VERSION "created by canmatrix"

NS_ :

BS_:

BU_: DiagTool_OBD1 DiwaNXT EBS IRCS MulticII NBM VCM ETS NODE_45 FCCU DICO SGW2 HV_BOX ADCU AEBS DTCO MBMS SGW TPMS ACU CAID2 ELC5_Fr ELC5_Rr PredictiveVirtualNode2 BPU_3 Servo_dir_Turolla PCM NODE_90 NODE_91 NODE_92 RSRRM FCU DSE_VirtualNode2 DSE_VirtualNode40 DSE_VirtualNode38 DSE_VirtualNode49 DSE_VirtualNode48 DSE_VirtualNode39 DSE_VirtualNode37 DSE_VirtualNode36 BSM_B8 BPU_2 DSE_VirtualNode35 DSE_VirtualNode34 RADAR_ACC DSE_VirtualNode33 DSE_VirtualNode41 NODE_BE DSE_VirtualNode32 DSE_VirtualNode4 BSM_C0 BPU_1 DSE_VirtualNode31 DSE_VirtualNode29 DSE_VirtualNode28 MCDS DSE_VirtualNode44 DSE_VirtualNode27 DSE_VirtualNode26 BSM_C8 ALM DSE_VirtualNode25 DSE_VirtualNode50 DSE_VirtualNode47 DSE_VirtualNode46 DSE_VirtualNode23 DSE_VirtualNode51 ScanTool DSE_VirtualNode22 DSE_VirtualNode21 AePTO DC_VirtualNode1 DSE_VirtualNode43 MCSL DSE_VirtualNode1 DSE_VirtualNode42 PredictiveVirtualNode3 DSE_VirtualNode20 DSE_VirtualNode19 DSE_VirtualNode18 DSE_VirtualNode17 DSE_VirtualNode16 DSE_VirtualNode15 NODE_F9 DiagTool DSE_VirtualNode14 DSE_VirtualNode13 DSE_VirtualNode12 DSE_VirtualNode11 DSE_VirtualNode10 DSE_VirtualNode9 DSE_VirtualNode8 DSE_VirtualNode7 DSE_VirtualNode6 Mirror DSE_VirtualNode5 SAS DC_VirtualNode2 PredictiveVirtualNode1 DSE_VirtualNode45 ELFA3 EM_PTO RM CANAIR SWI

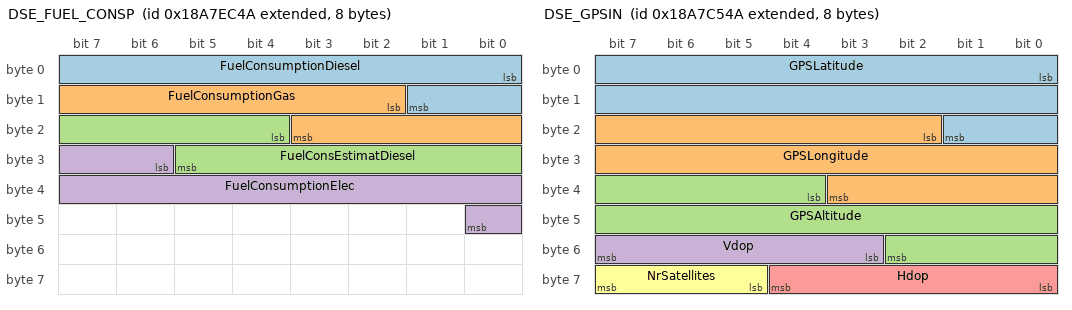
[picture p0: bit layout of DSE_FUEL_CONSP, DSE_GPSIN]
BO_ 2561141834 DSE_FUEL_CONSP: 8 PCM
 SG_ FuelConsumptionDiesel : 0|10@1+ (0.1,-1) [-1|101] "L/100km"  MCDS
 SG_ FuelConsumptionGas : 10|10@1+ (0.1,-1) [-1|101] "Kg/100km"  MCDS
 SG_ FuelConsEstimatDiesel : 20|10@1+ (0.1,-1) [-1|101] "L/100km"  MCDS
 SG_ FuelConsumptionElec : 30|11@1+ (0.1,-1) [-1|203] "kWh/100km"  MCDS

BO_ 2561131850 DSE_GPSIN: 8 PCM
 SG_ GPSLatitude : 0|18@1- (0.001,0) [-131|131] ""  DSE_VirtualNode44
 SG_ GPSLongitude : 18|18@1- (0.0015,0) [-196|196] ""  DSE_VirtualNode44
 SG_ GPSAltitude : 36|15@1+ (0.2,-500) [-500|5797] ""  DSE_VirtualNode44
 SG_ Vdop : 51|5@1+ (1,0) [0|25] ""  DSE_VirtualNode44
 SG_ Hdop : 56|5@1+ (1,0) [0|25] ""  DSE_VirtualNode44
 SG_ NrSatellites : 61|3@1+ (1,0) [0|7] ""  DSE_VirtualNode44

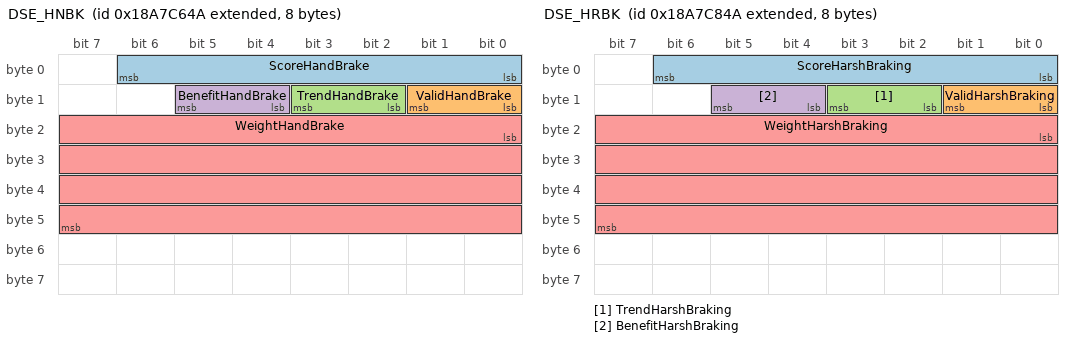
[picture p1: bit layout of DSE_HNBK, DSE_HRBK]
BO_ 2561132106 DSE_HNBK: 8 PCM
 SG_ ScoreHandBrake : 0|7@1+ (1,-1) [-1|126] "Index"  DSE_VirtualNode27
 SG_ ValidHandBrake : 8|2@1+ (1,0) [0|3] ""  DSE_VirtualNode27
 SG_ TrendHandBrake : 10|2@1+ (1,-1) [-1|2] ""  DSE_VirtualNode27
 SG_ BenefitHandBrake : 12|2@1+ (1,0) [0|3] ""  DSE_VirtualNode27
 SG_ WeightHandBrake : 16|32@1+ (1,-1) [-1|4294967294] ""  DSE_VirtualNode27

BO_ 2561132362 DSE_HNBK_DBG: 8 PCM
 SG_ NumEventsHandBrake : 0|16@1+ (1,-1) [-1|65534] ""  DSE_VirtualNode26
 SG_ EventHandBrake : 16|2@1+ (1,0) [0|3] ""  DSE_VirtualNode26

BO_ 2561132618 DSE_HRBK: 8 PCM
 SG_ ScoreHarshBraking : 0|7@1+ (1,-1) [-1|126] "Index"  BSM_C8
 SG_ ValidHarshBraking : 8|2@1+ (1,0) [0|3] ""  BSM_C8
 SG_ TrendHarshBraking : 10|2@1+ (1,-1) [-1|2] ""  BSM_C8
 SG_ BenefitHarshBraking : 12|2@1+ (1,0) [0|3] ""  BSM_C8
 SG_ WeightHarshBraking : 16|32@1+ (1,-1) [-1|4294967294] ""  BSM_C8

BO_ 2561132874 DSE_HRBK_DBG: 8 PCM
 SG_ EvalMetersHarshBraking : 0|16@1+ (1,-1) [-1|65534] "m"  ALM
 SG_ EventHarshBraking : 16|2@1+ (1,0) [0|3] ""  ALM
 SG_ MaxDecelHarshBraking : 18|6@1+ (1,0) [0|63] "kmh/s"  ALM

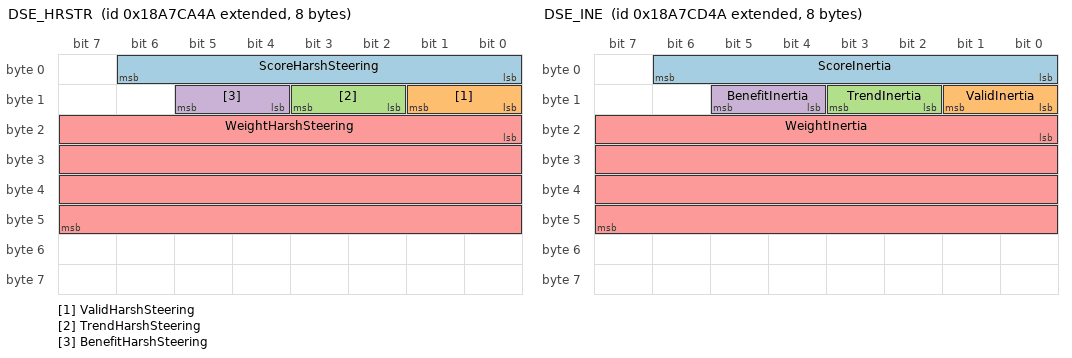
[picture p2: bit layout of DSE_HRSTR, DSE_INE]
BO_ 2561133130 DSE_HRSTR: 8 PCM
 SG_ ScoreHarshSteering : 0|7@1+ (1,-1) [-1|126] "Index"  DSE_VirtualNode25
 SG_ ValidHarshSteering : 8|2@1+ (1,0) [0|3] ""  DSE_VirtualNode25
 SG_ TrendHarshSteering : 10|2@1+ (1,-1) [-1|2] ""  DSE_VirtualNode25
 SG_ BenefitHarshSteering : 12|2@1+ (1,0) [0|3] ""  DSE_VirtualNode25
 SG_ WeightHarshSteering : 16|32@1+ (1,-1) [-1|4294967294] ""  DSE_VirtualNode25

BO_ 2561133386 DSE_HRSTR_DBG: 8 PCM
 SG_ EvalMetersHarshSteering : 0|16@1+ (1,-1) [-1|65534] "m"  DSE_VirtualNode50
 SG_ EventHarshSteering : 16|2@1+ (1,0) [0|3] ""  DSE_VirtualNode50

BO_ 2561133898 DSE_INE: 8 PCM
 SG_ ScoreInertia : 0|7@1+ (1,-1) [-1|126] "Index"  DSE_VirtualNode47
 SG_ ValidInertia : 8|2@1+ (1,0) [0|3] ""  DSE_VirtualNode47
 SG_ TrendInertia : 10|2@1+ (1,-1) [-1|2] ""  DSE_VirtualNode47
 SG_ BenefitInertia : 12|2@1+ (1,0) [0|3] ""  DSE_VirtualNode47
 SG_ WeightInertia : 16|32@1+ (1,-1) [-1|4294967294] ""  DSE_VirtualNode47

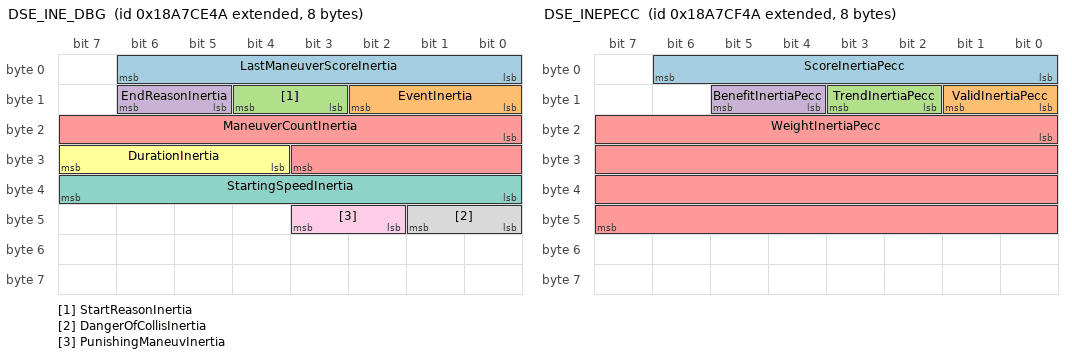
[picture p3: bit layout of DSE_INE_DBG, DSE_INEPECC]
BO_ 2561134154 DSE_INE_DBG: 8 PCM
 SG_ LastManeuverScoreInertia : 0|7@1+ (1,-1) [-1|126] "Index"  DSE_VirtualNode46
 SG_ EventInertia : 8|3@1+ (1,0) [0|7] ""  DSE_VirtualNode46
 SG_ StartReasonInertia : 11|2@1+ (1,0) [0|3] ""  DSE_VirtualNode46
 SG_ EndReasonInertia : 13|2@1+ (1,0) [0|3] ""  DSE_VirtualNode46
 SG_ ManeuverCountInertia : 16|12@1+ (1,-1) [-1|4094] "Count"  DSE_VirtualNode46
 SG_ DurationInertia : 28|4@1+ (1,-1) [-1|14] "s"  DSE_VirtualNode46
 SG_ StartingSpeedInertia : 32|8@1+ (0.5,0) [0|125] "km/h"  DSE_VirtualNode46
 SG_ DangerOfCollisInertia : 40|2@1+ (1,0) [0|3] ""  DSE_VirtualNode46
 SG_ PunishingManeuvInertia : 42|2@1+ (1,0) [0|3] ""  DSE_VirtualNode46

BO_ 2561134410 DSE_INEPECC: 8 PCM
 SG_ ScoreInertiaPecc : 0|7@1+ (1,-1) [-1|126] "Index"  DSE_VirtualNode23
 SG_ ValidInertiaPecc : 8|2@1+ (1,0) [0|3] ""  DSE_VirtualNode23
 SG_ TrendInertiaPecc : 10|2@1+ (1,-1) [-1|2] ""  DSE_VirtualNode23
 SG_ BenefitInertiaPecc : 12|2@1+ (1,0) [0|3] ""  DSE_VirtualNode23
 SG_ WeightInertiaPecc : 16|32@1+ (1,-1) [-1|4294967294] ""  DSE_VirtualNode23

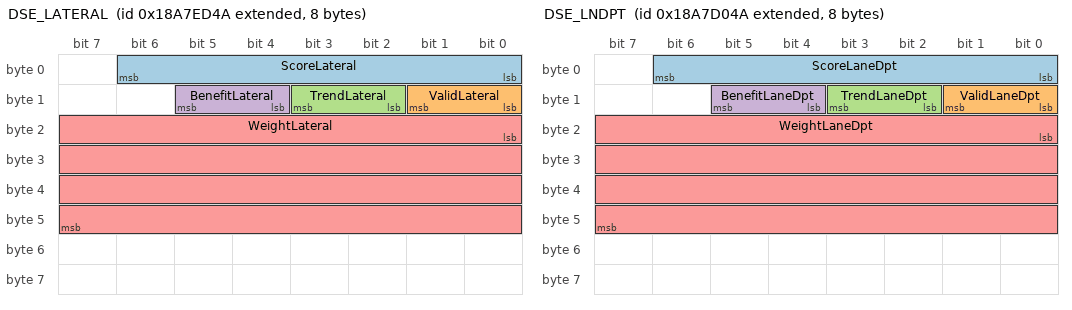
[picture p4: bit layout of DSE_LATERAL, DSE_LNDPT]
BO_ 2561142090 DSE_LATERAL: 8 PCM
 SG_ ScoreLateral : 0|7@1+ (1,0) [0|100] "%"  DSE_VirtualNode51
 SG_ ValidLateral : 8|2@1+ (1,0) [0|3] ""  DSE_VirtualNode51
 SG_ TrendLateral : 10|2@1+ (1,-1) [-1|2] ""  DSE_VirtualNode51
 SG_ BenefitLateral : 12|2@1+ (1,0) [0|3] ""  DSE_VirtualNode51
 SG_ WeightLateral : 16|32@1+ (1,-1) [-1|4294967294] ""  DSE_VirtualNode51

BO_ 2561143114 DSE_LATERAL_DBG: 8 PCM
 SG_ NumEventsLateral : 0|16@1+ (1,-1) [-1|65534] "Count"  ScanTool
 SG_ EvaluatedMetersLateral : 16|16@1+ (1,-1) [-1|65534] "m"  ScanTool

BO_ 2561134666 DSE_LNDPT: 8 PCM
 SG_ ScoreLaneDpt : 0|7@1+ (1,-1) [-1|126] "Index"  DSE_VirtualNode22
 SG_ ValidLaneDpt : 8|2@1+ (1,0) [0|3] ""  DSE_VirtualNode22
 SG_ TrendLaneDpt : 10|2@1+ (1,-1) [-1|2] ""  DSE_VirtualNode22
 SG_ BenefitLaneDpt : 12|2@1+ (1,0) [0|3] ""  DSE_VirtualNode22
 SG_ WeightLaneDpt : 16|32@1+ (1,-1) [-1|4294967294] ""  DSE_VirtualNode22

BO_ 2561134922 DSE_LNDPT_DBG: 8 PCM
 SG_ EvaluatedSamplesLaneDpt : 0|16@1+ (1,-1) [-1|65534] ""  DSE_VirtualNode21
 SG_ EventLaneDpt : 16|2@1+ (1,0) [0|3] ""  DSE_VirtualNode21

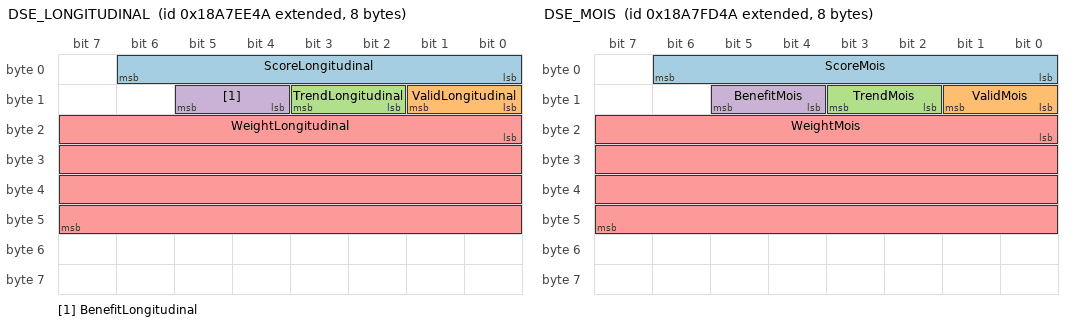
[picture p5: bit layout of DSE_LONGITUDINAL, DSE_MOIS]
BO_ 2561142346 DSE_LONGITUDINAL: 8 PCM
 SG_ ScoreLongitudinal : 0|7@1+ (1,0) [0|100] "%"  DTCO
 SG_ ValidLongitudinal : 8|2@1+ (1,0) [0|3] ""  DTCO
 SG_ TrendLongitudinal : 10|2@1+ (1,-1) [-1|2] ""  DTCO
 SG_ BenefitLongitudinal : 12|2@1+ (1,0) [0|3] ""  DTCO
 SG_ WeightLongitudinal : 16|32@1+ (1,-1) [-1|4294967294] ""  DTCO

BO_ 2561143370 DSE_LONGITUDINAL_DBG: 8 PCM
 SG_ NumEventsLongitudinal : 0|16@1+ (1,-1) [-1|65534] "Count"  AePTO
 SG_ EvalMetersLongitud : 16|16@1+ (1,-1) [-1|65534] "m"  AePTO

BO_ 2561146186 DSE_MOIS: 8 PCM
 SG_ ScoreMois : 0|7@1+ (1,-1) [-1|126] "Index"  DC_VirtualNode1
 SG_ ValidMois : 8|2@1+ (1,0) [0|3] ""  DC_VirtualNode1
 SG_ TrendMois : 10|2@1+ (1,-1) [-1|2] ""  DC_VirtualNode1
 SG_ BenefitMois : 12|2@1+ (1,0) [0|3] ""  DC_VirtualNode1
 SG_ WeightMois : 16|32@1+ (1,-1) [-1|4294967294] ""  DC_VirtualNode1

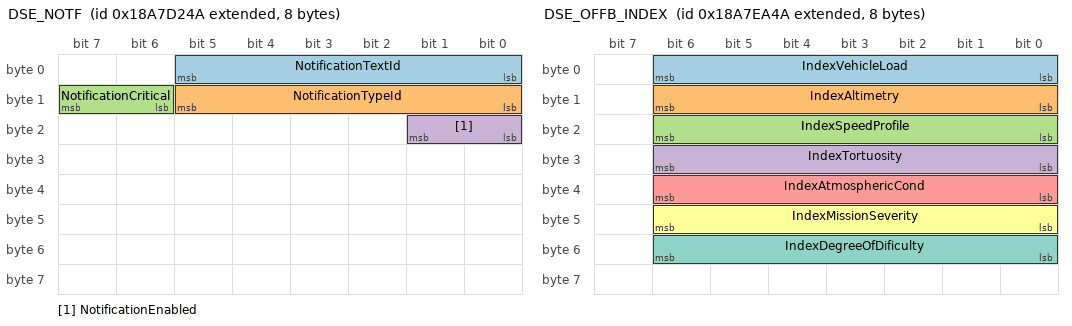
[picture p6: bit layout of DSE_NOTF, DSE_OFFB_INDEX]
BO_ 2561135178 DSE_NOTF: 8 PCM
 SG_ NotificationTextId : 0|6@1+ (1,0) [0|63] ""  DSE_VirtualNode43
 SG_ NotificationTypeId : 8|6@1+ (1,0) [0|63] ""  DSE_VirtualNode43
 SG_ NotificationCritical : 14|2@1+ (1,0) [0|3] ""  DSE_VirtualNode43
 SG_ NotificationEnabled : 16|2@1+ (1,0) [0|3] ""  DSE_VirtualNode43

BO_ 2561141322 DSE_OFFB_INDEX: 8 PCM
 SG_ IndexVehicleLoad : 0|7@1+ (1,-1) [-1|126] "Index"  MCSL
 SG_ IndexAltimetry : 8|7@1+ (1,-1) [-1|126] "Index"  MCSL
 SG_ IndexSpeedProfile : 16|7@1+ (1,-1) [-1|126] "Index"  MCSL
 SG_ IndexTortuosity : 24|7@1+ (1,-1) [-1|126] "Index"  MCSL
 SG_ IndexAtmosphericCond : 32|7@1+ (1,-1) [-1|126] "Index"  MCSL
 SG_ IndexMissionSeverity : 40|7@1+ (1,-1) [-1|126] "Index"  MCSL
 SG_ IndexDegreeOfDificulty : 48|7@1+ (1,-1) [-1|126] "Index"  MCSL

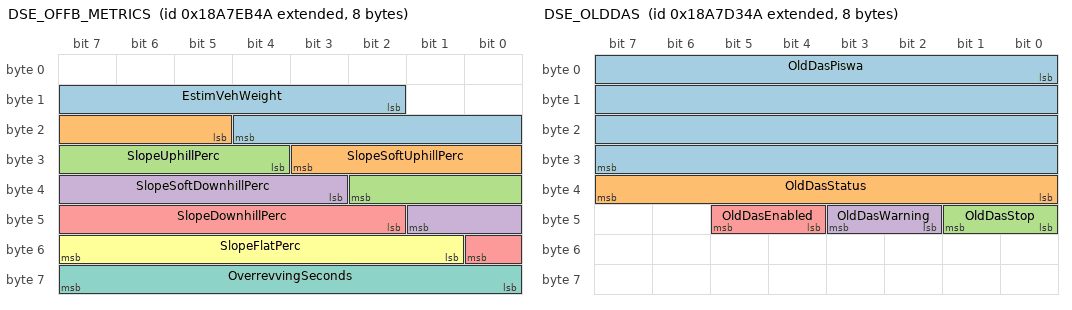
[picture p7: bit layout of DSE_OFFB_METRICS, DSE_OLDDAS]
BO_ 2561141578 DSE_OFFB_METRICS: 8 PCM
 SG_ EstimVehWeight : 10|11@1+ (50,-1) [-1|102349] "kg"  DSE_VirtualNode1
 SG_ SlopeSoftUphillPerc : 21|7@1+ (1,-1) [-1|126] "Index"  DSE_VirtualNode1
 SG_ SlopeUphillPerc : 28|7@1+ (1,-1) [-1|126] "Index"  DSE_VirtualNode1
 SG_ SlopeSoftDownhillPerc : 35|7@1+ (1,-1) [-1|126] "Index"  DSE_VirtualNode1
 SG_ SlopeDownhillPerc : 42|7@1+ (1,-1) [-1|126] "Index"  DSE_VirtualNode1
 SG_ SlopeFlatPerc : 49|7@1+ (1,-1) [-1|126] "Index"  DSE_VirtualNode1
 SG_ OverrevvingSeconds : 56|8@1+ (1,-1) [-1|254] "s"  DSE_VirtualNode1

BO_ 2561135434 DSE_OLDDAS: 8 PCM
 SG_ OldDasPiswa : 0|32@1- (1,0) [0|4294967294] ""  DSE_VirtualNode42
 SG_ OldDasStatus : 32|8@1+ (1,0) [0|250] ""  DSE_VirtualNode42
 SG_ OldDasStop : 40|2@1+ (1,0) [0|3] ""  DSE_VirtualNode42
 SG_ OldDasWarning : 42|2@1+ (1,0) [0|3] ""  DSE_VirtualNode42
 SG_ OldDasEnabled : 44|2@1+ (1,0) [0|3] ""  DSE_VirtualNode42

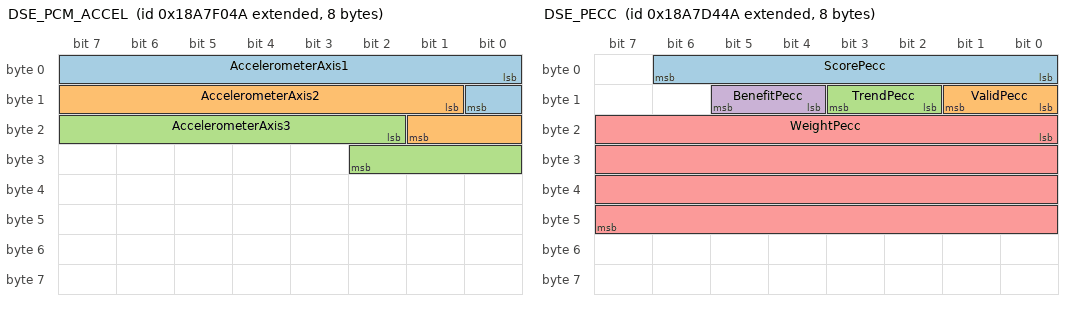
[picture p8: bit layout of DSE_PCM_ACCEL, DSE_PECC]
BO_ 2561142858 DSE_PCM_ACCEL: 8 PCM
 SG_ AccelerometerAxis1 : 0|9@1+ (0.1,-25) [-25|25] "m/s²"  PredictiveVirtualNode3
 SG_ AccelerometerAxis2 : 9|9@1+ (0.1,-25) [-25|25] "m/s²"  PredictiveVirtualNode3
 SG_ AccelerometerAxis3 : 18|9@1+ (0.1,-25) [-25|25] "m/s²"  PredictiveVirtualNode3

BO_ 2561135690 DSE_PECC: 8 PCM
 SG_ ScorePecc : 0|7@1+ (1,-1) [-1|126] "Index"  DSE_VirtualNode20
 SG_ ValidPecc : 8|2@1+ (1,0) [0|3] ""  DSE_VirtualNode20
 SG_ TrendPecc : 10|2@1+ (1,-1) [-1|2] ""  DSE_VirtualNode20
 SG_ BenefitPecc : 12|2@1+ (1,0) [0|3] ""  DSE_VirtualNode20
 SG_ WeightPecc : 16|32@1+ (1,-1) [-1|4294967294] ""  DSE_VirtualNode20

BO_ 2561135946 DSE_PECC_DBG: 8 PCM
 SG_ EvalSamplesPecc : 0|16@1+ (1,-1) [-1|65534] ""  DSE_VirtualNode19
 SG_ EventPecc : 16|2@1+ (1,0) [0|3] ""  DSE_VirtualNode19

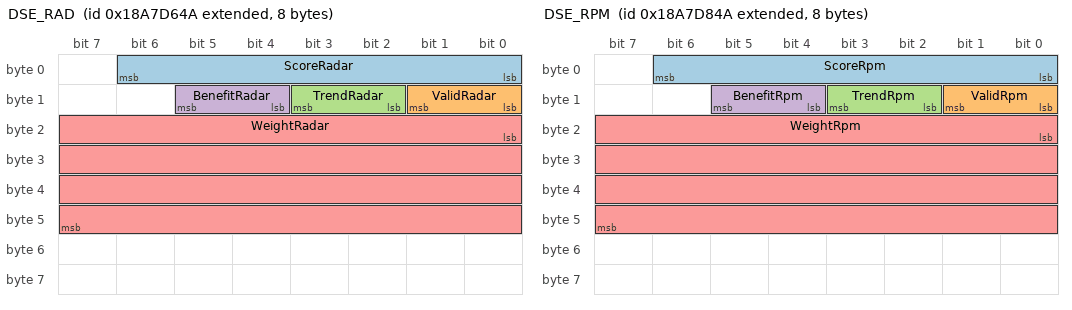
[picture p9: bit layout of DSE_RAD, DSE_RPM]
BO_ 2561136202 DSE_RAD: 8 PCM
 SG_ ScoreRadar : 0|7@1+ (1,-1) [-1|126] "Index"  DSE_VirtualNode18
 SG_ ValidRadar : 8|2@1+ (1,0) [0|3] ""  DSE_VirtualNode18
 SG_ TrendRadar : 10|2@1+ (1,-1) [-1|2] ""  DSE_VirtualNode18
 SG_ BenefitRadar : 12|2@1+ (1,0) [0|3] ""  DSE_VirtualNode18
 SG_ WeightRadar : 16|32@1+ (1,-1) [-1|4294967294] ""  DSE_VirtualNode18

BO_ 2561136458 DSE_RAD_DBG: 8 PCM
 SG_ EvalSamplesRadar : 0|16@1+ (1,-1) [-1|65534] ""  DSE_VirtualNode17
 SG_ EventRadar : 16|2@1+ (1,0) [0|3] ""  DSE_VirtualNode17

BO_ 2561136714 DSE_RPM: 8 PCM
 SG_ ScoreRpm : 0|7@1+ (1,-1) [-1|126] "Index"  DSE_VirtualNode16
 SG_ ValidRpm : 8|2@1+ (1,0) [0|3] ""  DSE_VirtualNode16
 SG_ TrendRpm : 10|2@1+ (1,-1) [-1|2] ""  DSE_VirtualNode16
 SG_ BenefitRpm : 12|2@1+ (1,0) [0|3] ""  DSE_VirtualNode16
 SG_ WeightRpm : 16|32@1+ (1,-1) [-1|4294967294] ""  DSE_VirtualNode16

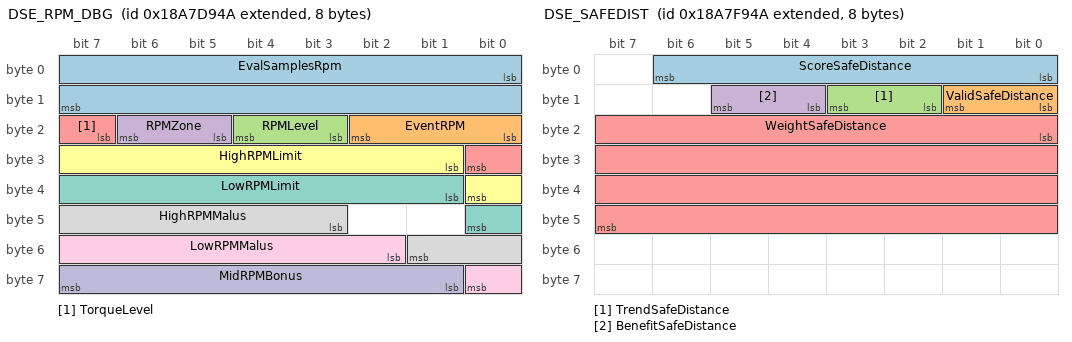
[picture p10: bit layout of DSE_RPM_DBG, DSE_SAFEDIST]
BO_ 2561136970 DSE_RPM_DBG: 8 PCM
 SG_ EvalSamplesRpm : 0|16@1+ (1,-1) [-1|65534] ""  DSE_VirtualNode15
 SG_ EventRPM : 16|3@1+ (1,0) [0|7] ""  DSE_VirtualNode15
 SG_ RPMLevel : 19|2@1+ (1,0) [0|3] ""  DSE_VirtualNode15
 SG_ RPMZone : 21|2@1+ (1,0) [0|3] ""  DSE_VirtualNode15
 SG_ TorqueLevel : 23|2@1+ (1,0) [0|3] ""  DSE_VirtualNode15
 SG_ HighRPMLimit : 25|8@1+ (10,1000) [1000|3550] "rpm"  DSE_VirtualNode15
 SG_ LowRPMLimit : 33|8@1+ (10,0) [0|2550] "rpm"  DSE_VirtualNode15
 SG_ HighRPMMalus : 43|7@1+ (1,-126) [-126|1] "Index"  DSE_VirtualNode15
 SG_ LowRPMMalus : 50|7@1+ (1,-126) [-126|1] "Index"  DSE_VirtualNode15
 SG_ MidRPMBonus : 57|7@1+ (1,-1) [-1|126] "Index"  DSE_VirtualNode15

BO_ 2561145162 DSE_SAFEDIST: 8 PCM
 SG_ ScoreSafeDistance : 0|7@1+ (1,-1) [-1|126] "Index"  NODE_F9
 SG_ ValidSafeDistance : 8|2@1+ (1,0) [0|3] ""  NODE_F9
 SG_ TrendSafeDistance : 10|2@1+ (1,-1) [-1|2] ""  NODE_F9
 SG_ BenefitSafeDistance : 12|2@1+ (1,0) [0|3] ""  NODE_F9
 SG_ WeightSafeDistance : 16|32@1+ (1,-1) [-1|4294967294] ""  NODE_F9

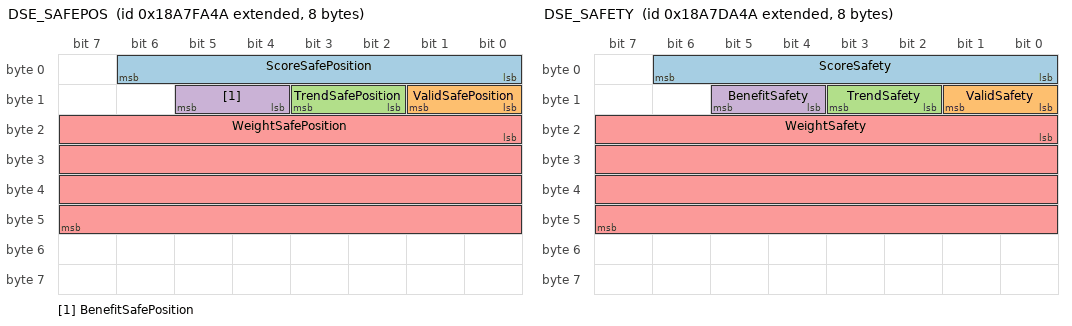
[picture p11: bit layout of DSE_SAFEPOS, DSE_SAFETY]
BO_ 2561145418 DSE_SAFEPOS: 8 PCM
 SG_ ScoreSafePosition : 0|7@1+ (1,-1) [-1|126] "Index"  DiagTool
 SG_ ValidSafePosition : 8|2@1+ (1,0) [0|3] ""  DiagTool
 SG_ TrendSafePosition : 10|2@1+ (1,-1) [-1|2] ""  DiagTool
 SG_ BenefitSafePosition : 12|2@1+ (1,0) [0|3] ""  DiagTool
 SG_ WeightSafePosition : 16|32@1+ (1,-1) [-1|4294967294] ""  DiagTool

BO_ 2561137226 DSE_SAFETY: 8 PCM
 SG_ ScoreSafety : 0|7@1+ (1,-1) [-1|126] "Index"  DSE_VirtualNode14
 SG_ ValidSafety : 8|2@1+ (1,0) [0|3] ""  DSE_VirtualNode14
 SG_ TrendSafety : 10|2@1+ (1,-1) [-1|2] ""  DSE_VirtualNode14
 SG_ BenefitSafety : 12|2@1+ (1,0) [0|3] ""  DSE_VirtualNode14
 SG_ WeightSafety : 16|32@1+ (1,-1) [-1|4294967294] ""  DSE_VirtualNode14

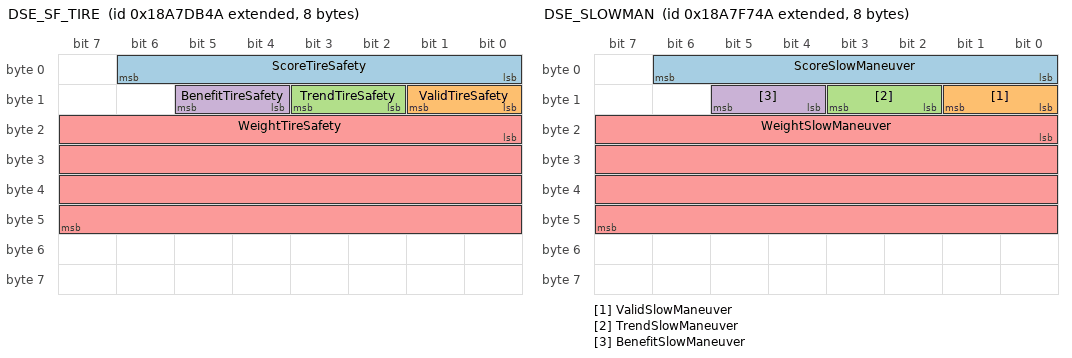
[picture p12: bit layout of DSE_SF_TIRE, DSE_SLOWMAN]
BO_ 2561137482 DSE_SF_TIRE: 8 PCM
 SG_ ScoreTireSafety : 0|7@1+ (1,-1) [-1|126] "Index"  DSE_VirtualNode13
 SG_ ValidTireSafety : 8|2@1+ (1,0) [0|3] ""  DSE_VirtualNode13
 SG_ TrendTireSafety : 10|2@1+ (1,-1) [-1|2] ""  DSE_VirtualNode13
 SG_ BenefitTireSafety : 12|2@1+ (1,0) [0|3] ""  DSE_VirtualNode13
 SG_ WeightTireSafety : 16|32@1+ (1,-1) [-1|4294967294] ""  DSE_VirtualNode13

BO_ 2561137738 DSE_SF_TIRE_DBG: 8 PCM
 SG_ EvalMetersTireSafety : 0|16@1+ (1,-1) [-1|65534] "m"  DSE_VirtualNode12
 SG_ EventTireSafety : 16|2@1+ (1,0) [0|3] ""  DSE_VirtualNode12

BO_ 2561144650 DSE_SLOWMAN: 8 PCM
 SG_ ScoreSlowManeuver : 0|7@1+ (1,-1) [-1|126] "Index"  PredictiveVirtualNode2
 SG_ ValidSlowManeuver : 8|2@1+ (1,0) [0|3] ""  PredictiveVirtualNode2
 SG_ TrendSlowManeuver : 10|2@1+ (1,-1) [-1|2] ""  PredictiveVirtualNode2
 SG_ BenefitSlowManeuver : 12|2@1+ (1,0) [0|3] ""  PredictiveVirtualNode2
 SG_ WeightSlowManeuver : 16|32@1+ (1,-1) [-1|4294967294] ""  PredictiveVirtualNode2

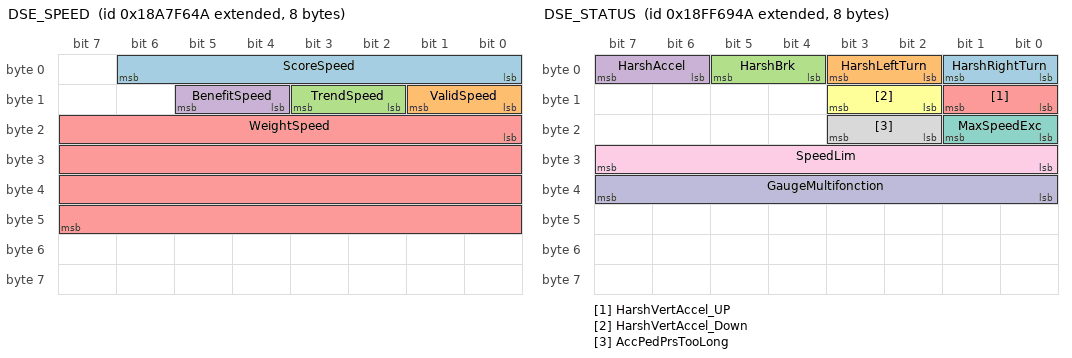
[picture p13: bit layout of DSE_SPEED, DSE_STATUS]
BO_ 2561144394 DSE_SPEED: 8 PCM
 SG_ ScoreSpeed : 0|7@1+ (1,-1) [-1|126] "Index"  BPU_3
 SG_ ValidSpeed : 8|2@1+ (1,0) [0|3] ""  BPU_3
 SG_ TrendSpeed : 10|2@1+ (1,-1) [-1|2] ""  BPU_3
 SG_ BenefitSpeed : 12|2@1+ (1,0) [0|3] ""  BPU_3
 SG_ WeightSpeed : 16|32@1+ (1,-1) [-1|4294967294] ""  BPU_3

BO_ 2561137994 DSE_START: 8 PCM
 SG_ OdometerTripStart : 0|32@1+ (5,-1) [-1|21474836474] "m"  DSE_VirtualNode11
 SG_ TimeStampTripStart : 32|32@1+ (1,946684800) [946684800|4294967294] "Count"  DSE_VirtualNode11

BO_ 2566875466 DSE_STATUS: 8 PCM
 SG_ HarshRightTurn : 0|2@1+ (1,0) [0|3] "" Vector__XXX
 SG_ HarshLeftTurn : 2|2@1+ (1,0) [0|3] "" Vector__XXX
 SG_ HarshBrk : 4|2@1+ (1,0) [0|3] "" Vector__XXX
 SG_ HarshAccel : 6|2@1+ (1,0) [0|3] "" Vector__XXX
 SG_ HarshVertAccel_UP : 8|2@1+ (1,0) [0|3] "" Vector__XXX
 SG_ HarshVertAccel_Down : 10|2@1+ (1,0) [0|3] "" Vector__XXX
 SG_ MaxSpeedExc : 16|2@1+ (1,0) [0|3] "" Vector__XXX
 SG_ AccPedPrsTooLong : 18|2@1+ (1,0) [0|3] "" Vector__XXX
 SG_ SpeedLim : 24|8@1+ (1,0) [0|250] "km/h" Vector__XXX
 SG_ GaugeMultifonction : 32|8@1+ (0.4,0) [0|100] "%" Vector__XXX

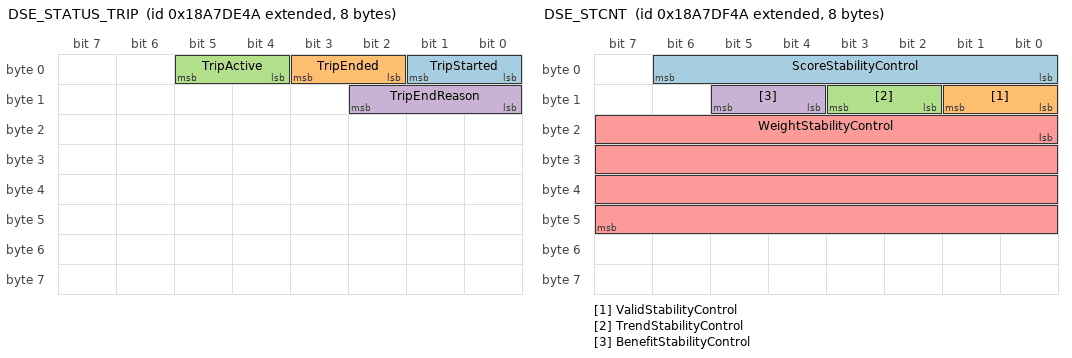
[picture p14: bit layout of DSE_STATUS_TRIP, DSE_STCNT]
BO_ 2561138250 DSE_STATUS_TRIP: 8 PCM
 SG_ TripStarted : 0|2@1+ (1,0) [0|3] ""  DSE_VirtualNode10
 SG_ TripEnded : 2|2@1+ (1,0) [0|3] ""  DSE_VirtualNode10
 SG_ TripActive : 4|2@1+ (1,0) [0|3] ""  DSE_VirtualNode10
 SG_ TripEndReason : 8|3@1+ (1,0) [0|7] ""  DSE_VirtualNode10

BO_ 2561138506 DSE_STCNT: 8 PCM
 SG_ ScoreStabilityControl : 0|7@1+ (1,-1) [-1|126] "Index"  DSE_VirtualNode9
 SG_ ValidStabilityControl : 8|2@1+ (1,0) [0|3] ""  DSE_VirtualNode9
 SG_ TrendStabilityControl : 10|2@1+ (1,-1) [-1|2] ""  DSE_VirtualNode9
 SG_ BenefitStabilityControl : 12|2@1+ (1,0) [0|3] ""  DSE_VirtualNode9
 SG_ WeightStabilityControl : 16|32@1+ (1,-1) [-1|4294967294] ""  DSE_VirtualNode9

BO_ 2561138762 DSE_STCNT_DBG: 8 PCM
 SG_ EvalMetersStabilityCtrl : 0|16@1+ (1,-1) [-1|65534] ""  DSE_VirtualNode8
 SG_ EventStabilityControl : 16|2@1+ (1,0) [0|3] ""  DSE_VirtualNode8

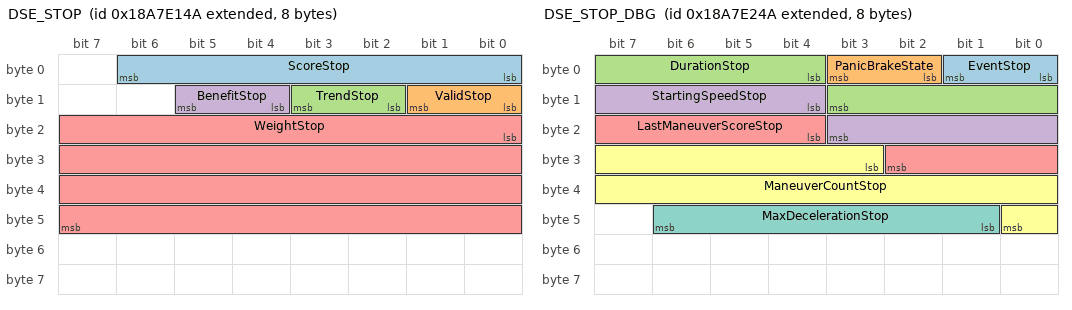
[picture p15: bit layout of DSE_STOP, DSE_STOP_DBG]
BO_ 2561139018 DSE_STOP: 8 PCM
 SG_ ScoreStop : 0|7@1+ (1,-1) [-1|126] "Index"  DSE_VirtualNode7
 SG_ ValidStop : 8|2@1+ (1,0) [0|3] ""  DSE_VirtualNode7
 SG_ TrendStop : 10|2@1+ (1,-1) [-1|2] ""  DSE_VirtualNode7
 SG_ BenefitStop : 12|2@1+ (1,0) [0|3] ""  DSE_VirtualNode7
 SG_ WeightStop : 16|32@1+ (1,-1) [-1|4294967294] ""  DSE_VirtualNode7

BO_ 2561139274 DSE_STOP_DBG: 8 PCM
 SG_ EventStop : 0|2@1+ (1,0) [0|3] ""  DSE_VirtualNode6
 SG_ PanicBrakeState : 2|2@1+ (1,0) [0|3] ""  DSE_VirtualNode6
 SG_ DurationStop : 4|8@1+ (1,-1) [-1|254] "s"  DSE_VirtualNode6
 SG_ StartingSpeedStop : 12|8@1+ (0.5,0) [0|127] "km/h"  DSE_VirtualNode6
 SG_ LastManeuverScoreStop : 20|7@1+ (1,-1) [-1|126] "Index"  DSE_VirtualNode6
 SG_ ManeuverCountStop : 27|14@1+ (1,-1) [-1|16382] "Count"  DSE_VirtualNode6
 SG_ MaxDecelerationStop : 41|6@1+ (1,0) [0|63] "kmh/s"  DSE_VirtualNode6

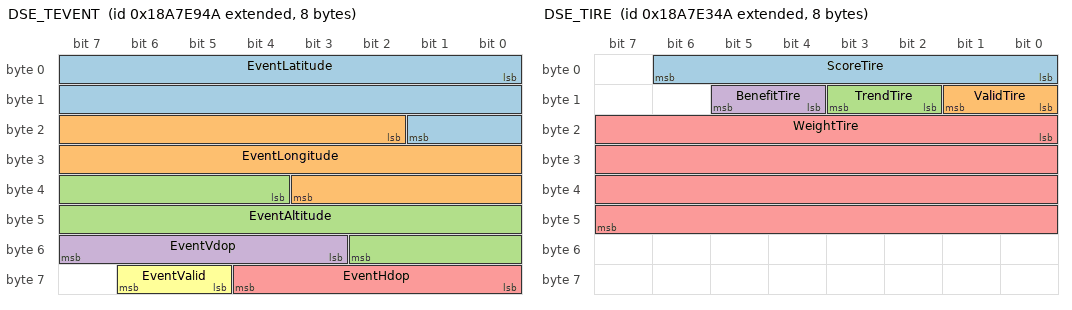
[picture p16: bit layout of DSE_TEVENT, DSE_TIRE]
BO_ 2561141066 DSE_TEVENT: 8 PCM
 SG_ EventLatitude : 0|18@1+ (0.001,-131) [-131|131] ""  Mirror
 SG_ EventLongitude : 18|18@1+ (0.0015,-196) [-196|196] ""  Mirror
 SG_ EventAltitude : 36|15@1+ (0.2,-500) [-500|6053] ""  Mirror
 SG_ EventVdop : 51|5@1+ (1,0) [0|25] ""  Mirror
 SG_ EventHdop : 56|5@1+ (1,0) [0|25] ""  Mirror
 SG_ EventValid : 61|2@1+ (1,0) [0|3] ""  Mirror

BO_ 2561139530 DSE_TIRE: 8 PCM
 SG_ ScoreTire : 0|7@1+ (1,-1) [-1|126] "Index"  DSE_VirtualNode5
 SG_ ValidTire : 8|2@1+ (1,0) [0|3] ""  DSE_VirtualNode5
 SG_ TrendTire : 10|2@1+ (1,-1) [-1|2] ""  DSE_VirtualNode5
 SG_ BenefitTire : 12|2@1+ (1,0) [0|3] ""  DSE_VirtualNode5
 SG_ WeightTire : 16|32@1+ (1,-1) [-1|4294967294] ""  DSE_VirtualNode5

BO_ 2561139786 DSE_TIRE_DBG: 8 PCM
 SG_ EvaluatedSamplesTire : 0|16@1+ (1,-1) [-1|65534] ""  SAS
 SG_ EventTireSaving : 16|2@1+ (1,0) [0|3] ""  SAS

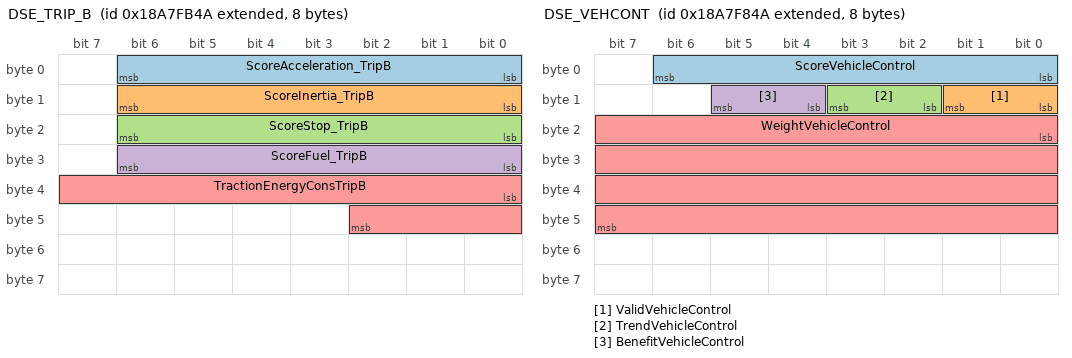
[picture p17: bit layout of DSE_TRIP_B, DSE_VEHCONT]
BO_ 2561145674 DSE_TRIP_B: 8 PCM
 SG_ ScoreAcceleration_TripB : 0|7@1+ (1,-1) [-1|100] "Index"  DC_VirtualNode2
 SG_ ScoreInertia_TripB : 8|7@1+ (1,-1) [-1|100] "Index"  DC_VirtualNode2
 SG_ ScoreStop_TripB : 16|7@1+ (1,-1) [-1|100] "Index"  DC_VirtualNode2
 SG_ ScoreFuel_TripB : 24|7@1+ (1,-1) [-1|100] "Index"  DC_VirtualNode2
 SG_ TractionEnergyConsTripB : 32|11@1+ (0.1,-1) [-1|203] "kWh/100km"  DC_VirtualNode2

BO_ 2561144906 DSE_VEHCONT: 8 PCM
 SG_ ScoreVehicleControl : 0|7@1+ (1,-1) [-1|126] "Index"  PredictiveVirtualNode1
 SG_ ValidVehicleControl : 8|2@1+ (1,0) [0|3] ""  PredictiveVirtualNode1
 SG_ TrendVehicleControl : 10|2@1+ (1,-1) [-1|2] ""  PredictiveVirtualNode1
 SG_ BenefitVehicleControl : 12|2@1+ (1,0) [0|3] ""  PredictiveVirtualNode1
 SG_ WeightVehicleControl : 16|32@1+ (1,-1) [-1|4294967294] ""  PredictiveVirtualNode1

BO_ 2561140298 DSE_VER: 8 PCM
 SG_ VersionMajor : 0|8@1+ (1,-1) [-1|249] ""  DSE_VirtualNode45
 SG_ VersionMinor : 8|8@1+ (1,-1) [-1|249] ""  DSE_VirtualNode45
 SG_ VersionModel : 16|8@1+ (1,-1) [-1|249] ""  DSE_VirtualNode45
 SG_ VersionRevision : 24|8@1+ (1,-1) [-1|249] ""  DSE_VirtualNode45

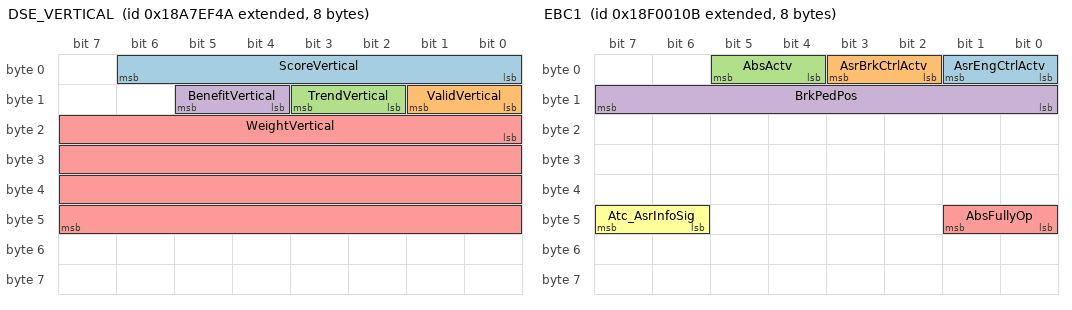
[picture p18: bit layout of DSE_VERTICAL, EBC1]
BO_ 2561142602 DSE_VERTICAL: 8 PCM
 SG_ ScoreVertical : 0|7@1+ (1,0) [0|100] "%"  ELFA3
 SG_ ValidVertical : 8|2@1+ (1,0) [0|3] ""  ELFA3
 SG_ TrendVertical : 10|2@1+ (1,-1) [-1|2] ""  ELFA3
 SG_ BenefitVertical : 12|2@1+ (1,0) [0|3] ""  ELFA3
 SG_ WeightVertical : 16|32@1+ (1,-1) [-1|4294967294] ""  ELFA3

BO_ 2561143626 DSE_VERTICAL_DBG: 8 PCM
 SG_ NumEventsVertical : 0|16@1+ (1,-1) [-1|65534] "Count"  MBMS
 SG_ EvalMetersVertical : 16|16@1+ (1,-1) [-1|65534] "m"  MBMS

BO_ 2565865739 EBC1: 8 EBS
 SG_ AsrEngCtrlActv : 0|2@1+ (1,0) [0|3] ""  PCM
 SG_ AsrBrkCtrlActv : 2|2@1+ (1,0) [0|3] ""  PCM
 SG_ AbsActv : 4|2@1+ (1,0) [0|3] ""  PCM
 SG_ BrkPedPos : 8|8@1+ (0.4,0) [0|100] "%"  PCM
 SG_ AbsFullyOp : 40|2@1+ (1,0) [0|3] ""  PCM
 SG_ Atc_AsrInfoSig : 46|2@1+ (1,0) [0|3] ""  PCM

BO_ 2566831883 EBC2: 8 EBS
 SG_ RelSpeedFaL : 16|8@1+ (0.0625,-7) [-7|7] "km/h"  PCM
 SG_ RelSpeedFaR : 24|8@1+ (0.0625,-7) [-7|7] "km/h"  PCM

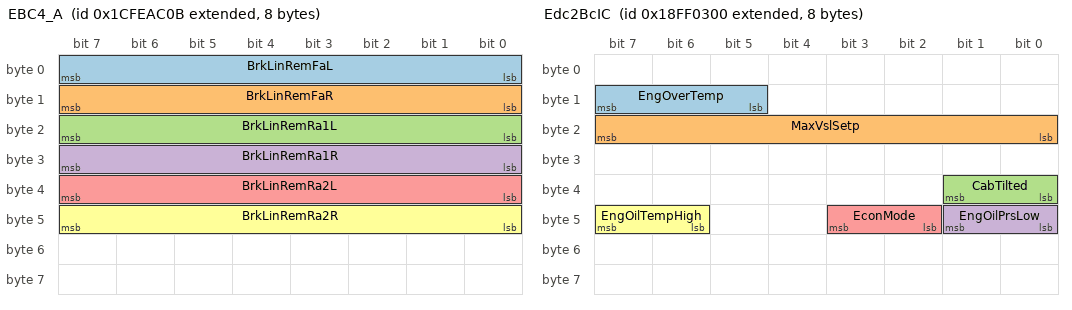
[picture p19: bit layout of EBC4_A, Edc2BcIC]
BO_ 2633935883 EBC4_A: 8 EBS
 SG_ BrkLinRemFaL : 0|8@1+ (0.4,0) [0|100] "%"  PCM
 SG_ BrkLinRemFaR : 8|8@1+ (0.4,0) [0|100] "%"  PCM
 SG_ BrkLinRemRa1L : 16|8@1+ (0.4,0) [0|100] "%"  PCM
 SG_ BrkLinRemRa1R : 24|8@1+ (0.4,0) [0|100] "%"  PCM
 SG_ BrkLinRemRa2L : 32|8@1+ (0.4,0) [0|100] "%"  PCM
 SG_ BrkLinRemRa2R : 40|8@1+ (0.4,0) [0|100] "%"  PCM

BO_ 2566767627 EBC5: 8 EBS
 SG_ HaltBrkMode : 2|3@1+ (1,0) [0|7] ""  PCM
 SG_ HhMode : 5|3@1+ (1,0) [0|7] ""  PCM

BO_ 2566841088 EC1_00_E3: 40 DiagTool_OBD1
 SG_ EngSpeedAtIdlePnt1 : 0|16@1+ (0.125,0) [0|8031] "rpm"  PCM
 SG_ EngSpeedAtHighIdlePnt6 : 120|16@1+ (0.125,0) [0|8031] "rpm"  PCM
 SG_ EngRefTrq : 152|16@1+ (1,0) [0|64255] "Nm"  PCM
 SG_ EngMaxMomOvrSpeedPnt7 : 168|16@1+ (0.125,0) [0|8031] "rpm"  PCM

BO_ 2566841216 EC1_80: 28 HV_BOX
 SG_ EngRefTrq_18FEE380 : 152|16@1+ (1,0) [0|64255] "Nm"  PCM

BO_ 2566891081 ECCU_Inf1: 8 FCCU
 SG_ FccuWifiantennasignalpower : 0|8@1+ (1,-100) [-100|100] "dBm"  PCM
 SG_ FccuCombo2Temp : 8|16@1+ (1,-150) [-150|65383] "°C"  PCM
 SG_ FccuCombo2Lckpositionvoltage : 24|16@1+ (1,0) [0|65535] "mV"  PCM

BO_ 2566889801 ECCU2SCU_49: 8 FCCU
 SG_ ChgIntrp : 8|2@1+ (1,0) [0|3] ""  PCM
 SG_ EvsePresCur : 40|16@1+ (0.1,0) [0|1000] "A"  PCM

BO_ 2566767966 ECU_CAID2: 8 CAID2
 SG_ EcuPn : 0|8@1+ (1,0) [0|255] "ASCII"  PCM
 SG_ EcuSn : 8|8@1+ (1,0) [0|255] "ASCII"  PCM
 SG_ EcuLoc : 16|8@1+ (1,0) [0|255] "ASCII"  PCM
 SG_ EcuManName : 32|8@1+ (1,0) [0|255] "ASCII"  PCM

BO_ 2566767900 ECUID_1C: 1005 PCM
 SG_ EcuPn_18FDC51C : 0|8@1+ (1,0) [0|255] "ASCII" Vector__XXX
 SG_ EcuSn_18FDC51C : 8|8@1+ (1,0) [0|255] "ASCII" Vector__XXX
 SG_ EcuLoc_18FDC51C : 16|8@1+ (1,0) [0|255] "ASCII" Vector__XXX
 SG_ EcuType : 24|8@1+ (1,0) [0|255] "ASCII" Vector__XXX
 SG_ EcuManName_18FDC51C : 32|8@1+ (1,0) [0|255] "ASCII" Vector__XXX

BO_ 2566767901 ECUID_1D: 1005 SGW
 SG_ EcuPn_18FDC51D : 0|8@1+ (1,0) [0|255] "ASCII"  PCM
 SG_ EcuSn_18FDC51D : 8|8@1+ (1,0) [0|255] "ASCII"  PCM
 SG_ EcuLoc_18FDC51D : 16|8@1+ (1,0) [0|255] "ASCII"  PCM
 SG_ EcuType_18FDC51D : 24|8@1+ (1,0) [0|255] "ASCII"  PCM
 SG_ EcuManName_18FDC51D : 32|8@1+ (1,0) [0|255] "ASCII"  PCM

BO_ 2566849280 Edc2BcIC: 8 DiagTool_OBD1
 SG_ EngOverTemp : 13|3@1+ (1,0) [0|7] ""  PCM
 SG_ MaxVslSetp : 16|8@1+ (1,0) [0|250] "km/h"  PCM
 SG_ CabTilted : 32|2@1+ (1,0) [0|3] ""  PCM
 SG_ EngOilPrsLow : 40|2@1+ (1,0) [0|3] ""  PCM
 SG_ EconMode : 42|2@1+ (1,0) [0|3] ""  PCM
 SG_ EngOilTempHigh : 46|2@1+ (1,0) [0|3] ""  PCM

BO_ 2364539904 EEC1: 8 DiagTool_OBD1
 SG_ EngTrqMode : 0|4@1+ (1,0) [0|15] ""  PCM
 SG_ ActEngPcTrq : 16|8@1+ (1,-125) [-125|125] "%"  PCM
 SG_ EngSpeed : 24|16@1+ (0.125,0) [0|8031] "rpm"  PCM
 SG_ EngDemPcTrq : 56|8@1+ (1,-125) [-125|125] "%"  PCM

CM_ BO_ 2561141834 "- DSE Functionnality. Message sent for debugging on the CAN Telem";
CM_ BO_ 2561131850 "- DSE Functionnality. Message sent for debugging on the CAN Telem";
CM_ BO_ 2561132106 "- DSE Functionnality. Message sent for debugging on the CAN Telem";
CM_ BO_ 2561132362 "- DSE Functionnality. Message sent for debugging on the CAN Telem";
CM_ BO_ 2561132618 "- DSE Functionnality. Message sent for debugging on the CAN Telem";
CM_ BO_ 2561132874 "- DSE Functionnality. Message sent for debugging on the CAN Telem";
CM_ BO_ 2561133130 "- DSE Functionnality. Message sent for debugging on the CAN Telem";
CM_ BO_ 2561133386 "- DSE Functionnality. Message sent for debugging on the CAN Telem";
CM_ BO_ 2561133898 "- DSE Functionnality. Message sent for debugging on the CAN Telem";
CM_ BO_ 2561134154 "- DSE Functionnality. Message sent for debugging on the CAN Telem";
CM_ BO_ 2561134410 "- DSE Functionnality. Message sent for debugging on the CAN Telem";
CM_ BO_ 2561142090 "- DSE Functionnality. Message sent for debugging on the CAN Telem";
CM_ BO_ 2561143114 "- DSE Functionnality. Message sent for debugging on the CAN Telem";
CM_ BO_ 2561134666 "- DSE Functionnality. Message sent for debugging on the CAN Telem";
CM_ BO_ 2561134922 "- DSE Functionnality. Message sent for debugging on the CAN Telem";
CM_ BO_ 2561142346 "- DSE Functionnality. Message sent for debugging on the CAN Telem";
CM_ BO_ 2561143370 "- DSE Functionnality. Message sent for debugging on the CAN Telem";
CM_ BO_ 2561146186 "- DSE Functionnality. Message sent for debugging on the CAN Telem";
CM_ BO_ 2561135178 "- DSE Functionnality. Message sent for debugging on the CAN Telem";
CM_ BO_ 2561141322 "- DSE Functionnality. Message sent for debugging on the CAN Telem";
CM_ BO_ 2561141578 "- DSE Functionnality. Message sent for debugging on the CAN Telem";
CM_ BO_ 2561135434 "- DSE Functionnality. Message sent for debugging on the CAN Telem";
CM_ SG_ 2561135434 OldDasPiswa "- Value Type: IEEE Float --> Signed. To be tested if ok or needed Unsigned.";
CM_ SG_ 2561135434 OldDasEnabled "- Value Type: Signed --> Unsigned";
CM_ BO_ 2561142858 "- DSE Functionnality. Message sent for debugging on the CAN Telem";
CM_ SG_ 2561142858 AccelerometerAxis1 "- Offset changed: 0--> -25.55. To be tested";
CM_ SG_ 2561142858 AccelerometerAxis2 "- Offset changed: 0--> -25.55. To be tested";
CM_ SG_ 2561142858 AccelerometerAxis3 "- Offset changed: 0--> -25.55. To be tested";
CM_ BO_ 2561135690 "- DSE Functionnality. Message sent for debugging on the CAN Telem";
CM_ BO_ 2561135946 "- DSE Functionnality. Message sent for debugging on the CAN Telem";
CM_ BO_ 2561136202 "- DSE Functionnality. Message sent for debugging on the CAN Telem";
CM_ BO_ 2561136458 "- DSE Functionnality. Message sent for debugging on the CAN Telem";
CM_ BO_ 2561136714 "- DSE Functionnality. Message sent for debugging on the CAN Telem";
CM_ BO_ 2561136970 "- DSE Functionnality. Message sent for debugging on the CAN Telem";
CM_ BO_ 2561145162 "- DSE Functionnality. Message sent for debugging on the CAN Telem";
CM_ BO_ 2561145418 "- DSE Functionnality. Message sent for debugging on the CAN Telem";
CM_ BO_ 2561137226 "- DSE Functionnality. Message sent for debugging on the CAN Telem";
CM_ BO_ 2561137482 "- DSE Functionnality. Message sent for debugging on the CAN Telem";
CM_ BO_ 2561137738 "- DSE Functionnality. Message sent for debugging on the CAN Telem";
CM_ BO_ 2561144650 "- DSE Functionnality. Message sent for debugging on the CAN Telem";
CM_ BO_ 2561144394 "- DSE Functionnality. Message sent for debugging on the CAN Telem";
CM_ BO_ 2561137994 "- DSE Functionnality. Message sent for debugging on the CAN Telem";
CM_ BO_ 2566875466 "- Blue pictograms displayed at the top right corner above the vehicle speed on the cluster";
CM_ BO_ 2561138250 "- DSE Functionnality";
CM_ BO_ 2561138506 "- DSE Functionnality. Message sent for debugging on the CAN Telem";
CM_ BO_ 2561138762 "- DSE Functionnality. Message sent for debugging on the CAN Telem";
CM_ BO_ 2561139018 "- DSE Functionnality. Message sent for debugging on the CAN Telem";
CM_ BO_ 2561139274 "- DSE Functionnality. Message sent for debugging on the CAN Telem";
CM_ BO_ 2561141066 "- DSE Functionnality. Message sent for debugging on the CAN Telem";
CM_ BO_ 2561139530 "- DSE Functionnality. Message sent for debugging on the CAN Telem";
CM_ BO_ 2561139786 "- DSE Functionnality. Message sent for debugging on the CAN Telem";
CM_ BO_ 2561145674 "- DSE Functionnality";
CM_ BO_ 2561144906 "- DSE Functionnality. Message sent for debugging on the CAN Telem";
CM_ BO_ 2561140298 "- DSE Functionnality. Message sent for debugging on the CAN Telem";
CM_ BO_ 2561142602 "- DSE Functionnality. Message sent for debugging on the CAN Telem";
CM_ BO_ 2561143626 "- DSE Functionnality. Message sent for debugging on the CAN Telem";
CM_ BO_ 2565865739 "- DR.ZF.RM.INT.3..VDB: only message timeout is monitored";
CM_ BO_ 2566831883 "- Full elec: Timeout (ms): 250 ms
- BC.A.BCM..24.CwDG.VDB: Only for ESS without AEBS.
- BC.A.BCM..24.CwFE.VDB: Only for ESS without AEBS.
- BC.A.BCM..24.GxFE.VDB: Only for ESS without AEBS.
- BC.A.BCM..24.UwDG.VDB: Only for ESS without AEBS.";
CM_ SG_ 2566831883 RelSpeedFaL "- CUC.C.PCM..3..TELEM: Predisposal_";
CM_ SG_ 2566831883 RelSpeedFaR "- CUC.C.PCM..3..TELEM: Predisposal_";
CM_ BO_ 2633935883 "- Only valid if no faster OnRequest requests are sollicitated";
CM_ SG_ 2633935883 BrkLinRemRa2L "- 18 meter vehicle";
CM_ SG_ 2633935883 BrkLinRemRa2R "- 18 meter vehicle";
CM_ BO_ 2566767627 "- Not used for Bus ACC, as no XBR_ACC.
- BC.A.BCM..24.CwDG.VDB: Only for ESS without AEBS
- BC.A.BCM..24.CwFE.VDB: Only for ESS without AEBS
- BC.A.BCM..24.GxFE.VDB: Only for ESS without AEBS
- BC.A.BCM..24.UwDG.VDB: Only for ESS without AEBS
- CUC.C.PCM..3..TELEM: Predisposal
- MC.A.VCU..24..VDB: Only Gx (ELFA2).
- MC.W.VCM.4.24..VDB: Used by VCM for adaptive cruise control.";
CM_ SG_ 2566767627 HaltBrkMode "- EBC.KB.BSM..23..VDB: R.S: This signal is used by function Bus Stop Brake (Door Brake).
- MC.A.VCU..24..VDB: Only Gx (ELFA2)";
CM_ SG_ 2566767627 HhMode "- MC.A.VCU..24..VDB: Only Gx (ELFA2)";
CM_ BO_ 2566841088 "- Message Length: 34/40 bytes, depending on the application.
-  Multipacket message handled by SAE Transport Protocol (J1939/21, par 5.10, Multipacket Broadcast with TP.CM/BAM, TP.DT).";
CM_ BO_ 2566841216 "- Specific to Siemens Full Elec vehicles. 2000ms in messagerie ELFA3 _ 1000ms in messagerie BAE.";
CM_ BO_ 2566891081 "- Specific to Siemens Full Elec vehicles. Only for case FCCU.";
CM_ BO_ 2566889801 "- Specific Full Elec";
CM_ SG_ 2566889801 ChgIntrp "- The charger sends a message to the VCU informing of an interruption of charging (stop button on charger), This is not currently included as default";
CM_ SG_ 2566889801 EvsePresCur "- The ground station current at the charger so the VCU can determine whether it is safe to charge, Not required for integration build";
CM_ BO_ 2566767966 "- Multipacket message handled by SAE Transport Protocol (J1939/21, par 5.10, Multipacket Broadcast with TP.CM/BAM, TP.DT)
-  Transport Protocol with Control Flow  (RTS, CTS, EndOfMsgAck, Conn_Abort) shall be also supported by the receiver if the multipacket message has been solicited by a Destination Specific Request
-  Variable Message Length, maximum value used for dbc generation";
CM_ SG_ 2566767966 EcuPn "- 15+1 characters maximum_ Iveco assigned ECU Hw+Sw P/N (CNHI Std. 18-2253)
-  Variable signal length, 8 bits used for dbc generation only";
CM_ SG_ 2566767966 EcuSn "- 10+1 characters maximum_ Manufacturer assigned (CNHI Std. 18-2253)
-  Variable signal length, 8 bits used for dbc generation only";
CM_ SG_ 2566767966 EcuLoc "- 10+1 characters maximum_ concatenation of Subnetwork Identifiers Hex number in ASCII (CNHI Std. 18-2254)
-  Variable signal length, 8 bits used for dbc generation only";
CM_ SG_ 2566767966 EcuManName "- 15+1 characters maximum, (CNHI Std. 18-2253)
-  Variable signal length, 8 bits used for dbc generation only";
CM_ BO_ 2566767900 "- Multipacket message handled by SAE Transport Protocol (J1939/21, par 5.10, Multipacket Broadcast with TP.CM/BAM, TP.DT)
-  Transport Protocol Packets (TP.CM, TP.DT) Priority=7
-  Transport Protocol with Control Flow  (RTS, CTS, EndOfMsgAck, Conn_Abort) shall be also supported by the receiver if the multipacket message has been solicited by a Destination Specific Request
-  Variable Message Length, maximum value used for dbc generation";
CM_ SG_ 2566767900 EcuPn_18FDC51C "- 15+1 characters maximum_ Iveco assigned ECU Hw+Sw P/N (CNHI Std. 18-2253)
-  Variable signal length, 8 bits used for dbc generation only";
CM_ SG_ 2566767900 EcuSn_18FDC51C "- 10+1 characters maximum_ Manufacturer assigned (CNHI Std. 18-2253)
-  Variable signal length, 8 bits used for dbc generation only";
CM_ SG_ 2566767900 EcuLoc_18FDC51C "- 10+1 characters maximum_ concatenation of Subnetwork Identifiers Hex number in ASCII (CNHI Std. 18-2254)
-  Variable signal length, 8 bits used for dbc generation only";
CM_ SG_ 2566767900 EcuType "- 1 character, Empty field, delimiter only (CNHI Std. 18-2253)";
CM_ SG_ 2566767900 EcuManName_18FDC51C "- 15+1 characters maximum, (CNHI Std. 18-2253)
-  Variable signal length, 8 bits used for dbc generation only";
CM_ BO_ 2566767901 "- Multipacket message handled by SAE Transport Protocol (J1939/21, par 5.10, Multipacket Broadcast with TP.CM/BAM, TP.DT)
-  Transport Protocol with Control Flow  (RTS, CTS, EndOfMsgAck, Conn_Abort) shall be also supported by the receiver if the multipacket message has been solicited by a Destination Specific Request
-  Variable Message Length, maximum value used for dbc generation";
CM_ SG_ 2566767901 EcuPn_18FDC51D "- 15+1 characters maximum_ Iveco assigned ECU Hw+Sw P/N (CNHI Std. 18-2253)
-  Variable signal length, 8 bits used for dbc generation only";
CM_ SG_ 2566767901 EcuSn_18FDC51D "- 10+1 characters maximum_ Manufacturer assigned (CNHI Std. 18-2253)
-  Variable signal length, 8 bits used for dbc generation only";
CM_ SG_ 2566767901 EcuLoc_18FDC51D "- 10+1 characters maximum_ concatenation of Subnetwork Identifiers Hex number in ASCII (CNHI Std. 18-2254)
-  Variable signal length, 8 bits used for dbc generation only";
CM_ SG_ 2566767901 EcuType_18FDC51D "- 1 character, Empty field, delimiter only (CNHI Std. 18-2253)";
CM_ SG_ 2566767901 EcuManName_18FDC51D "- 15+1 characters maximum, (CNHI Std. 18-2253)
-  Variable signal length, 8 bits used for dbc generation only";
CM_ BO_ 2566849280 "- VCM4 read EDC2BC on Engine CAN with Id 18 FF 21 00 and emit a copy with Id 18 FF 03 00.";
CM_ BO_ 2364539904 "- Broadcasted with modifications";
CM_ SG_ 2364539904 ActEngPcTrq "- FEh in case of error";
CM_ SG_ 2364539904 EngSpeed "- SAE J1939/73 Freeze Frame parameter";
BA_DEF_ BO_  "CI_MsgDefinition" STRING ;
BA_DEF_ BO_  "CI_MsgId" INT 0 2147483647;
BA_DEF_ BO_  "CI_MsgName" STRING ;
BA_DEF_ BO_  "GenMsgCycleTime" INT 0 3600000;
BA_DEF_ BO_  "GenMsgCycleTimeFast" INT 0 3600000;
BA_DEF_ BO_  "GenMsgDelayTime" INT 0 3600000;
BA_DEF_ BO_  "GenMsgILSupport" ENUM  "No","Yes";
BA_DEF_ BO_  "GenMsgNrOfRepetition" INT 0 1000000;
BA_DEF_ BO_  "GenMsgRequestable" INT 0 1;
BA_DEF_ BO_  "GenMsgSendType" ENUM  "cyclic","NotUsed","NotUsed","NotUsed","NotUsed","NotUsed","NotUsed","IfActive","noMsgSendType";
BA_DEF_ BO_  "GenMsgStartDelayTime" INT 0 100000;
BA_DEF_ BO_  "J1939PgAppearanceOnBus" ENUM  "Default","CAN_Extended","CANFD_Extended";
BA_DEF_ BO_  "TpJ1939VarDlc" ENUM  "No","Yes";
BA_DEF_ BO_  "VFrameFormat" ENUM  "StandardCAN","ExtendedCAN","reserved","J1939PG";
BA_DEF_ SG_  "CI_ParId" STRING ;
BA_DEF_ SG_  "CI_SigId" INT 0 2147483647;
BA_DEF_ SG_  "CI_SigName" STRING ;
BA_DEF_ SG_  "GenSigEVName" STRING ;
BA_DEF_ SG_  "GenSigILSupport" ENUM  "No","Yes";
BA_DEF_ SG_  "GenSigInactiveValue" INT 0 2147483647;
BA_DEF_ SG_  "GenSigSendType" ENUM  "Cyclic","OnWrite","OnWriteWithRepetition","OnChange","OnChangeWithRepetition","IfActive","IfActiveWithRepetition","NoSigSendType";
BA_DEF_ SG_  "GenSigStartValue" INT 0 2147483647;
BA_DEF_ SG_  "GenSigTimeoutTime_ACU" INT 0 3600000;
BA_DEF_ SG_  "GenSigTimeoutTime_ADCU" INT 0 3600000;
BA_DEF_ SG_  "GenSigTimeoutTime_CAID" INT 0 3600000;
BA_DEF_ SG_  "GenSigTimeoutTime_CANAIR" INT 0 3600000;
BA_DEF_ SG_  "GenSigTimeoutTime_DICO" INT 0 3600000;
BA_DEF_ SG_  "GenSigTimeoutTime_DTCO" INT 0 3600000;
BA_DEF_ SG_  "GenSigTimeoutTime_DiwaNXT" INT 0 3600000;
BA_DEF_ SG_  "GenSigTimeoutTime_DiwaNXT_MH" INT 0 3600000;
BA_DEF_ SG_  "GenSigTimeoutTime_EBS" INT 0 3600000;
BA_DEF_ SG_  "GenSigTimeoutTime_EBS_" INT 0 3600000;
BA_DEF_ SG_  "GenSigTimeoutTime_EBS__" INT 0 3600000;
BA_DEF_ SG_  "GenSigTimeoutTime_EBS___" INT 0 3600000;
BA_DEF_ SG_  "GenSigTimeoutTime_ELC5_Fr" INT 0 3600000;
BA_DEF_ SG_  "GenSigTimeoutTime_ELFA3" INT 0 3600000;
BA_DEF_ SG_  "GenSigTimeoutTime_ETS" INT 0 3600000;
BA_DEF_ SG_  "GenSigTimeoutTime_Ecolife2" INT 0 3600000;
BA_DEF_ SG_  "GenSigTimeoutTime_FCCU_" INT 0 3600000;
BA_DEF_ SG_  "GenSigTimeoutTime_FMS4" INT 0 3600000;
BA_DEF_ SG_  "GenSigTimeoutTime_HV_BOX" INT 0 3600000;
BA_DEF_ SG_  "GenSigTimeoutTime_INTD" INT 0 3600000;
BA_DEF_ SG_  "GenSigTimeoutTime_IRCS" INT 0 3600000;
BA_DEF_ SG_  "GenSigTimeoutTime_MD1_D" INT 0 3600000;
BA_DEF_ SG_  "GenSigTimeoutTime_MD1_G" INT 0 3600000;
BA_DEF_ SG_  "GenSigTimeoutTime_MTCO" INT 0 3600000;
BA_DEF_ SG_  "GenSigTimeoutTime_MulticII" INT 0 3600000;
BA_DEF_ SG_  "GenSigTimeoutTime_MulticS" INT 0 3600000;
BA_DEF_ SG_  "GenSigTimeoutTime_MulticS_" INT 0 3600000;
BA_DEF_ SG_  "GenSigTimeoutTime_MulticS__" INT 0 3600000;
BA_DEF_ SG_  "GenSigTimeoutTime_NBM" INT 0 3600000;
BA_DEF_ SG_  "GenSigTimeoutTime_NBM_" INT 0 3600000;
BA_DEF_ SG_  "GenSigTimeoutTime_NBM__" INT 0 3600000;
BA_DEF_ SG_  "GenSigTimeoutTime_NBM___" INT 0 3600000;
BA_DEF_ SG_  "GenSigTimeoutTime_PCM" INT 0 3600000;
BA_DEF_ SG_  "GenSigTimeoutTime_SGW" INT 0 3600000;
BA_DEF_ SG_  "GenSigTimeoutTime_SGW2" INT 0 3600000;
BA_DEF_ SG_  "GenSigTimeoutTime_SGW_" INT 0 3600000;
BA_DEF_ SG_  "GenSigTimeoutTime_SGW__" INT 0 3600000;
BA_DEF_ SG_  "GenSigTimeoutTime_SIU" INT 0 3600000;
BA_DEF_ SG_  "GenSigTimeoutTime_SmartRadio" INT 0 3600000;
BA_DEF_ SG_  "GenSigTimeoutTime_TPMS" INT 0 3600000;
BA_DEF_ SG_  "GenSigTimeoutTime_TSU" INT 0 3600000;
BA_DEF_ SG_  "GenSigTimeoutTime_VCM" INT 0 3600000;
BA_DEF_ SG_  "GenSigTimeoutTime_VCM_" INT 0 3600000;
BA_DEF_ SG_  "GenSigTimeoutTime_VCM__" INT 0 3600000;
BA_DEF_ SG_  "GenSigTimeoutTime_VCU" INT 0 3600000;
BA_DEF_ SG_  "GenSigTimeoutTime_VCU_" INT 0 3600000;
BA_DEF_ SG_  "GenSigTimeoutTime_VMU" INT 0 3600000;
BA_DEF_ SG_  "SPN" INT 0 524287;
BA_DEF_ SG_  "SigType" ENUM  "Default","Range","RangeSigned","ASCII","Discrete","Control","ReferencePGN","DTC","StringDelimiter","StringLength","StringLengthControl";
BA_DEF_DEF_  "CI_MsgDefinition" "";
BA_DEF_DEF_  "CI_MsgId" 0;
BA_DEF_DEF_  "CI_MsgName" "";
BA_DEF_DEF_  "GenMsgCycleTime" 0;
BA_DEF_DEF_  "GenMsgCycleTimeFast" 0;
BA_DEF_DEF_  "GenMsgDelayTime" 1;
BA_DEF_DEF_  "GenMsgILSupport" "Yes";
BA_DEF_DEF_  "GenMsgNrOfRepetition" 0;
BA_DEF_DEF_  "GenMsgRequestable" 0;
BA_DEF_DEF_  "GenMsgSendType" "noMsgSendType";
BA_DEF_DEF_  "GenMsgStartDelayTime" 0;
BA_DEF_DEF_  "J1939PgAppearanceOnBus" "Default";
BA_DEF_DEF_  "TpJ1939VarDlc" "No";
BA_DEF_DEF_  "VFrameFormat" "J1939PG";
BA_DEF_DEF_  "CI_ParId" "";
BA_DEF_DEF_  "CI_SigId" 0;
BA_DEF_DEF_  "CI_SigName" "";
BA_DEF_DEF_  "GenSigEVName" "Env@Nodename_@Signame";
BA_DEF_DEF_  "GenSigILSupport" "Yes";
BA_DEF_DEF_  "GenSigInactiveValue" 0;
BA_DEF_DEF_  "GenSigSendType" "NoSigSendType";
BA_DEF_DEF_  "GenSigStartValue" 0;
BA_DEF_DEF_  "GenSigTimeoutTime_ACU" 0;
BA_DEF_DEF_  "GenSigTimeoutTime_ADCU" 0;
BA_DEF_DEF_  "GenSigTimeoutTime_CAID" 0;
BA_DEF_DEF_  "GenSigTimeoutTime_CANAIR" 0;
BA_DEF_DEF_  "GenSigTimeoutTime_DICO" 0;
BA_DEF_DEF_  "GenSigTimeoutTime_DTCO" 0;
BA_DEF_DEF_  "GenSigTimeoutTime_DiwaNXT" 0;
BA_DEF_DEF_  "GenSigTimeoutTime_DiwaNXT_MH" 0;
BA_DEF_DEF_  "GenSigTimeoutTime_EBS" 0;
BA_DEF_DEF_  "GenSigTimeoutTime_EBS_" 0;
BA_DEF_DEF_  "GenSigTimeoutTime_EBS__" 0;
BA_DEF_DEF_  "GenSigTimeoutTime_EBS___" 0;
BA_DEF_DEF_  "GenSigTimeoutTime_ELC5_Fr" 0;
BA_DEF_DEF_  "GenSigTimeoutTime_ELFA3" 0;
BA_DEF_DEF_  "GenSigTimeoutTime_ETS" 0;
BA_DEF_DEF_  "GenSigTimeoutTime_Ecolife2" 0;
BA_DEF_DEF_  "GenSigTimeoutTime_FCCU_" 0;
BA_DEF_DEF_  "GenSigTimeoutTime_FMS4" 0;
BA_DEF_DEF_  "GenSigTimeoutTime_HV_BOX" 0;
BA_DEF_DEF_  "GenSigTimeoutTime_INTD" 0;
BA_DEF_DEF_  "GenSigTimeoutTime_IRCS" 0;
BA_DEF_DEF_  "GenSigTimeoutTime_MD1_D" 0;
BA_DEF_DEF_  "GenSigTimeoutTime_MD1_G" 0;
BA_DEF_DEF_  "GenSigTimeoutTime_MTCO" 0;
BA_DEF_DEF_  "GenSigTimeoutTime_MulticII" 0;
BA_DEF_DEF_  "GenSigTimeoutTime_MulticS" 0;
BA_DEF_DEF_  "GenSigTimeoutTime_MulticS_" 0;
BA_DEF_DEF_  "GenSigTimeoutTime_MulticS__" 0;
BA_DEF_DEF_  "GenSigTimeoutTime_NBM" 0;
BA_DEF_DEF_  "GenSigTimeoutTime_NBM_" 0;
BA_DEF_DEF_  "GenSigTimeoutTime_NBM__" 0;
BA_DEF_DEF_  "GenSigTimeoutTime_NBM___" 0;
BA_DEF_DEF_  "GenSigTimeoutTime_PCM" 0;
BA_DEF_DEF_  "GenSigTimeoutTime_SGW" 0;
BA_DEF_DEF_  "GenSigTimeoutTime_SGW2" 0;
BA_DEF_DEF_  "GenSigTimeoutTime_SGW_" 0;
BA_DEF_DEF_  "GenSigTimeoutTime_SGW__" 0;
BA_DEF_DEF_  "GenSigTimeoutTime_SIU" 0;
BA_DEF_DEF_  "GenSigTimeoutTime_SmartRadio" 0;
BA_DEF_DEF_  "GenSigTimeoutTime_TPMS" 0;
BA_DEF_DEF_  "GenSigTimeoutTime_TSU" 0;
BA_DEF_DEF_  "GenSigTimeoutTime_VCM" 0;
BA_DEF_DEF_  "GenSigTimeoutTime_VCM_" 0;
BA_DEF_DEF_  "GenSigTimeoutTime_VCM__" 0;
BA_DEF_DEF_  "GenSigTimeoutTime_VCU" 0;
BA_DEF_DEF_  "GenSigTimeoutTime_VCU_" 0;
BA_DEF_DEF_  "GenSigTimeoutTime_VMU" 0;
BA_DEF_DEF_  "SPN" 0;
BA_DEF_DEF_  "SigType" "Default";
BA_ "CI_MsgDefinition" BO_ 2561141834 "Iveco Bus Proprietary";
BA_ "CI_MsgId" BO_ 2561141834 14344;
BA_ "CI_MsgName" BO_ 2561141834 "DSE_FUEL_CONSP - DSE Fuel Consumption";
BA_ "GenMsgCycleTime" BO_ 2561141834 1000;
BA_ "GenMsgCycleTimeFast" BO_ 2561141834 1000;
BA_ "GenMsgDelayTime" BO_ 2561141834 500;
BA_ "GenMsgSendType" BO_ 2561141834 0;
BA_ "GenMsgStartDelayTime" BO_ 2561141834 116;
BA_ "CI_MsgDefinition" BO_ 2561131850 "Iveco Bus Proprietary";
BA_ "CI_MsgId" BO_ 2561131850 14349;
BA_ "CI_MsgName" BO_ 2561131850 "DSE_GPSIN - DSE GPSIN";
BA_ "GenMsgCycleTime" BO_ 2561131850 1000;
BA_ "GenMsgCycleTimeFast" BO_ 2561131850 1000;
BA_ "GenMsgDelayTime" BO_ 2561131850 500;
BA_ "GenMsgSendType" BO_ 2561131850 0;
BA_ "GenMsgStartDelayTime" BO_ 2561131850 42;
BA_ "CI_MsgDefinition" BO_ 2561132106 "Iveco Bus Proprietary";
BA_ "CI_MsgId" BO_ 2561132106 14356;
BA_ "CI_MsgName" BO_ 2561132106 "DSE_HNBK - DSE Hand Brake";
BA_ "GenMsgCycleTime" BO_ 2561132106 1000;
BA_ "GenMsgCycleTimeFast" BO_ 2561132106 1000;
BA_ "GenMsgDelayTime" BO_ 2561132106 500;
BA_ "GenMsgSendType" BO_ 2561132106 0;
BA_ "GenMsgStartDelayTime" BO_ 2561132106 44;
BA_ "CI_MsgDefinition" BO_ 2561132362 "Iveco Bus Proprietary";
BA_ "CI_MsgId" BO_ 2561132362 14362;
BA_ "CI_MsgName" BO_ 2561132362 "DSE_HNBK_DBG - DSE Hand Brake DBG";
BA_ "GenMsgCycleTime" BO_ 2561132362 1000;
BA_ "GenMsgCycleTimeFast" BO_ 2561132362 1000;
BA_ "GenMsgDelayTime" BO_ 2561132362 500;
BA_ "GenMsgSendType" BO_ 2561132362 0;
BA_ "GenMsgStartDelayTime" BO_ 2561132362 46;
BA_ "CI_MsgDefinition" BO_ 2561132618 "Iveco Bus Proprietary";
BA_ "CI_MsgId" BO_ 2561132618 14365;
BA_ "CI_MsgName" BO_ 2561132618 "DSE_HRBK - DSE HarshBraking";
BA_ "GenMsgCycleTime" BO_ 2561132618 1000;
BA_ "GenMsgCycleTimeFast" BO_ 2561132618 1000;
BA_ "GenMsgDelayTime" BO_ 2561132618 500;
BA_ "GenMsgSendType" BO_ 2561132618 0;
BA_ "GenMsgStartDelayTime" BO_ 2561132618 48;
BA_ "CI_MsgDefinition" BO_ 2561132874 "Iveco Bus Proprietary";
BA_ "CI_MsgId" BO_ 2561132874 14371;
BA_ "CI_MsgName" BO_ 2561132874 "DSE_HRBK_DBG - DSE HarshBraking DBG";
BA_ "GenMsgCycleTime" BO_ 2561132874 1000;
BA_ "GenMsgCycleTimeFast" BO_ 2561132874 1000;
BA_ "GenMsgDelayTime" BO_ 2561132874 500;
BA_ "GenMsgSendType" BO_ 2561132874 0;
BA_ "GenMsgStartDelayTime" BO_ 2561132874 50;
BA_ "CI_MsgDefinition" BO_ 2561133130 "Iveco Bus Proprietary";
BA_ "CI_MsgId" BO_ 2561133130 14375;
BA_ "CI_MsgName" BO_ 2561133130 "DSE_HRSTR - DSE Harsh Steeering";
BA_ "GenMsgCycleTime" BO_ 2561133130 1000;
BA_ "GenMsgCycleTimeFast" BO_ 2561133130 1000;
BA_ "GenMsgDelayTime" BO_ 2561133130 500;
BA_ "GenMsgSendType" BO_ 2561133130 0;
BA_ "GenMsgStartDelayTime" BO_ 2561133130 52;
BA_ "CI_MsgDefinition" BO_ 2561133386 "Iveco Bus Proprietary";
BA_ "CI_MsgId" BO_ 2561133386 14381;
BA_ "CI_MsgName" BO_ 2561133386 "DSE_HRSTR_DBG - DSE Harsh Steeering DBG";
BA_ "GenMsgCycleTime" BO_ 2561133386 1000;
BA_ "GenMsgCycleTimeFast" BO_ 2561133386 1000;
BA_ "GenMsgDelayTime" BO_ 2561133386 500;
BA_ "GenMsgSendType" BO_ 2561133386 0;
BA_ "GenMsgStartDelayTime" BO_ 2561133386 54;
BA_ "CI_MsgDefinition" BO_ 2561133898 "Iveco Bus Proprietary";
BA_ "CI_MsgId" BO_ 2561133898 14384;
BA_ "CI_MsgName" BO_ 2561133898 "DSE_INE - DSE Inertia";
BA_ "GenMsgCycleTime" BO_ 2561133898 1000;
BA_ "GenMsgCycleTimeFast" BO_ 2561133898 1000;
BA_ "GenMsgDelayTime" BO_ 2561133898 500;
BA_ "GenMsgSendType" BO_ 2561133898 0;
BA_ "GenMsgStartDelayTime" BO_ 2561133898 56;
BA_ "CI_MsgDefinition" BO_ 2561134154 "Iveco Bus Proprietary";
BA_ "CI_MsgId" BO_ 2561134154 14390;
BA_ "CI_MsgName" BO_ 2561134154 "DSE_INE_DBG - DSE Inertia DBG";
BA_ "GenMsgCycleTime" BO_ 2561134154 1000;
BA_ "GenMsgCycleTimeFast" BO_ 2561134154 1000;
BA_ "GenMsgDelayTime" BO_ 2561134154 500;
BA_ "GenMsgSendType" BO_ 2561134154 0;
BA_ "GenMsgStartDelayTime" BO_ 2561134154 58;
BA_ "CI_MsgDefinition" BO_ 2561134410 "Iveco Bus Proprietary";
BA_ "CI_MsgId" BO_ 2561134410 14400;
BA_ "CI_MsgName" BO_ 2561134410 "DSE_INEPECC - DSE Inertia Pecc";
BA_ "GenMsgCycleTime" BO_ 2561134410 1000;
BA_ "GenMsgCycleTimeFast" BO_ 2561134410 1000;
BA_ "GenMsgDelayTime" BO_ 2561134410 500;
BA_ "GenMsgSendType" BO_ 2561134410 0;
BA_ "GenMsgStartDelayTime" BO_ 2561134410 60;
BA_ "CI_MsgDefinition" BO_ 2561142090 "Iveco Bus Proprietary";
BA_ "CI_MsgId" BO_ 2561142090 14406;
BA_ "CI_MsgName" BO_ 2561142090 "DSE_LATERAL - DSE Lateral";
BA_ "GenMsgCycleTime" BO_ 2561142090 1000;
BA_ "GenMsgCycleTimeFast" BO_ 2561142090 1000;
BA_ "GenMsgDelayTime" BO_ 2561142090 500;
BA_ "GenMsgSendType" BO_ 2561142090 0;
BA_ "GenMsgStartDelayTime" BO_ 2561142090 118;
BA_ "CI_MsgDefinition" BO_ 2561143114 "Iveco Bus Proprietary";
BA_ "CI_MsgId" BO_ 2561143114 14412;
BA_ "CI_MsgName" BO_ 2561143114 "DSE_LATERAL_DBG - DSE Lateral DBG";
BA_ "GenMsgCycleTime" BO_ 2561143114 1000;
BA_ "GenMsgCycleTimeFast" BO_ 2561143114 1000;
BA_ "GenMsgDelayTime" BO_ 2561143114 500;
BA_ "GenMsgSendType" BO_ 2561143114 0;
BA_ "GenMsgStartDelayTime" BO_ 2561143114 126;
BA_ "CI_MsgDefinition" BO_ 2561134666 "Iveco Bus Proprietary";
BA_ "CI_MsgId" BO_ 2561134666 14415;
BA_ "CI_MsgName" BO_ 2561134666 "DSE_LNDPT - DSE Lane departure";
BA_ "GenMsgCycleTime" BO_ 2561134666 1000;
BA_ "GenMsgCycleTimeFast" BO_ 2561134666 1000;
BA_ "GenMsgDelayTime" BO_ 2561134666 500;
BA_ "GenMsgSendType" BO_ 2561134666 0;
BA_ "GenMsgStartDelayTime" BO_ 2561134666 62;
BA_ "CI_MsgDefinition" BO_ 2561134922 "Iveco Bus Proprietary";
BA_ "CI_MsgId" BO_ 2561134922 14421;
BA_ "CI_MsgName" BO_ 2561134922 "DSE_LNDPT_DBG - DSE Lane departure DBG";
BA_ "GenMsgCycleTime" BO_ 2561134922 1000;
BA_ "GenMsgCycleTimeFast" BO_ 2561134922 1000;
BA_ "GenMsgDelayTime" BO_ 2561134922 500;
BA_ "GenMsgSendType" BO_ 2561134922 0;
BA_ "GenMsgStartDelayTime" BO_ 2561134922 64;
BA_ "CI_MsgDefinition" BO_ 2561142346 "Iveco Bus Proprietary";
BA_ "CI_MsgId" BO_ 2561142346 14424;
BA_ "CI_MsgName" BO_ 2561142346 "DSE_LONGITUDINAL - DSE Longitudinal";
BA_ "GenMsgCycleTime" BO_ 2561142346 1000;
BA_ "GenMsgCycleTimeFast" BO_ 2561142346 1000;
BA_ "GenMsgDelayTime" BO_ 2561142346 500;
BA_ "GenMsgSendType" BO_ 2561142346 0;
BA_ "GenMsgStartDelayTime" BO_ 2561142346 120;
BA_ "CI_MsgDefinition" BO_ 2561143370 "Iveco Bus Proprietary";
BA_ "CI_MsgId" BO_ 2561143370 14430;
BA_ "CI_MsgName" BO_ 2561143370 "DSE_LONGITUDINAL_DBG - DSE Longitudinal DBG";
BA_ "GenMsgCycleTime" BO_ 2561143370 1000;
BA_ "GenMsgCycleTimeFast" BO_ 2561143370 1000;
BA_ "GenMsgDelayTime" BO_ 2561143370 500;
BA_ "GenMsgSendType" BO_ 2561143370 0;
BA_ "GenMsgStartDelayTime" BO_ 2561143370 128;
BA_ "CI_MsgDefinition" BO_ 2561146186 "Iveco Bus Proprietary";
BA_ "CI_MsgId" BO_ 2561146186 14511;
BA_ "CI_MsgName" BO_ 2561146186 "DSE_MOIS - DSE Mois";
BA_ "GenMsgCycleTime" BO_ 2561146186 1000;
BA_ "GenMsgCycleTimeFast" BO_ 2561146186 1000;
BA_ "GenMsgDelayTime" BO_ 2561146186 500;
BA_ "GenMsgSendType" BO_ 2561146186 0;
BA_ "GenMsgStartDelayTime" BO_ 2561146186 150;
BA_ "CI_MsgDefinition" BO_ 2561135178 "Iveco Bus Proprietary";
BA_ "CI_MsgId" BO_ 2561135178 14517;
BA_ "CI_MsgName" BO_ 2561135178 "DSE_NOTF - DSE Notification";
BA_ "GenMsgCycleTime" BO_ 2561135178 1000;
BA_ "GenMsgCycleTimeFast" BO_ 2561135178 1000;
BA_ "GenMsgDelayTime" BO_ 2561135178 500;
BA_ "GenMsgSendType" BO_ 2561135178 0;
BA_ "GenMsgStartDelayTime" BO_ 2561135178 66;
BA_ "CI_MsgDefinition" BO_ 2561141322 "Iveco Bus Proprietary";
BA_ "CI_MsgId" BO_ 2561141322 14522;
BA_ "CI_MsgName" BO_ 2561141322 "DSE_OFFB_INDEX - DSE OFFB Index";
BA_ "GenMsgCycleTime" BO_ 2561141322 1000;
BA_ "GenMsgCycleTimeFast" BO_ 2561141322 1000;
BA_ "GenMsgDelayTime" BO_ 2561141322 500;
BA_ "GenMsgSendType" BO_ 2561141322 0;
BA_ "GenMsgStartDelayTime" BO_ 2561141322 112;
BA_ "CI_MsgDefinition" BO_ 2561141578 "Iveco Bus Proprietary";
BA_ "CI_MsgId" BO_ 2561141578 14530;
BA_ "CI_MsgName" BO_ 2561141578 "DSE_OFFB_METRICS - DSE OFFB METRICS";
BA_ "GenMsgCycleTime" BO_ 2561141578 1000;
BA_ "GenMsgCycleTimeFast" BO_ 2561141578 1000;
BA_ "GenMsgDelayTime" BO_ 2561141578 500;
BA_ "GenMsgSendType" BO_ 2561141578 0;
BA_ "GenMsgStartDelayTime" BO_ 2561141578 114;
BA_ "CI_MsgDefinition" BO_ 2561135434 "Iveco Bus Proprietary";
BA_ "CI_MsgId" BO_ 2561135434 14538;
BA_ "CI_MsgName" BO_ 2561135434 "DSE_OLDDAS - DSE OldDas";
BA_ "GenMsgCycleTime" BO_ 2561135434 1000;
BA_ "GenMsgCycleTimeFast" BO_ 2561135434 1000;
BA_ "GenMsgDelayTime" BO_ 2561135434 500;
BA_ "GenMsgSendType" BO_ 2561135434 0;
BA_ "GenMsgStartDelayTime" BO_ 2561135434 68;
BA_ "CI_MsgDefinition" BO_ 2561142858 "Iveco Bus Proprietary";
BA_ "CI_MsgId" BO_ 2561142858 14544;
BA_ "CI_MsgName" BO_ 2561142858 "DSE_PCM_ACCEL - DSE PCM Accelerometer";
BA_ "GenMsgCycleTime" BO_ 2561142858 1000;
BA_ "GenMsgCycleTimeFast" BO_ 2561142858 1000;
BA_ "GenMsgDelayTime" BO_ 2561142858 500;
BA_ "GenMsgSendType" BO_ 2561142858 0;
BA_ "GenMsgStartDelayTime" BO_ 2561142858 124;
BA_ "CI_MsgDefinition" BO_ 2561135690 "Iveco Bus Proprietary";
BA_ "CI_MsgId" BO_ 2561135690 14548;
BA_ "CI_MsgName" BO_ 2561135690 "DSE_PECC - DSE Pecc";
BA_ "GenMsgCycleTime" BO_ 2561135690 1000;
BA_ "GenMsgCycleTimeFast" BO_ 2561135690 1000;
BA_ "GenMsgDelayTime" BO_ 2561135690 500;
BA_ "GenMsgSendType" BO_ 2561135690 0;
BA_ "GenMsgStartDelayTime" BO_ 2561135690 70;
BA_ "CI_MsgDefinition" BO_ 2561135946 "Iveco Bus Proprietary";
BA_ "CI_MsgId" BO_ 2561135946 14554;
BA_ "CI_MsgName" BO_ 2561135946 "DSE_PECC_DBG - DSE Pecc DBG";
BA_ "GenMsgCycleTime" BO_ 2561135946 1000;
BA_ "GenMsgCycleTimeFast" BO_ 2561135946 1000;
BA_ "GenMsgDelayTime" BO_ 2561135946 500;
BA_ "GenMsgSendType" BO_ 2561135946 0;
BA_ "GenMsgStartDelayTime" BO_ 2561135946 72;
BA_ "CI_MsgDefinition" BO_ 2561136202 "Iveco Bus Proprietary";
BA_ "CI_MsgId" BO_ 2561136202 14557;
BA_ "CI_MsgName" BO_ 2561136202 "DSE_RAD - DSE Radar";
BA_ "GenMsgCycleTime" BO_ 2561136202 1000;
BA_ "GenMsgCycleTimeFast" BO_ 2561136202 1000;
BA_ "GenMsgDelayTime" BO_ 2561136202 500;
BA_ "GenMsgSendType" BO_ 2561136202 0;
BA_ "GenMsgStartDelayTime" BO_ 2561136202 74;
BA_ "CI_MsgDefinition" BO_ 2561136458 "Iveco Bus Proprietary";
BA_ "CI_MsgId" BO_ 2561136458 14563;
BA_ "CI_MsgName" BO_ 2561136458 "DSE_RAD_DBG - DSE Radar DBG";
BA_ "GenMsgCycleTime" BO_ 2561136458 1000;
BA_ "GenMsgCycleTimeFast" BO_ 2561136458 1000;
BA_ "GenMsgDelayTime" BO_ 2561136458 500;
BA_ "GenMsgSendType" BO_ 2561136458 0;
BA_ "GenMsgStartDelayTime" BO_ 2561136458 76;
BA_ "CI_MsgDefinition" BO_ 2561136714 "Iveco Bus Proprietary";
BA_ "CI_MsgId" BO_ 2561136714 14566;
BA_ "CI_MsgName" BO_ 2561136714 "DSE_RPM - DSE Rpm";
BA_ "GenMsgCycleTime" BO_ 2561136714 1000;
BA_ "GenMsgCycleTimeFast" BO_ 2561136714 1000;
BA_ "GenMsgDelayTime" BO_ 2561136714 500;
BA_ "GenMsgSendType" BO_ 2561136714 0;
BA_ "GenMsgStartDelayTime" BO_ 2561136714 78;
BA_ "CI_MsgDefinition" BO_ 2561136970 "Iveco Bus Proprietary";
BA_ "CI_MsgId" BO_ 2561136970 14572;
BA_ "CI_MsgName" BO_ 2561136970 "DSE_RPM_DBG - DSE Rpm DBG";
BA_ "GenMsgCycleTime" BO_ 2561136970 1000;
BA_ "GenMsgCycleTimeFast" BO_ 2561136970 1000;
BA_ "GenMsgDelayTime" BO_ 2561136970 500;
BA_ "GenMsgSendType" BO_ 2561136970 0;
BA_ "GenMsgStartDelayTime" BO_ 2561136970 80;
BA_ "CI_MsgDefinition" BO_ 2561145162 "Iveco Bus Proprietary";
BA_ "CI_MsgId" BO_ 2561145162 14583;
BA_ "CI_MsgName" BO_ 2561145162 "DSE_SAFEDIST - DSE Safe Distance";
BA_ "GenMsgCycleTime" BO_ 2561145162 1000;
BA_ "GenMsgCycleTimeFast" BO_ 2561145162 1000;
BA_ "GenMsgDelayTime" BO_ 2561145162 500;
BA_ "GenMsgSendType" BO_ 2561145162 0;
BA_ "GenMsgStartDelayTime" BO_ 2561145162 142;
BA_ "CI_MsgDefinition" BO_ 2561145418 "Iveco Bus Proprietary";
BA_ "CI_MsgId" BO_ 2561145418 14589;
BA_ "CI_MsgName" BO_ 2561145418 "DSE_SAFEPOS - DSE Safe Position";
BA_ "GenMsgCycleTime" BO_ 2561145418 1000;
BA_ "GenMsgCycleTimeFast" BO_ 2561145418 1000;
BA_ "GenMsgDelayTime" BO_ 2561145418 500;
BA_ "GenMsgSendType" BO_ 2561145418 0;
BA_ "GenMsgStartDelayTime" BO_ 2561145418 144;
BA_ "CI_MsgDefinition" BO_ 2561137226 "Iveco Bus Proprietary";
BA_ "CI_MsgId" BO_ 2561137226 14595;
BA_ "CI_MsgName" BO_ 2561137226 "DSE_SAFETY - DSE Safety";
BA_ "GenMsgCycleTime" BO_ 2561137226 1000;
BA_ "GenMsgCycleTimeFast" BO_ 2561137226 1000;
BA_ "GenMsgDelayTime" BO_ 2561137226 500;
BA_ "GenMsgSendType" BO_ 2561137226 0;
BA_ "GenMsgStartDelayTime" BO_ 2561137226 82;
BA_ "CI_MsgDefinition" BO_ 2561137482 "Iveco Bus Proprietary";
BA_ "CI_MsgId" BO_ 2561137482 14601;
BA_ "CI_MsgName" BO_ 2561137482 "DSE_SF_TIRE - DSE Tire safety";
BA_ "GenMsgCycleTime" BO_ 2561137482 1000;
BA_ "GenMsgCycleTimeFast" BO_ 2561137482 1000;
BA_ "GenMsgDelayTime" BO_ 2561137482 500;
BA_ "GenMsgSendType" BO_ 2561137482 0;
BA_ "GenMsgStartDelayTime" BO_ 2561137482 84;
BA_ "CI_MsgDefinition" BO_ 2561137738 "Iveco Bus Proprietary";
BA_ "CI_MsgId" BO_ 2561137738 14607;
BA_ "CI_MsgName" BO_ 2561137738 "DSE_SF_TIRE_DBG - DSE Tire safety DBG";
BA_ "GenMsgCycleTime" BO_ 2561137738 1000;
BA_ "GenMsgCycleTimeFast" BO_ 2561137738 1000;
BA_ "GenMsgDelayTime" BO_ 2561137738 500;
BA_ "GenMsgSendType" BO_ 2561137738 0;
BA_ "GenMsgStartDelayTime" BO_ 2561137738 86;
BA_ "CI_MsgDefinition" BO_ 2561144650 "Iveco Bus Proprietary";
BA_ "CI_MsgId" BO_ 2561144650 14610;
BA_ "CI_MsgName" BO_ 2561144650 "DSE_SLOWMAN - DSE Slow Maneuver";
BA_ "GenMsgCycleTime" BO_ 2561144650 1000;
BA_ "GenMsgCycleTimeFast" BO_ 2561144650 1000;
BA_ "GenMsgDelayTime" BO_ 2561144650 500;
BA_ "GenMsgSendType" BO_ 2561144650 0;
BA_ "GenMsgStartDelayTime" BO_ 2561144650 138;
BA_ "CI_MsgDefinition" BO_ 2561144394 "Iveco Bus Proprietary";
BA_ "CI_MsgId" BO_ 2561144394 14616;
BA_ "CI_MsgName" BO_ 2561144394 "DSE_SPEED - DSE Speed";
BA_ "GenMsgCycleTime" BO_ 2561144394 1000;
BA_ "GenMsgCycleTimeFast" BO_ 2561144394 1000;
BA_ "GenMsgDelayTime" BO_ 2561144394 500;
BA_ "GenMsgSendType" BO_ 2561144394 0;
BA_ "GenMsgStartDelayTime" BO_ 2561144394 136;
BA_ "CI_MsgDefinition" BO_ 2561137994 "Iveco Bus Proprietary";
BA_ "CI_MsgId" BO_ 2561137994 14622;
BA_ "CI_MsgName" BO_ 2561137994 "DSE_START - DSE Start";
BA_ "GenMsgCycleTime" BO_ 2561137994 1000;
BA_ "GenMsgCycleTimeFast" BO_ 2561137994 1000;
BA_ "GenMsgDelayTime" BO_ 2561137994 500;
BA_ "GenMsgSendType" BO_ 2561137994 0;
BA_ "GenMsgStartDelayTime" BO_ 2561137994 88;
BA_ "CI_MsgDefinition" BO_ 2566875466 "Iveco Proprietary";
BA_ "CI_MsgId" BO_ 2566875466 1912;
BA_ "CI_MsgName" BO_ 2566875466 "DSE_STATUS - DSE Status Harsh";
BA_ "GenMsgCycleTime" BO_ 2566875466 500;
BA_ "GenMsgCycleTimeFast" BO_ 2566875466 500;
BA_ "GenMsgDelayTime" BO_ 2566875466 250;
BA_ "GenMsgSendType" BO_ 2566875466 0;
BA_ "GenMsgStartDelayTime" BO_ 2566875466 2;
BA_ "CI_MsgDefinition" BO_ 2561138250 "Iveco Bus Proprietary";
BA_ "CI_MsgId" BO_ 2561138250 14625;
BA_ "CI_MsgName" BO_ 2561138250 "DSE_STATUS_TRIP - DSE Status Trip";
BA_ "GenMsgCycleTime" BO_ 2561138250 1000;
BA_ "GenMsgCycleTimeFast" BO_ 2561138250 1000;
BA_ "GenMsgDelayTime" BO_ 2561138250 500;
BA_ "GenMsgSendType" BO_ 2561138250 0;
BA_ "GenMsgStartDelayTime" BO_ 2561138250 90;
BA_ "CI_MsgDefinition" BO_ 2561138506 "Iveco Bus Proprietary";
BA_ "CI_MsgId" BO_ 2561138506 14630;
BA_ "CI_MsgName" BO_ 2561138506 "DSE_STCNT - DSE Stability Control";
BA_ "GenMsgCycleTime" BO_ 2561138506 1000;
BA_ "GenMsgCycleTimeFast" BO_ 2561138506 1000;
BA_ "GenMsgDelayTime" BO_ 2561138506 500;
BA_ "GenMsgSendType" BO_ 2561138506 0;
BA_ "GenMsgStartDelayTime" BO_ 2561138506 92;
BA_ "CI_MsgDefinition" BO_ 2561138762 "Iveco Bus Proprietary";
BA_ "CI_MsgId" BO_ 2561138762 14636;
BA_ "CI_MsgName" BO_ 2561138762 "DSE_STCNT_DBG - DSE Stability Control DBG";
BA_ "GenMsgCycleTime" BO_ 2561138762 1000;
BA_ "GenMsgCycleTimeFast" BO_ 2561138762 1000;
BA_ "GenMsgDelayTime" BO_ 2561138762 500;
BA_ "GenMsgSendType" BO_ 2561138762 0;
BA_ "GenMsgStartDelayTime" BO_ 2561138762 94;
BA_ "CI_MsgDefinition" BO_ 2561139018 "Iveco Bus Proprietary";
BA_ "CI_MsgId" BO_ 2561139018 14639;
BA_ "CI_MsgName" BO_ 2561139018 "DSE_STOP - DSE Stop";
BA_ "GenMsgCycleTime" BO_ 2561139018 1000;
BA_ "GenMsgCycleTimeFast" BO_ 2561139018 1000;
BA_ "GenMsgDelayTime" BO_ 2561139018 500;
BA_ "GenMsgSendType" BO_ 2561139018 0;
BA_ "GenMsgStartDelayTime" BO_ 2561139018 96;
BA_ "CI_MsgDefinition" BO_ 2561139274 "Iveco Bus Proprietary";
BA_ "CI_MsgId" BO_ 2561139274 14645;
BA_ "CI_MsgName" BO_ 2561139274 "DSE_STOP_DBG - DSE Stop DBG";
BA_ "GenMsgCycleTime" BO_ 2561139274 1000;
BA_ "GenMsgCycleTimeFast" BO_ 2561139274 1000;
BA_ "GenMsgDelayTime" BO_ 2561139274 500;
BA_ "GenMsgSendType" BO_ 2561139274 0;
BA_ "GenMsgStartDelayTime" BO_ 2561139274 98;
BA_ "CI_MsgDefinition" BO_ 2561141066 "Iveco Bus Proprietary";
BA_ "CI_MsgId" BO_ 2561141066 14653;
BA_ "CI_MsgName" BO_ 2561141066 "DSE_TEVENT - DSE TEvent";
BA_ "GenMsgCycleTime" BO_ 2561141066 1000;
BA_ "GenMsgCycleTimeFast" BO_ 2561141066 1000;
BA_ "GenMsgDelayTime" BO_ 2561141066 500;
BA_ "GenMsgSendType" BO_ 2561141066 0;
BA_ "GenMsgStartDelayTime" BO_ 2561141066 110;
BA_ "CI_MsgDefinition" BO_ 2561139530 "Iveco Bus Proprietary";
BA_ "CI_MsgId" BO_ 2561139530 14660;
BA_ "CI_MsgName" BO_ 2561139530 "DSE_TIRE - DSE Tire";
BA_ "GenMsgCycleTime" BO_ 2561139530 1000;
BA_ "GenMsgCycleTimeFast" BO_ 2561139530 1000;
BA_ "GenMsgDelayTime" BO_ 2561139530 500;
BA_ "GenMsgSendType" BO_ 2561139530 0;
BA_ "GenMsgStartDelayTime" BO_ 2561139530 100;
BA_ "CI_MsgDefinition" BO_ 2561139786 "Iveco Bus Proprietary";
BA_ "CI_MsgId" BO_ 2561139786 14666;
BA_ "CI_MsgName" BO_ 2561139786 "DSE_TIRE_DBG - DSE Tire DBG";
BA_ "GenMsgCycleTime" BO_ 2561139786 1000;
BA_ "GenMsgCycleTimeFast" BO_ 2561139786 1000;
BA_ "GenMsgDelayTime" BO_ 2561139786 500;
BA_ "GenMsgSendType" BO_ 2561139786 0;
BA_ "GenMsgStartDelayTime" BO_ 2561139786 102;
BA_ "CI_MsgDefinition" BO_ 2561145674 "Iveco Bus Proprietary";
BA_ "CI_MsgId" BO_ 2561145674 14669;
BA_ "CI_MsgName" BO_ 2561145674 "DSE_TRIP_B - DSE TripB";
BA_ "GenMsgCycleTime" BO_ 2561145674 1000;
BA_ "GenMsgCycleTimeFast" BO_ 2561145674 1000;
BA_ "GenMsgDelayTime" BO_ 2561145674 500;
BA_ "GenMsgSendType" BO_ 2561145674 0;
BA_ "GenMsgStartDelayTime" BO_ 2561145674 146;
BA_ "CI_MsgDefinition" BO_ 2561144906 "Iveco Bus Proprietary";
BA_ "CI_MsgId" BO_ 2561144906 14675;
BA_ "CI_MsgName" BO_ 2561144906 "DSE_VEHCONT - DSE Vehicle Control";
BA_ "GenMsgCycleTime" BO_ 2561144906 1000;
BA_ "GenMsgCycleTimeFast" BO_ 2561144906 1000;
BA_ "GenMsgDelayTime" BO_ 2561144906 500;
BA_ "GenMsgSendType" BO_ 2561144906 0;
BA_ "GenMsgStartDelayTime" BO_ 2561144906 140;
BA_ "CI_MsgDefinition" BO_ 2561140298 "Iveco Bus Proprietary";
BA_ "CI_MsgId" BO_ 2561140298 14681;
BA_ "CI_MsgName" BO_ 2561140298 "DSE_VER - DSE Version";
BA_ "GenMsgCycleTime" BO_ 2561140298 1000;
BA_ "GenMsgCycleTimeFast" BO_ 2561140298 1000;
BA_ "GenMsgDelayTime" BO_ 2561140298 500;
BA_ "GenMsgSendType" BO_ 2561140298 0;
BA_ "GenMsgStartDelayTime" BO_ 2561140298 104;
BA_ "CI_MsgDefinition" BO_ 2561142602 "Iveco Bus Proprietary";
BA_ "CI_MsgId" BO_ 2561142602 14686;
BA_ "CI_MsgName" BO_ 2561142602 "DSE_VERTICAL - DSE Vertical";
BA_ "GenMsgCycleTime" BO_ 2561142602 1000;
BA_ "GenMsgCycleTimeFast" BO_ 2561142602 1000;
BA_ "GenMsgDelayTime" BO_ 2561142602 500;
BA_ "GenMsgSendType" BO_ 2561142602 0;
BA_ "GenMsgStartDelayTime" BO_ 2561142602 122;
BA_ "CI_MsgDefinition" BO_ 2561143626 "Iveco Bus Proprietary";
BA_ "CI_MsgId" BO_ 2561143626 14692;
BA_ "CI_MsgName" BO_ 2561143626 "DSE_VERTICAL_DBG - DSE Vertical DBG";
BA_ "GenMsgCycleTime" BO_ 2561143626 1000;
BA_ "GenMsgCycleTimeFast" BO_ 2561143626 1000;
BA_ "GenMsgDelayTime" BO_ 2561143626 500;
BA_ "GenMsgSendType" BO_ 2561143626 0;
BA_ "GenMsgStartDelayTime" BO_ 2561143626 130;
BA_ "CI_MsgDefinition" BO_ 2565865739 "J1939DA";
BA_ "CI_MsgId" BO_ 2565865739 229;
BA_ "CI_MsgName" BO_ 2565865739 "EBC1 - Electronic Brake Controller 1";
BA_ "GenMsgCycleTime" BO_ 2565865739 100;
BA_ "GenMsgCycleTimeFast" BO_ 2565865739 100;
BA_ "GenMsgDelayTime" BO_ 2565865739 50;
BA_ "GenMsgSendType" BO_ 2565865739 0;
BA_ "GenMsgStartDelayTime" BO_ 2565865739 11;
BA_ "CI_MsgDefinition" BO_ 2566831883 "J1939DA";
BA_ "CI_MsgId" BO_ 2566831883 266;
BA_ "CI_MsgName" BO_ 2566831883 "EBC2 - Wheel Speed Information";
BA_ "GenMsgCycleTime" BO_ 2566831883 50;
BA_ "GenMsgCycleTimeFast" BO_ 2566831883 50;
BA_ "GenMsgDelayTime" BO_ 2566831883 25;
BA_ "GenMsgSendType" BO_ 2566831883 0;
BA_ "GenMsgStartDelayTime" BO_ 2566831883 14;
BA_ "CI_MsgDefinition" BO_ 2633935883 "J1939DA";
BA_ "CI_MsgId" BO_ 2633935883 292;
BA_ "CI_MsgName" BO_ 2633935883 "EBC4_A - Wheel Brake Lining Remaining Information";
BA_ "GenMsgCycleTime" BO_ 2633935883 5000;
BA_ "GenMsgCycleTimeFast" BO_ 2633935883 5000;
BA_ "GenMsgDelayTime" BO_ 2633935883 2500;
BA_ "GenMsgSendType" BO_ 2633935883 0;
BA_ "GenMsgStartDelayTime" BO_ 2633935883 44;
BA_ "CI_MsgDefinition" BO_ 2566767627 "J1939DA";
BA_ "CI_MsgId" BO_ 2566767627 301;
BA_ "CI_MsgName" BO_ 2566767627 "EBC5 - Electronic Brake Controller 5";
BA_ "GenMsgCycleTime" BO_ 2566767627 100;
BA_ "GenMsgCycleTimeFast" BO_ 2566767627 100;
BA_ "GenMsgDelayTime" BO_ 2566767627 50;
BA_ "GenMsgSendType" BO_ 2566767627 0;
BA_ "GenMsgStartDelayTime" BO_ 2566767627 18;
BA_ "CI_MsgDefinition" BO_ 2566841088 "J1939DA";
BA_ "CI_MsgId" BO_ 2566841088 965;
BA_ "CI_MsgName" BO_ 2566841088 "EC1_00_E3 - Engine Configuration 1";
BA_ "GenMsgCycleTime" BO_ 2566841088 5000;
BA_ "GenMsgCycleTimeFast" BO_ 2566841088 5000;
BA_ "GenMsgDelayTime" BO_ 2566841088 500;
BA_ "GenMsgSendType" BO_ 2566841088 0;
BA_ "GenMsgStartDelayTime" BO_ 2566841088 31;
BA_ "CI_MsgDefinition" BO_ 2566841216 "J1939DA";
BA_ "CI_MsgId" BO_ 2566841216 994;
BA_ "CI_MsgName" BO_ 2566841216 "EC1_80 - Engine Configuration 1";
BA_ "GenMsgCycleTime" BO_ 2566841216 2000;
BA_ "GenMsgCycleTimeFast" BO_ 2566841216 2000;
BA_ "GenMsgDelayTime" BO_ 2566841216 500;
BA_ "GenMsgSendType" BO_ 2566841216 0;
BA_ "GenMsgStartDelayTime" BO_ 2566841216 14;
BA_ "CI_MsgDefinition" BO_ 2566891081 "Iveco Proprietary";
BA_ "CI_MsgId" BO_ 2566891081 2904;
BA_ "CI_MsgName" BO_ 2566891081 "ECCU_Inf1 - ECCU_Information_1 - Embedded Charging Control Unit ";
BA_ "GenMsgCycleTime" BO_ 2566891081 1000;
BA_ "GenMsgCycleTimeFast" BO_ 2566891081 1000;
BA_ "GenMsgDelayTime" BO_ 2566891081 500;
BA_ "GenMsgSendType" BO_ 2566891081 0;
BA_ "GenMsgStartDelayTime" BO_ 2566891081 2;
BA_ "CI_MsgDefinition" BO_ 2566889801 "Iveco Proprietary";
BA_ "CI_MsgId" BO_ 2566889801 4033;
BA_ "CI_MsgName" BO_ 2566889801 "ECCU2SCU_49 - Embedded Charging Control Unit to Supervisor";
BA_ "GenMsgCycleTime" BO_ 2566889801 5000;
BA_ "GenMsgCycleTimeFast" BO_ 2566889801 5000;
BA_ "GenMsgDelayTime" BO_ 2566889801 2500;
BA_ "GenMsgSendType" BO_ 2566889801 0;
BA_ "GenMsgStartDelayTime" BO_ 2566889801 61;
BA_ "CI_MsgDefinition" BO_ 2566767966 "J1939DA";
BA_ "CI_MsgId" BO_ 2566767966 10343;
BA_ "CI_MsgName" BO_ 2566767966 "ECU_CAID2 - ECU Identification CAID2";
BA_ "GenMsgCycleTime" BO_ 2566767966 1000;
BA_ "GenMsgCycleTimeFast" BO_ 2566767966 1000;
BA_ "GenMsgDelayTime" BO_ 2566767966 500;
BA_ "GenMsgSendType" BO_ 2566767966 0;
BA_ "GenMsgStartDelayTime" BO_ 2566767966 4;
BA_ "CI_MsgDefinition" BO_ 2566767900 "J1939DA";
BA_ "CI_MsgId" BO_ 2566767900 10315;
BA_ "CI_MsgName" BO_ 2566767900 "ECUID_1C - ECU Identification Information";
BA_ "TpJ1939VarDlc" BO_ 2566767900 1;
BA_ "CI_MsgDefinition" BO_ 2566767901 "J1939DA";
BA_ "CI_MsgId" BO_ 2566767901 10322;
BA_ "CI_MsgName" BO_ 2566767901 "ECUID_1D - ECU Identification Information";
BA_ "TpJ1939VarDlc" BO_ 2566767901 1;
BA_ "CI_MsgDefinition" BO_ 2566849280 "Iveco SPR1 Proprietary";
BA_ "CI_MsgId" BO_ 2566849280 4048;
BA_ "CI_MsgName" BO_ 2566849280 "Edc2BcIC - EDC to Body Computer - IC";
BA_ "GenMsgCycleTime" BO_ 2566849280 50;
BA_ "GenMsgCycleTimeFast" BO_ 2566849280 50;
BA_ "GenMsgDelayTime" BO_ 2566849280 25;
BA_ "GenMsgSendType" BO_ 2566849280 0;
BA_ "GenMsgStartDelayTime" BO_ 2566849280 11;
BA_ "CI_MsgDefinition" BO_ 2364539904 "J1939DA";
BA_ "CI_MsgId" BO_ 2364539904 836;
BA_ "CI_MsgName" BO_ 2364539904 "EEC1 - Electronic Engine Controller 1";
BA_ "GenMsgCycleTime" BO_ 2364539904 10;
BA_ "GenMsgCycleTimeFast" BO_ 2364539904 10;
BA_ "GenMsgDelayTime" BO_ 2364539904 5;
BA_ "GenMsgSendType" BO_ 2364539904 0;
BA_ "GenMsgStartDelayTime" BO_ 2364539904 4;
BA_ "CI_ParId" SG_ 2561141834 FuelConsumptionDiesel "IB1709";
BA_ "CI_SigId" SG_ 2561141834 FuelConsumptionDiesel 14345;
BA_ "CI_SigName" SG_ 2561141834 FuelConsumptionDiesel "FuelConsumptionDiesel";
BA_ "GenSigTimeoutTime_SGW_" SG_ 2561141834 FuelConsumptionDiesel 5000;
BA_ "CI_ParId" SG_ 2561141834 FuelConsumptionGas "IB1710";
BA_ "CI_SigId" SG_ 2561141834 FuelConsumptionGas 14346;
BA_ "CI_SigName" SG_ 2561141834 FuelConsumptionGas "FuelConsumptionGas";
BA_ "GenSigTimeoutTime_SGW_" SG_ 2561141834 FuelConsumptionGas 5000;
BA_ "CI_ParId" SG_ 2561141834 FuelConsEstimatDiesel "IB1711";
BA_ "CI_SigId" SG_ 2561141834 FuelConsEstimatDiesel 14347;
BA_ "CI_SigName" SG_ 2561141834 FuelConsEstimatDiesel "FuelConsumptionEstimatedDiesel";
BA_ "GenSigTimeoutTime_SGW_" SG_ 2561141834 FuelConsEstimatDiesel 5000;
BA_ "CI_ParId" SG_ 2561141834 FuelConsumptionElec "IB1712";
BA_ "CI_SigId" SG_ 2561141834 FuelConsumptionElec 14348;
BA_ "CI_SigName" SG_ 2561141834 FuelConsumptionElec "FuelConsumptionElec";
BA_ "GenSigTimeoutTime_SGW_" SG_ 2561141834 FuelConsumptionElec 5000;
BA_ "CI_ParId" SG_ 2561131850 GPSLatitude "IB1713";
BA_ "CI_SigId" SG_ 2561131850 GPSLatitude 14350;
BA_ "CI_SigName" SG_ 2561131850 GPSLatitude "GPSLatitude";
BA_ "GenSigTimeoutTime_SGW_" SG_ 2561131850 GPSLatitude 5000;
BA_ "CI_ParId" SG_ 2561131850 GPSLongitude "IB1714";
BA_ "CI_SigId" SG_ 2561131850 GPSLongitude 14351;
BA_ "CI_SigName" SG_ 2561131850 GPSLongitude "GPSLongitude";
BA_ "GenSigTimeoutTime_SGW_" SG_ 2561131850 GPSLongitude 5000;
BA_ "CI_ParId" SG_ 2561131850 GPSAltitude "IB1715";
BA_ "CI_SigId" SG_ 2561131850 GPSAltitude 14352;
BA_ "CI_SigName" SG_ 2561131850 GPSAltitude "GPSAltitude";
BA_ "GenSigTimeoutTime_SGW_" SG_ 2561131850 GPSAltitude 5000;
BA_ "CI_ParId" SG_ 2561131850 Vdop "IB1716";
BA_ "CI_SigId" SG_ 2561131850 Vdop 14353;
BA_ "CI_SigName" SG_ 2561131850 Vdop "Vdop";
BA_ "GenSigTimeoutTime_SGW_" SG_ 2561131850 Vdop 5000;
BA_ "CI_ParId" SG_ 2561131850 Hdop "IB1717";
BA_ "CI_SigId" SG_ 2561131850 Hdop 14354;
BA_ "CI_SigName" SG_ 2561131850 Hdop "Hdop";
BA_ "GenSigTimeoutTime_SGW_" SG_ 2561131850 Hdop 5000;
BA_ "CI_ParId" SG_ 2561131850 NrSatellites "IB1718";
BA_ "CI_SigId" SG_ 2561131850 NrSatellites 14355;
BA_ "CI_SigName" SG_ 2561131850 NrSatellites "NrSatellites";
BA_ "GenSigTimeoutTime_SGW_" SG_ 2561131850 NrSatellites 5000;
BA_ "CI_ParId" SG_ 2561132106 ScoreHandBrake "IB1719";
BA_ "CI_SigId" SG_ 2561132106 ScoreHandBrake 14357;
BA_ "CI_SigName" SG_ 2561132106 ScoreHandBrake "ScoreHandBrake";
BA_ "GenSigTimeoutTime_SGW_" SG_ 2561132106 ScoreHandBrake 5000;
BA_ "CI_ParId" SG_ 2561132106 ValidHandBrake "IB1720";
BA_ "CI_SigId" SG_ 2561132106 ValidHandBrake 14358;
BA_ "CI_SigName" SG_ 2561132106 ValidHandBrake "ValidHandBrake";
BA_ "GenSigTimeoutTime_SGW_" SG_ 2561132106 ValidHandBrake 5000;
BA_ "SigType" SG_ 2561132106 ValidHandBrake 4;
BA_ "CI_ParId" SG_ 2561132106 TrendHandBrake "IB1721";
BA_ "CI_SigId" SG_ 2561132106 TrendHandBrake 14359;
BA_ "CI_SigName" SG_ 2561132106 TrendHandBrake "TrendHandBrake";
BA_ "GenSigTimeoutTime_SGW_" SG_ 2561132106 TrendHandBrake 5000;
BA_ "CI_ParId" SG_ 2561132106 BenefitHandBrake "IB1722";
BA_ "CI_SigId" SG_ 2561132106 BenefitHandBrake 14360;
BA_ "CI_SigName" SG_ 2561132106 BenefitHandBrake "BenefitHandBrake";
BA_ "GenSigTimeoutTime_SGW_" SG_ 2561132106 BenefitHandBrake 5000;
BA_ "SigType" SG_ 2561132106 BenefitHandBrake 4;
BA_ "CI_ParId" SG_ 2561132106 WeightHandBrake "IB1723";
BA_ "CI_SigId" SG_ 2561132106 WeightHandBrake 14361;
BA_ "CI_SigName" SG_ 2561132106 WeightHandBrake "WeightHandBrake";
BA_ "GenSigTimeoutTime_SGW_" SG_ 2561132106 WeightHandBrake 5000;
BA_ "CI_ParId" SG_ 2561132362 NumEventsHandBrake "IB1724";
BA_ "CI_SigId" SG_ 2561132362 NumEventsHandBrake 14363;
BA_ "CI_SigName" SG_ 2561132362 NumEventsHandBrake "NumEventsHandBrake";
BA_ "GenSigTimeoutTime_SGW_" SG_ 2561132362 NumEventsHandBrake 5000;
BA_ "CI_ParId" SG_ 2561132362 EventHandBrake "IB1725";
BA_ "CI_SigId" SG_ 2561132362 EventHandBrake 14364;
BA_ "CI_SigName" SG_ 2561132362 EventHandBrake "EventHandBrake";
BA_ "GenSigTimeoutTime_SGW_" SG_ 2561132362 EventHandBrake 5000;
BA_ "SigType" SG_ 2561132362 EventHandBrake 4;
BA_ "CI_ParId" SG_ 2561132618 ScoreHarshBraking "IB1726";
BA_ "CI_SigId" SG_ 2561132618 ScoreHarshBraking 14366;
BA_ "CI_SigName" SG_ 2561132618 ScoreHarshBraking "ScoreHarshBraking";
BA_ "GenSigTimeoutTime_SGW_" SG_ 2561132618 ScoreHarshBraking 5000;
BA_ "CI_ParId" SG_ 2561132618 ValidHarshBraking "IB1727";
BA_ "CI_SigId" SG_ 2561132618 ValidHarshBraking 14367;
BA_ "CI_SigName" SG_ 2561132618 ValidHarshBraking "ValidHarshBraking";
BA_ "GenSigTimeoutTime_SGW_" SG_ 2561132618 ValidHarshBraking 5000;
BA_ "SigType" SG_ 2561132618 ValidHarshBraking 4;
BA_ "CI_ParId" SG_ 2561132618 TrendHarshBraking "IB1728";
BA_ "CI_SigId" SG_ 2561132618 TrendHarshBraking 14368;
BA_ "CI_SigName" SG_ 2561132618 TrendHarshBraking "TrendHarshBraking";
BA_ "GenSigTimeoutTime_SGW_" SG_ 2561132618 TrendHarshBraking 5000;
BA_ "CI_ParId" SG_ 2561132618 BenefitHarshBraking "IB1729";
BA_ "CI_SigId" SG_ 2561132618 BenefitHarshBraking 14369;
BA_ "CI_SigName" SG_ 2561132618 BenefitHarshBraking "BenefitHarshBraking";
BA_ "GenSigTimeoutTime_SGW_" SG_ 2561132618 BenefitHarshBraking 5000;
BA_ "SigType" SG_ 2561132618 BenefitHarshBraking 4;
BA_ "CI_ParId" SG_ 2561132618 WeightHarshBraking "IB1730";
BA_ "CI_SigId" SG_ 2561132618 WeightHarshBraking 14370;
BA_ "CI_SigName" SG_ 2561132618 WeightHarshBraking "WeightHarshBraking";
BA_ "GenSigTimeoutTime_SGW_" SG_ 2561132618 WeightHarshBraking 5000;
BA_ "CI_ParId" SG_ 2561132874 EvalMetersHarshBraking "IB1731";
BA_ "CI_SigId" SG_ 2561132874 EvalMetersHarshBraking 14372;
BA_ "CI_SigName" SG_ 2561132874 EvalMetersHarshBraking "EvaluatedMetersHarshBraking";
BA_ "GenSigTimeoutTime_SGW_" SG_ 2561132874 EvalMetersHarshBraking 5000;
BA_ "SigType" SG_ 2561132874 EvalMetersHarshBraking 1;
BA_ "CI_ParId" SG_ 2561132874 EventHarshBraking "IB1732";
BA_ "CI_SigId" SG_ 2561132874 EventHarshBraking 14373;
BA_ "CI_SigName" SG_ 2561132874 EventHarshBraking "EventHarshBraking";
BA_ "GenSigTimeoutTime_SGW_" SG_ 2561132874 EventHarshBraking 5000;
BA_ "SigType" SG_ 2561132874 EventHarshBraking 4;
BA_ "CI_ParId" SG_ 2561132874 MaxDecelHarshBraking "IB1733";
BA_ "CI_SigId" SG_ 2561132874 MaxDecelHarshBraking 14374;
BA_ "CI_SigName" SG_ 2561132874 MaxDecelHarshBraking "MaxDecelerationHarshBraking";
BA_ "GenSigTimeoutTime_SGW_" SG_ 2561132874 MaxDecelHarshBraking 5000;
BA_ "CI_ParId" SG_ 2561133130 ScoreHarshSteering "IB1734";
BA_ "CI_SigId" SG_ 2561133130 ScoreHarshSteering 14376;
BA_ "CI_SigName" SG_ 2561133130 ScoreHarshSteering "ScoreHarshSteering";
BA_ "GenSigTimeoutTime_SGW_" SG_ 2561133130 ScoreHarshSteering 5000;
BA_ "CI_ParId" SG_ 2561133130 ValidHarshSteering "IB1735";
BA_ "CI_SigId" SG_ 2561133130 ValidHarshSteering 14377;
BA_ "CI_SigName" SG_ 2561133130 ValidHarshSteering "ValidHarshSteering";
BA_ "GenSigTimeoutTime_SGW_" SG_ 2561133130 ValidHarshSteering 5000;
BA_ "SigType" SG_ 2561133130 ValidHarshSteering 4;
BA_ "CI_ParId" SG_ 2561133130 TrendHarshSteering "IB1736";
BA_ "CI_SigId" SG_ 2561133130 TrendHarshSteering 14378;
BA_ "CI_SigName" SG_ 2561133130 TrendHarshSteering "TrendHarshSteering";
BA_ "GenSigTimeoutTime_SGW_" SG_ 2561133130 TrendHarshSteering 5000;
BA_ "CI_ParId" SG_ 2561133130 BenefitHarshSteering "IB1737";
BA_ "CI_SigId" SG_ 2561133130 BenefitHarshSteering 14379;
BA_ "CI_SigName" SG_ 2561133130 BenefitHarshSteering "BenefitHarshSteering";
BA_ "GenSigTimeoutTime_SGW_" SG_ 2561133130 BenefitHarshSteering 5000;
BA_ "SigType" SG_ 2561133130 BenefitHarshSteering 4;
BA_ "CI_ParId" SG_ 2561133130 WeightHarshSteering "IB1738";
BA_ "CI_SigId" SG_ 2561133130 WeightHarshSteering 14380;
BA_ "CI_SigName" SG_ 2561133130 WeightHarshSteering "WeightHarshSteering";
BA_ "GenSigTimeoutTime_SGW_" SG_ 2561133130 WeightHarshSteering 5000;
BA_ "CI_ParId" SG_ 2561133386 EvalMetersHarshSteering "IB1739";
BA_ "CI_SigId" SG_ 2561133386 EvalMetersHarshSteering 14382;
BA_ "CI_SigName" SG_ 2561133386 EvalMetersHarshSteering "EvaluatedMetersHarshSteering";
BA_ "GenSigTimeoutTime_SGW_" SG_ 2561133386 EvalMetersHarshSteering 5000;
BA_ "SigType" SG_ 2561133386 EvalMetersHarshSteering 1;
BA_ "CI_ParId" SG_ 2561133386 EventHarshSteering "IB1740";
BA_ "CI_SigId" SG_ 2561133386 EventHarshSteering 14383;
BA_ "CI_SigName" SG_ 2561133386 EventHarshSteering "EventHarshSteering";
BA_ "GenSigTimeoutTime_SGW_" SG_ 2561133386 EventHarshSteering 5000;
BA_ "SigType" SG_ 2561133386 EventHarshSteering 4;
BA_ "CI_ParId" SG_ 2561133898 ScoreInertia "IB1741";
BA_ "CI_SigId" SG_ 2561133898 ScoreInertia 14385;
BA_ "CI_SigName" SG_ 2561133898 ScoreInertia "ScoreInertia";
BA_ "GenSigTimeoutTime_SGW_" SG_ 2561133898 ScoreInertia 5000;
BA_ "CI_ParId" SG_ 2561133898 ValidInertia "IB1742";
BA_ "CI_SigId" SG_ 2561133898 ValidInertia 14386;
BA_ "CI_SigName" SG_ 2561133898 ValidInertia "ValidInertia";
BA_ "GenSigTimeoutTime_SGW_" SG_ 2561133898 ValidInertia 5000;
BA_ "SigType" SG_ 2561133898 ValidInertia 4;
BA_ "CI_ParId" SG_ 2561133898 TrendInertia "IB1743";
BA_ "CI_SigId" SG_ 2561133898 TrendInertia 14387;
BA_ "CI_SigName" SG_ 2561133898 TrendInertia "TrendInertia";
BA_ "GenSigTimeoutTime_SGW_" SG_ 2561133898 TrendInertia 5000;
BA_ "CI_ParId" SG_ 2561133898 BenefitInertia "IB1744";
BA_ "CI_SigId" SG_ 2561133898 BenefitInertia 14388;
BA_ "CI_SigName" SG_ 2561133898 BenefitInertia "BenefitInertia";
BA_ "GenSigTimeoutTime_SGW_" SG_ 2561133898 BenefitInertia 5000;
BA_ "SigType" SG_ 2561133898 BenefitInertia 4;
BA_ "CI_ParId" SG_ 2561133898 WeightInertia "IB1745";
BA_ "CI_SigId" SG_ 2561133898 WeightInertia 14389;
BA_ "CI_SigName" SG_ 2561133898 WeightInertia "WeightInertia";
BA_ "GenSigTimeoutTime_SGW_" SG_ 2561133898 WeightInertia 5000;
BA_ "CI_ParId" SG_ 2561134154 LastManeuverScoreInertia "IB1746";
BA_ "CI_SigId" SG_ 2561134154 LastManeuverScoreInertia 14391;
BA_ "CI_SigName" SG_ 2561134154 LastManeuverScoreInertia "LastManeuverScoreInertia";
BA_ "GenSigTimeoutTime_SGW_" SG_ 2561134154 LastManeuverScoreInertia 5000;
BA_ "CI_ParId" SG_ 2561134154 EventInertia "IB1747";
BA_ "CI_SigId" SG_ 2561134154 EventInertia 14392;
BA_ "CI_SigName" SG_ 2561134154 EventInertia "EventInertia";
BA_ "GenSigTimeoutTime_SGW_" SG_ 2561134154 EventInertia 5000;
BA_ "CI_ParId" SG_ 2561134154 StartReasonInertia "IB1748";
BA_ "CI_SigId" SG_ 2561134154 StartReasonInertia 14393;
BA_ "CI_SigName" SG_ 2561134154 StartReasonInertia "StartReasonInertia";
BA_ "GenSigTimeoutTime_SGW_" SG_ 2561134154 StartReasonInertia 5000;
BA_ "SigType" SG_ 2561134154 StartReasonInertia 4;
BA_ "CI_ParId" SG_ 2561134154 EndReasonInertia "IB1749";
BA_ "CI_SigId" SG_ 2561134154 EndReasonInertia 14394;
BA_ "CI_SigName" SG_ 2561134154 EndReasonInertia "EndReasonInertia";
BA_ "GenSigTimeoutTime_SGW_" SG_ 2561134154 EndReasonInertia 5000;
BA_ "SigType" SG_ 2561134154 EndReasonInertia 4;
BA_ "CI_ParId" SG_ 2561134154 ManeuverCountInertia "IB1750";
BA_ "CI_SigId" SG_ 2561134154 ManeuverCountInertia 14395;
BA_ "CI_SigName" SG_ 2561134154 ManeuverCountInertia "ManeuverCountInertia";
BA_ "GenSigTimeoutTime_SGW_" SG_ 2561134154 ManeuverCountInertia 5000;
BA_ "CI_ParId" SG_ 2561134154 DurationInertia "IB1751";
BA_ "CI_SigId" SG_ 2561134154 DurationInertia 14396;
BA_ "CI_SigName" SG_ 2561134154 DurationInertia "DurationInertia";
BA_ "GenSigTimeoutTime_SGW_" SG_ 2561134154 DurationInertia 5000;
BA_ "CI_ParId" SG_ 2561134154 StartingSpeedInertia "IB1752";
BA_ "CI_SigId" SG_ 2561134154 StartingSpeedInertia 14397;
BA_ "CI_SigName" SG_ 2561134154 StartingSpeedInertia "StartingSpeedInertia";
BA_ "GenSigTimeoutTime_SGW_" SG_ 2561134154 StartingSpeedInertia 5000;
BA_ "SigType" SG_ 2561134154 StartingSpeedInertia 1;
BA_ "CI_ParId" SG_ 2561134154 DangerOfCollisInertia "IB1753";
BA_ "CI_SigId" SG_ 2561134154 DangerOfCollisInertia 14398;
BA_ "CI_SigName" SG_ 2561134154 DangerOfCollisInertia "DangerOfCollisionInertia";
BA_ "GenSigTimeoutTime_SGW_" SG_ 2561134154 DangerOfCollisInertia 5000;
BA_ "SigType" SG_ 2561134154 DangerOfCollisInertia 4;
BA_ "CI_ParId" SG_ 2561134154 PunishingManeuvInertia "IB1754";
BA_ "CI_SigId" SG_ 2561134154 PunishingManeuvInertia 14399;
BA_ "CI_SigName" SG_ 2561134154 PunishingManeuvInertia "PunishingManeuverInertia";
BA_ "GenSigTimeoutTime_SGW_" SG_ 2561134154 PunishingManeuvInertia 5000;
BA_ "SigType" SG_ 2561134154 PunishingManeuvInertia 4;
BA_ "CI_ParId" SG_ 2561134410 ScoreInertiaPecc "IB1755";
BA_ "CI_SigId" SG_ 2561134410 ScoreInertiaPecc 14401;
BA_ "CI_SigName" SG_ 2561134410 ScoreInertiaPecc "ScoreInertiaPecc";
BA_ "GenSigTimeoutTime_SGW_" SG_ 2561134410 ScoreInertiaPecc 5000;
BA_ "CI_ParId" SG_ 2561134410 ValidInertiaPecc "IB1756";
BA_ "CI_SigId" SG_ 2561134410 ValidInertiaPecc 14402;
BA_ "CI_SigName" SG_ 2561134410 ValidInertiaPecc "ValidInertiaPecc";
BA_ "GenSigTimeoutTime_SGW_" SG_ 2561134410 ValidInertiaPecc 5000;
BA_ "SigType" SG_ 2561134410 ValidInertiaPecc 4;
BA_ "CI_ParId" SG_ 2561134410 TrendInertiaPecc "IB1757";
BA_ "CI_SigId" SG_ 2561134410 TrendInertiaPecc 14403;
BA_ "CI_SigName" SG_ 2561134410 TrendInertiaPecc "TrendInertiaPecc";
BA_ "GenSigTimeoutTime_SGW_" SG_ 2561134410 TrendInertiaPecc 5000;
BA_ "CI_ParId" SG_ 2561134410 BenefitInertiaPecc "IB1758";
BA_ "CI_SigId" SG_ 2561134410 BenefitInertiaPecc 14404;
BA_ "CI_SigName" SG_ 2561134410 BenefitInertiaPecc "BenefitInertiaPecc";
BA_ "GenSigTimeoutTime_SGW_" SG_ 2561134410 BenefitInertiaPecc 5000;
BA_ "SigType" SG_ 2561134410 BenefitInertiaPecc 4;
BA_ "CI_ParId" SG_ 2561134410 WeightInertiaPecc "IB1759";
BA_ "CI_SigId" SG_ 2561134410 WeightInertiaPecc 14405;
BA_ "CI_SigName" SG_ 2561134410 WeightInertiaPecc "WeightInertiaPecc";
BA_ "GenSigTimeoutTime_SGW_" SG_ 2561134410 WeightInertiaPecc 5000;
BA_ "CI_ParId" SG_ 2561142090 ScoreLateral "IB1760";
BA_ "CI_SigId" SG_ 2561142090 ScoreLateral 14407;
BA_ "CI_SigName" SG_ 2561142090 ScoreLateral "ScoreLateral";
BA_ "GenSigTimeoutTime_SGW_" SG_ 2561142090 ScoreLateral 5000;
BA_ "CI_ParId" SG_ 2561142090 ValidLateral "IB1761";
BA_ "CI_SigId" SG_ 2561142090 ValidLateral 14408;
BA_ "CI_SigName" SG_ 2561142090 ValidLateral "ValidLateral";
BA_ "GenSigTimeoutTime_SGW_" SG_ 2561142090 ValidLateral 5000;
BA_ "SigType" SG_ 2561142090 ValidLateral 4;
BA_ "CI_ParId" SG_ 2561142090 TrendLateral "IB1762";
BA_ "CI_SigId" SG_ 2561142090 TrendLateral 14409;
BA_ "CI_SigName" SG_ 2561142090 TrendLateral "TrendLateral";
BA_ "GenSigTimeoutTime_SGW_" SG_ 2561142090 TrendLateral 5000;
BA_ "CI_ParId" SG_ 2561142090 BenefitLateral "IB1763";
BA_ "CI_SigId" SG_ 2561142090 BenefitLateral 14410;
BA_ "CI_SigName" SG_ 2561142090 BenefitLateral "BenefitLateral";
BA_ "GenSigTimeoutTime_SGW_" SG_ 2561142090 BenefitLateral 5000;
BA_ "SigType" SG_ 2561142090 BenefitLateral 4;
BA_ "CI_ParId" SG_ 2561142090 WeightLateral "IB1764";
BA_ "CI_SigId" SG_ 2561142090 WeightLateral 14411;
BA_ "CI_SigName" SG_ 2561142090 WeightLateral "WeightLateral";
BA_ "GenSigTimeoutTime_SGW_" SG_ 2561142090 WeightLateral 5000;
BA_ "CI_ParId" SG_ 2561143114 NumEventsLateral "IB1765";
BA_ "CI_SigId" SG_ 2561143114 NumEventsLateral 14413;
BA_ "CI_SigName" SG_ 2561143114 NumEventsLateral "NumEventsLateral";
BA_ "GenSigTimeoutTime_SGW_" SG_ 2561143114 NumEventsLateral 5000;
BA_ "SigType" SG_ 2561143114 NumEventsLateral 1;
BA_ "CI_ParId" SG_ 2561143114 EvaluatedMetersLateral "IB1766";
BA_ "CI_SigId" SG_ 2561143114 EvaluatedMetersLateral 14414;
BA_ "CI_SigName" SG_ 2561143114 EvaluatedMetersLateral "EvaluatedMetersLateral";
BA_ "GenSigTimeoutTime_SGW_" SG_ 2561143114 EvaluatedMetersLateral 5000;
BA_ "SigType" SG_ 2561143114 EvaluatedMetersLateral 1;
BA_ "CI_ParId" SG_ 2561134666 ScoreLaneDpt "IB1767";
BA_ "CI_SigId" SG_ 2561134666 ScoreLaneDpt 14416;
BA_ "CI_SigName" SG_ 2561134666 ScoreLaneDpt "ScoreLaneDpt";
BA_ "GenSigTimeoutTime_SGW_" SG_ 2561134666 ScoreLaneDpt 5000;
BA_ "CI_ParId" SG_ 2561134666 ValidLaneDpt "IB1768";
BA_ "CI_SigId" SG_ 2561134666 ValidLaneDpt 14417;
BA_ "CI_SigName" SG_ 2561134666 ValidLaneDpt "ValidLaneDpt";
BA_ "GenSigTimeoutTime_SGW_" SG_ 2561134666 ValidLaneDpt 5000;
BA_ "SigType" SG_ 2561134666 ValidLaneDpt 4;
BA_ "CI_ParId" SG_ 2561134666 TrendLaneDpt "IB1769";
BA_ "CI_SigId" SG_ 2561134666 TrendLaneDpt 14418;
BA_ "CI_SigName" SG_ 2561134666 TrendLaneDpt "TrendLaneDpt";
BA_ "GenSigTimeoutTime_SGW_" SG_ 2561134666 TrendLaneDpt 5000;
BA_ "CI_ParId" SG_ 2561134666 BenefitLaneDpt "IB1770";
BA_ "CI_SigId" SG_ 2561134666 BenefitLaneDpt 14419;
BA_ "CI_SigName" SG_ 2561134666 BenefitLaneDpt "BenefitLaneDpt";
BA_ "GenSigTimeoutTime_SGW_" SG_ 2561134666 BenefitLaneDpt 5000;
BA_ "SigType" SG_ 2561134666 BenefitLaneDpt 4;
BA_ "CI_ParId" SG_ 2561134666 WeightLaneDpt "IB1771";
BA_ "CI_SigId" SG_ 2561134666 WeightLaneDpt 14420;
BA_ "CI_SigName" SG_ 2561134666 WeightLaneDpt "WeightLaneDpt";
BA_ "GenSigTimeoutTime_SGW_" SG_ 2561134666 WeightLaneDpt 5000;
BA_ "CI_ParId" SG_ 2561134922 EvaluatedSamplesLaneDpt "IB1772";
BA_ "CI_SigId" SG_ 2561134922 EvaluatedSamplesLaneDpt 14422;
BA_ "CI_SigName" SG_ 2561134922 EvaluatedSamplesLaneDpt "EvaluatedSamplesLaneDpt";
BA_ "GenSigTimeoutTime_SGW_" SG_ 2561134922 EvaluatedSamplesLaneDpt 5000;
BA_ "CI_ParId" SG_ 2561134922 EventLaneDpt "IB1773";
BA_ "CI_SigId" SG_ 2561134922 EventLaneDpt 14423;
BA_ "CI_SigName" SG_ 2561134922 EventLaneDpt "EventLaneDpt";
BA_ "GenSigTimeoutTime_SGW_" SG_ 2561134922 EventLaneDpt 5000;
BA_ "SigType" SG_ 2561134922 EventLaneDpt 4;
BA_ "CI_ParId" SG_ 2561142346 ScoreLongitudinal "IB1774";
BA_ "CI_SigId" SG_ 2561142346 ScoreLongitudinal 14425;
BA_ "CI_SigName" SG_ 2561142346 ScoreLongitudinal "ScoreLongitudinal";
BA_ "GenSigTimeoutTime_SGW_" SG_ 2561142346 ScoreLongitudinal 5000;
BA_ "CI_ParId" SG_ 2561142346 ValidLongitudinal "IB1775";
BA_ "CI_SigId" SG_ 2561142346 ValidLongitudinal 14426;
BA_ "CI_SigName" SG_ 2561142346 ValidLongitudinal "ValidLongitudinal";
BA_ "GenSigTimeoutTime_SGW_" SG_ 2561142346 ValidLongitudinal 5000;
BA_ "SigType" SG_ 2561142346 ValidLongitudinal 4;
BA_ "CI_ParId" SG_ 2561142346 TrendLongitudinal "IB1776";
BA_ "CI_SigId" SG_ 2561142346 TrendLongitudinal 14427;
BA_ "CI_SigName" SG_ 2561142346 TrendLongitudinal "TrendLongitudinal";
BA_ "GenSigTimeoutTime_SGW_" SG_ 2561142346 TrendLongitudinal 5000;
BA_ "CI_ParId" SG_ 2561142346 BenefitLongitudinal "IB1777";
BA_ "CI_SigId" SG_ 2561142346 BenefitLongitudinal 14428;
BA_ "CI_SigName" SG_ 2561142346 BenefitLongitudinal "BenefitLongitudinal";
BA_ "GenSigTimeoutTime_SGW_" SG_ 2561142346 BenefitLongitudinal 5000;
BA_ "SigType" SG_ 2561142346 BenefitLongitudinal 4;
BA_ "CI_ParId" SG_ 2561142346 WeightLongitudinal "IB1778";
BA_ "CI_SigId" SG_ 2561142346 WeightLongitudinal 14429;
BA_ "CI_SigName" SG_ 2561142346 WeightLongitudinal "WeightLongitudinal";
BA_ "GenSigTimeoutTime_SGW_" SG_ 2561142346 WeightLongitudinal 5000;
BA_ "CI_ParId" SG_ 2561143370 NumEventsLongitudinal "IB1779";
BA_ "CI_SigId" SG_ 2561143370 NumEventsLongitudinal 14431;
BA_ "CI_SigName" SG_ 2561143370 NumEventsLongitudinal "NumEventsLongitudinal";
BA_ "GenSigTimeoutTime_SGW_" SG_ 2561143370 NumEventsLongitudinal 5000;
BA_ "SigType" SG_ 2561143370 NumEventsLongitudinal 1;
BA_ "CI_ParId" SG_ 2561143370 EvalMetersLongitud "IB1780";
BA_ "CI_SigId" SG_ 2561143370 EvalMetersLongitud 14432;
BA_ "CI_SigName" SG_ 2561143370 EvalMetersLongitud "EvaluatedMetersLongitudinal";
BA_ "GenSigTimeoutTime_SGW_" SG_ 2561143370 EvalMetersLongitud 5000;
BA_ "SigType" SG_ 2561143370 EvalMetersLongitud 1;
BA_ "CI_ParId" SG_ 2561146186 ScoreMois "IB1781";
BA_ "CI_SigId" SG_ 2561146186 ScoreMois 14512;
BA_ "CI_SigName" SG_ 2561146186 ScoreMois "ScoreMois";
BA_ "GenSigTimeoutTime_SGW_" SG_ 2561146186 ScoreMois 5000;
BA_ "CI_ParId" SG_ 2561146186 ValidMois "IB1782";
BA_ "CI_SigId" SG_ 2561146186 ValidMois 14513;
BA_ "CI_SigName" SG_ 2561146186 ValidMois "ValidMois";
BA_ "GenSigTimeoutTime_SGW_" SG_ 2561146186 ValidMois 5000;
BA_ "SigType" SG_ 2561146186 ValidMois 4;
BA_ "CI_ParId" SG_ 2561146186 TrendMois "IB1783";
BA_ "CI_SigId" SG_ 2561146186 TrendMois 14514;
BA_ "CI_SigName" SG_ 2561146186 TrendMois "TrendMois";
BA_ "GenSigTimeoutTime_SGW_" SG_ 2561146186 TrendMois 5000;
BA_ "CI_ParId" SG_ 2561146186 BenefitMois "IB1784";
BA_ "CI_SigId" SG_ 2561146186 BenefitMois 14515;
BA_ "CI_SigName" SG_ 2561146186 BenefitMois "BenefitMois";
BA_ "GenSigTimeoutTime_SGW_" SG_ 2561146186 BenefitMois 5000;
BA_ "SigType" SG_ 2561146186 BenefitMois 4;
BA_ "CI_ParId" SG_ 2561146186 WeightMois "IB1785";
BA_ "CI_SigId" SG_ 2561146186 WeightMois 14516;
BA_ "CI_SigName" SG_ 2561146186 WeightMois "WeightMois";
BA_ "GenSigTimeoutTime_SGW_" SG_ 2561146186 WeightMois 5000;
BA_ "CI_ParId" SG_ 2561135178 NotificationTextId "IB1786";
BA_ "CI_SigId" SG_ 2561135178 NotificationTextId 14518;
BA_ "CI_SigName" SG_ 2561135178 NotificationTextId "NotificationTextId";
BA_ "GenSigTimeoutTime_SGW_" SG_ 2561135178 NotificationTextId 5000;
BA_ "CI_ParId" SG_ 2561135178 NotificationTypeId "IB1787";
BA_ "CI_SigId" SG_ 2561135178 NotificationTypeId 14519;
BA_ "CI_SigName" SG_ 2561135178 NotificationTypeId "NotificationTypeId";
BA_ "GenSigTimeoutTime_SGW_" SG_ 2561135178 NotificationTypeId 5000;
BA_ "CI_ParId" SG_ 2561135178 NotificationCritical "IB1788";
BA_ "CI_SigId" SG_ 2561135178 NotificationCritical 14520;
BA_ "CI_SigName" SG_ 2561135178 NotificationCritical "NotificationCritical";
BA_ "GenSigTimeoutTime_SGW_" SG_ 2561135178 NotificationCritical 5000;
BA_ "CI_ParId" SG_ 2561135178 NotificationEnabled "IB1789";
BA_ "CI_SigId" SG_ 2561135178 NotificationEnabled 14521;
BA_ "CI_SigName" SG_ 2561135178 NotificationEnabled "NotificationEnabled";
BA_ "GenSigTimeoutTime_SGW_" SG_ 2561135178 NotificationEnabled 5000;
BA_ "CI_ParId" SG_ 2561141322 IndexVehicleLoad "IB1925";
BA_ "CI_SigId" SG_ 2561141322 IndexVehicleLoad 14523;
BA_ "CI_SigName" SG_ 2561141322 IndexVehicleLoad "IndexVehicleLoad";
BA_ "GenSigTimeoutTime_SGW_" SG_ 2561141322 IndexVehicleLoad 5000;
BA_ "CI_ParId" SG_ 2561141322 IndexAltimetry "IB1926";
BA_ "CI_SigId" SG_ 2561141322 IndexAltimetry 14524;
BA_ "CI_SigName" SG_ 2561141322 IndexAltimetry "IndexAltimetry";
BA_ "GenSigTimeoutTime_SGW_" SG_ 2561141322 IndexAltimetry 5000;
BA_ "CI_ParId" SG_ 2561141322 IndexSpeedProfile "IB1927";
BA_ "CI_SigId" SG_ 2561141322 IndexSpeedProfile 14525;
BA_ "CI_SigName" SG_ 2561141322 IndexSpeedProfile "IndexSpeedProfile";
BA_ "GenSigTimeoutTime_SGW_" SG_ 2561141322 IndexSpeedProfile 5000;
BA_ "CI_ParId" SG_ 2561141322 IndexTortuosity "IB1928";
BA_ "CI_SigId" SG_ 2561141322 IndexTortuosity 14526;
BA_ "CI_SigName" SG_ 2561141322 IndexTortuosity "IndexTortuosity";
BA_ "GenSigTimeoutTime_SGW_" SG_ 2561141322 IndexTortuosity 5000;
BA_ "CI_ParId" SG_ 2561141322 IndexAtmosphericCond "IB1929";
BA_ "CI_SigId" SG_ 2561141322 IndexAtmosphericCond 14527;
BA_ "CI_SigName" SG_ 2561141322 IndexAtmosphericCond "IndexAtmosphericConditions";
BA_ "GenSigTimeoutTime_SGW_" SG_ 2561141322 IndexAtmosphericCond 5000;
BA_ "CI_ParId" SG_ 2561141322 IndexMissionSeverity "IB1930";
BA_ "CI_SigId" SG_ 2561141322 IndexMissionSeverity 14528;
BA_ "CI_SigName" SG_ 2561141322 IndexMissionSeverity "IndexMissionSeverity";
BA_ "GenSigTimeoutTime_SGW_" SG_ 2561141322 IndexMissionSeverity 5000;
BA_ "CI_ParId" SG_ 2561141322 IndexDegreeOfDificulty "IB1931";
BA_ "CI_SigId" SG_ 2561141322 IndexDegreeOfDificulty 14529;
BA_ "CI_SigName" SG_ 2561141322 IndexDegreeOfDificulty "IndexDegreeOfDificulty";
BA_ "GenSigTimeoutTime_SGW_" SG_ 2561141322 IndexDegreeOfDificulty 5000;
BA_ "CI_ParId" SG_ 2561141578 EstimVehWeight "IB1790";
BA_ "CI_SigId" SG_ 2561141578 EstimVehWeight 14531;
BA_ "CI_SigName" SG_ 2561141578 EstimVehWeight "EstimatedVehicleWeight";
BA_ "GenSigTimeoutTime_SGW_" SG_ 2561141578 EstimVehWeight 5000;
BA_ "CI_ParId" SG_ 2561141578 SlopeSoftUphillPerc "IB1791";
BA_ "CI_SigId" SG_ 2561141578 SlopeSoftUphillPerc 14532;
BA_ "CI_SigName" SG_ 2561141578 SlopeSoftUphillPerc "SlopeSoftUphillPerc";
BA_ "GenSigTimeoutTime_SGW_" SG_ 2561141578 SlopeSoftUphillPerc 5000;
BA_ "CI_ParId" SG_ 2561141578 SlopeUphillPerc "IB1792";
BA_ "CI_SigId" SG_ 2561141578 SlopeUphillPerc 14533;
BA_ "CI_SigName" SG_ 2561141578 SlopeUphillPerc "SlopeUphillPerc";
BA_ "GenSigTimeoutTime_SGW_" SG_ 2561141578 SlopeUphillPerc 5000;
BA_ "CI_ParId" SG_ 2561141578 SlopeSoftDownhillPerc "IB1793";
BA_ "CI_SigId" SG_ 2561141578 SlopeSoftDownhillPerc 14534;
BA_ "CI_SigName" SG_ 2561141578 SlopeSoftDownhillPerc "SlopeSoftDownhillPerc";
BA_ "GenSigTimeoutTime_SGW_" SG_ 2561141578 SlopeSoftDownhillPerc 5000;
BA_ "CI_ParId" SG_ 2561141578 SlopeDownhillPerc "IB1794";
BA_ "CI_SigId" SG_ 2561141578 SlopeDownhillPerc 14535;
BA_ "CI_SigName" SG_ 2561141578 SlopeDownhillPerc "SlopeDownhillPerc";
BA_ "GenSigTimeoutTime_SGW_" SG_ 2561141578 SlopeDownhillPerc 5000;
BA_ "CI_ParId" SG_ 2561141578 SlopeFlatPerc "IB1795";
BA_ "CI_SigId" SG_ 2561141578 SlopeFlatPerc 14536;
BA_ "CI_SigName" SG_ 2561141578 SlopeFlatPerc "SlopeFlatPerc";
BA_ "GenSigTimeoutTime_SGW_" SG_ 2561141578 SlopeFlatPerc 5000;
BA_ "CI_ParId" SG_ 2561141578 OverrevvingSeconds "IB1796";
BA_ "CI_SigId" SG_ 2561141578 OverrevvingSeconds 14537;
BA_ "CI_SigName" SG_ 2561141578 OverrevvingSeconds "OverrevvingSeconds";
BA_ "GenSigTimeoutTime_SGW_" SG_ 2561141578 OverrevvingSeconds 5000;
BA_ "SigType" SG_ 2561141578 OverrevvingSeconds 1;
BA_ "CI_ParId" SG_ 2561135434 OldDasPiswa "IB1797";
BA_ "CI_SigId" SG_ 2561135434 OldDasPiswa 14539;
BA_ "CI_SigName" SG_ 2561135434 OldDasPiswa "OldDasPiswa";
BA_ "GenSigTimeoutTime_SGW_" SG_ 2561135434 OldDasPiswa 5000;
BA_ "CI_ParId" SG_ 2561135434 OldDasStatus "IB1798";
BA_ "CI_SigId" SG_ 2561135434 OldDasStatus 14540;
BA_ "CI_SigName" SG_ 2561135434 OldDasStatus "OldDasStatus";
BA_ "GenSigTimeoutTime_SGW_" SG_ 2561135434 OldDasStatus 5000;
BA_ "CI_ParId" SG_ 2561135434 OldDasStop "IB1799";
BA_ "CI_SigId" SG_ 2561135434 OldDasStop 14541;
BA_ "CI_SigName" SG_ 2561135434 OldDasStop "OldDasStop";
BA_ "GenSigTimeoutTime_SGW_" SG_ 2561135434 OldDasStop 5000;
BA_ "SigType" SG_ 2561135434 OldDasStop 4;
BA_ "CI_ParId" SG_ 2561135434 OldDasWarning "IB1800";
BA_ "CI_SigId" SG_ 2561135434 OldDasWarning 14542;
BA_ "CI_SigName" SG_ 2561135434 OldDasWarning "OldDasWarning";
BA_ "GenSigTimeoutTime_SGW_" SG_ 2561135434 OldDasWarning 5000;
BA_ "SigType" SG_ 2561135434 OldDasWarning 4;
BA_ "CI_ParId" SG_ 2561135434 OldDasEnabled "IB1801";
BA_ "CI_SigId" SG_ 2561135434 OldDasEnabled 14543;
BA_ "CI_SigName" SG_ 2561135434 OldDasEnabled "OldDasEnabled";
BA_ "GenSigTimeoutTime_SGW_" SG_ 2561135434 OldDasEnabled 5000;
BA_ "SigType" SG_ 2561135434 OldDasEnabled 4;
BA_ "CI_ParId" SG_ 2561142858 AccelerometerAxis1 "IB1802";
BA_ "CI_SigId" SG_ 2561142858 AccelerometerAxis1 14545;
BA_ "CI_SigName" SG_ 2561142858 AccelerometerAxis1 "AccelerometerAxis1";
BA_ "GenSigTimeoutTime_SGW_" SG_ 2561142858 AccelerometerAxis1 5000;
BA_ "CI_ParId" SG_ 2561142858 AccelerometerAxis2 "IB1803";
BA_ "CI_SigId" SG_ 2561142858 AccelerometerAxis2 14546;
BA_ "CI_SigName" SG_ 2561142858 AccelerometerAxis2 "AccelerometerAxis2";
BA_ "GenSigTimeoutTime_SGW_" SG_ 2561142858 AccelerometerAxis2 5000;
BA_ "CI_ParId" SG_ 2561142858 AccelerometerAxis3 "IB1804";
BA_ "CI_SigId" SG_ 2561142858 AccelerometerAxis3 14547;
BA_ "CI_SigName" SG_ 2561142858 AccelerometerAxis3 "AccelerometerAxis3";
BA_ "GenSigTimeoutTime_SGW_" SG_ 2561142858 AccelerometerAxis3 5000;
BA_ "CI_ParId" SG_ 2561135690 ScorePecc "IB1805";
BA_ "CI_SigId" SG_ 2561135690 ScorePecc 14549;
BA_ "CI_SigName" SG_ 2561135690 ScorePecc "ScorePecc";
BA_ "GenSigTimeoutTime_SGW_" SG_ 2561135690 ScorePecc 5000;
BA_ "CI_ParId" SG_ 2561135690 ValidPecc "IB1806";
BA_ "CI_SigId" SG_ 2561135690 ValidPecc 14550;
BA_ "CI_SigName" SG_ 2561135690 ValidPecc "ValidPecc";
BA_ "GenSigTimeoutTime_SGW_" SG_ 2561135690 ValidPecc 5000;
BA_ "SigType" SG_ 2561135690 ValidPecc 4;
BA_ "CI_ParId" SG_ 2561135690 TrendPecc "IB1807";
BA_ "CI_SigId" SG_ 2561135690 TrendPecc 14551;
BA_ "CI_SigName" SG_ 2561135690 TrendPecc "TrendPecc";
BA_ "GenSigTimeoutTime_SGW_" SG_ 2561135690 TrendPecc 5000;
BA_ "CI_ParId" SG_ 2561135690 BenefitPecc "IB1808";
BA_ "CI_SigId" SG_ 2561135690 BenefitPecc 14552;
BA_ "CI_SigName" SG_ 2561135690 BenefitPecc "BenefitPecc";
BA_ "GenSigTimeoutTime_SGW_" SG_ 2561135690 BenefitPecc 5000;
BA_ "SigType" SG_ 2561135690 BenefitPecc 4;
BA_ "CI_ParId" SG_ 2561135690 WeightPecc "IB1809";
BA_ "CI_SigId" SG_ 2561135690 WeightPecc 14553;
BA_ "CI_SigName" SG_ 2561135690 WeightPecc "WeightPecc";
BA_ "GenSigTimeoutTime_SGW_" SG_ 2561135690 WeightPecc 5000;
BA_ "CI_ParId" SG_ 2561135946 EvalSamplesPecc "IB1810";
BA_ "CI_SigId" SG_ 2561135946 EvalSamplesPecc 14555;
BA_ "CI_SigName" SG_ 2561135946 EvalSamplesPecc "EvaluatedSamplesPecc";
BA_ "GenSigTimeoutTime_SGW_" SG_ 2561135946 EvalSamplesPecc 5000;
BA_ "CI_ParId" SG_ 2561135946 EventPecc "IB1811";
BA_ "CI_SigId" SG_ 2561135946 EventPecc 14556;
BA_ "CI_SigName" SG_ 2561135946 EventPecc "EventPecc";
BA_ "GenSigTimeoutTime_SGW_" SG_ 2561135946 EventPecc 5000;
BA_ "SigType" SG_ 2561135946 EventPecc 4;
BA_ "CI_ParId" SG_ 2561136202 ScoreRadar "IB1812";
BA_ "CI_SigId" SG_ 2561136202 ScoreRadar 14558;
BA_ "CI_SigName" SG_ 2561136202 ScoreRadar "ScoreRadar";
BA_ "GenSigTimeoutTime_SGW_" SG_ 2561136202 ScoreRadar 5000;
BA_ "CI_ParId" SG_ 2561136202 ValidRadar "IB1813";
BA_ "CI_SigId" SG_ 2561136202 ValidRadar 14559;
BA_ "CI_SigName" SG_ 2561136202 ValidRadar "ValidRadar";
BA_ "GenSigTimeoutTime_SGW_" SG_ 2561136202 ValidRadar 5000;
BA_ "SigType" SG_ 2561136202 ValidRadar 4;
BA_ "CI_ParId" SG_ 2561136202 TrendRadar "IB1814";
BA_ "CI_SigId" SG_ 2561136202 TrendRadar 14560;
BA_ "CI_SigName" SG_ 2561136202 TrendRadar "TrendRadar";
BA_ "GenSigTimeoutTime_SGW_" SG_ 2561136202 TrendRadar 5000;
BA_ "CI_ParId" SG_ 2561136202 BenefitRadar "IB1815";
BA_ "CI_SigId" SG_ 2561136202 BenefitRadar 14561;
BA_ "CI_SigName" SG_ 2561136202 BenefitRadar "BenefitRadar";
BA_ "GenSigTimeoutTime_SGW_" SG_ 2561136202 BenefitRadar 5000;
BA_ "SigType" SG_ 2561136202 BenefitRadar 4;
BA_ "CI_ParId" SG_ 2561136202 WeightRadar "IB1816";
BA_ "CI_SigId" SG_ 2561136202 WeightRadar 14562;
BA_ "CI_SigName" SG_ 2561136202 WeightRadar "WeightRadar";
BA_ "GenSigTimeoutTime_SGW_" SG_ 2561136202 WeightRadar 5000;
BA_ "CI_ParId" SG_ 2561136458 EvalSamplesRadar "IB1817";
BA_ "CI_SigId" SG_ 2561136458 EvalSamplesRadar 14564;
BA_ "CI_SigName" SG_ 2561136458 EvalSamplesRadar "EvaluatedSamplesRadar";
BA_ "GenSigTimeoutTime_SGW_" SG_ 2561136458 EvalSamplesRadar 5000;
BA_ "CI_ParId" SG_ 2561136458 EventRadar "IB1818";
BA_ "CI_SigId" SG_ 2561136458 EventRadar 14565;
BA_ "CI_SigName" SG_ 2561136458 EventRadar "EventRadar";
BA_ "GenSigTimeoutTime_SGW_" SG_ 2561136458 EventRadar 5000;
BA_ "SigType" SG_ 2561136458 EventRadar 4;
BA_ "CI_ParId" SG_ 2561136714 ScoreRpm "IB1819";
BA_ "CI_SigId" SG_ 2561136714 ScoreRpm 14567;
BA_ "CI_SigName" SG_ 2561136714 ScoreRpm "ScoreRpm";
BA_ "GenSigTimeoutTime_SGW_" SG_ 2561136714 ScoreRpm 5000;
BA_ "CI_ParId" SG_ 2561136714 ValidRpm "IB1820";
BA_ "CI_SigId" SG_ 2561136714 ValidRpm 14568;
BA_ "CI_SigName" SG_ 2561136714 ValidRpm "ValidRpm";
BA_ "GenSigTimeoutTime_SGW_" SG_ 2561136714 ValidRpm 5000;
BA_ "SigType" SG_ 2561136714 ValidRpm 4;
BA_ "CI_ParId" SG_ 2561136714 TrendRpm "IB1821";
BA_ "CI_SigId" SG_ 2561136714 TrendRpm 14569;
BA_ "CI_SigName" SG_ 2561136714 TrendRpm "TrendRpm";
BA_ "GenSigTimeoutTime_SGW_" SG_ 2561136714 TrendRpm 5000;
BA_ "CI_ParId" SG_ 2561136714 BenefitRpm "IB1822";
BA_ "CI_SigId" SG_ 2561136714 BenefitRpm 14570;
BA_ "CI_SigName" SG_ 2561136714 BenefitRpm "BenefitRpm";
BA_ "GenSigTimeoutTime_SGW_" SG_ 2561136714 BenefitRpm 5000;
BA_ "SigType" SG_ 2561136714 BenefitRpm 4;
BA_ "CI_ParId" SG_ 2561136714 WeightRpm "IB1823";
BA_ "CI_SigId" SG_ 2561136714 WeightRpm 14571;
BA_ "CI_SigName" SG_ 2561136714 WeightRpm "WeightRpm";
BA_ "GenSigTimeoutTime_SGW_" SG_ 2561136714 WeightRpm 5000;
BA_ "CI_ParId" SG_ 2561136970 EvalSamplesRpm "IB1824";
BA_ "CI_SigId" SG_ 2561136970 EvalSamplesRpm 14573;
BA_ "CI_SigName" SG_ 2561136970 EvalSamplesRpm "EvaluatedSamplesRpm";
BA_ "GenSigTimeoutTime_SGW_" SG_ 2561136970 EvalSamplesRpm 5000;
BA_ "CI_ParId" SG_ 2561136970 EventRPM "IB1825";
BA_ "CI_SigId" SG_ 2561136970 EventRPM 14574;
BA_ "CI_SigName" SG_ 2561136970 EventRPM "EventRPM";
BA_ "GenSigTimeoutTime_SGW_" SG_ 2561136970 EventRPM 5000;
BA_ "CI_ParId" SG_ 2561136970 RPMLevel "IB1826";
BA_ "CI_SigId" SG_ 2561136970 RPMLevel 14575;
BA_ "CI_SigName" SG_ 2561136970 RPMLevel "RPMLevel";
BA_ "GenSigTimeoutTime_SGW_" SG_ 2561136970 RPMLevel 5000;
BA_ "SigType" SG_ 2561136970 RPMLevel 4;
BA_ "CI_ParId" SG_ 2561136970 RPMZone "IB1827";
BA_ "CI_SigId" SG_ 2561136970 RPMZone 14576;
BA_ "CI_SigName" SG_ 2561136970 RPMZone "RPMZone";
BA_ "GenSigTimeoutTime_SGW_" SG_ 2561136970 RPMZone 5000;
BA_ "SigType" SG_ 2561136970 RPMZone 4;
BA_ "CI_ParId" SG_ 2561136970 TorqueLevel "IB1828";
BA_ "CI_SigId" SG_ 2561136970 TorqueLevel 14577;
BA_ "CI_SigName" SG_ 2561136970 TorqueLevel "TorqueLevel";
BA_ "GenSigTimeoutTime_SGW_" SG_ 2561136970 TorqueLevel 5000;
BA_ "SigType" SG_ 2561136970 TorqueLevel 4;
BA_ "CI_ParId" SG_ 2561136970 HighRPMLimit "IB1829";
BA_ "CI_SigId" SG_ 2561136970 HighRPMLimit 14578;
BA_ "CI_SigName" SG_ 2561136970 HighRPMLimit "HighRPMLimit";
BA_ "GenSigTimeoutTime_SGW_" SG_ 2561136970 HighRPMLimit 5000;
BA_ "SigType" SG_ 2561136970 HighRPMLimit 1;
BA_ "CI_ParId" SG_ 2561136970 LowRPMLimit "IB1830";
BA_ "CI_SigId" SG_ 2561136970 LowRPMLimit 14579;
BA_ "CI_SigName" SG_ 2561136970 LowRPMLimit "LowRPMLimit";
BA_ "GenSigTimeoutTime_SGW_" SG_ 2561136970 LowRPMLimit 5000;
BA_ "SigType" SG_ 2561136970 LowRPMLimit 1;
BA_ "CI_ParId" SG_ 2561136970 HighRPMMalus "IB1831";
BA_ "CI_SigId" SG_ 2561136970 HighRPMMalus 14580;
BA_ "CI_SigName" SG_ 2561136970 HighRPMMalus "HighRPMMalus";
BA_ "GenSigTimeoutTime_SGW_" SG_ 2561136970 HighRPMMalus 5000;
BA_ "CI_ParId" SG_ 2561136970 LowRPMMalus "IB1832";
BA_ "CI_SigId" SG_ 2561136970 LowRPMMalus 14581;
BA_ "CI_SigName" SG_ 2561136970 LowRPMMalus "LowRPMMalus";
BA_ "GenSigTimeoutTime_SGW_" SG_ 2561136970 LowRPMMalus 5000;
BA_ "CI_ParId" SG_ 2561136970 MidRPMBonus "IB1833";
BA_ "CI_SigId" SG_ 2561136970 MidRPMBonus 14582;
BA_ "CI_SigName" SG_ 2561136970 MidRPMBonus "MidRPMBonus";
BA_ "GenSigTimeoutTime_SGW_" SG_ 2561136970 MidRPMBonus 5000;
BA_ "CI_ParId" SG_ 2561145162 ScoreSafeDistance "IB1834";
BA_ "CI_SigId" SG_ 2561145162 ScoreSafeDistance 14584;
BA_ "CI_SigName" SG_ 2561145162 ScoreSafeDistance "ScoreSafeDistance";
BA_ "GenSigTimeoutTime_SGW_" SG_ 2561145162 ScoreSafeDistance 5000;
BA_ "CI_ParId" SG_ 2561145162 ValidSafeDistance "IB1835";
BA_ "CI_SigId" SG_ 2561145162 ValidSafeDistance 14585;
BA_ "CI_SigName" SG_ 2561145162 ValidSafeDistance "ValidSafeDistance";
BA_ "GenSigTimeoutTime_SGW_" SG_ 2561145162 ValidSafeDistance 5000;
BA_ "SigType" SG_ 2561145162 ValidSafeDistance 4;
BA_ "CI_ParId" SG_ 2561145162 TrendSafeDistance "IB1836";
BA_ "CI_SigId" SG_ 2561145162 TrendSafeDistance 14586;
BA_ "CI_SigName" SG_ 2561145162 TrendSafeDistance "TrendSafeDistance";
BA_ "GenSigTimeoutTime_SGW_" SG_ 2561145162 TrendSafeDistance 5000;
BA_ "CI_ParId" SG_ 2561145162 BenefitSafeDistance "IB1837";
BA_ "CI_SigId" SG_ 2561145162 BenefitSafeDistance 14587;
BA_ "CI_SigName" SG_ 2561145162 BenefitSafeDistance "BenefitSafeDistance";
BA_ "GenSigTimeoutTime_SGW_" SG_ 2561145162 BenefitSafeDistance 5000;
BA_ "SigType" SG_ 2561145162 BenefitSafeDistance 4;
BA_ "CI_ParId" SG_ 2561145162 WeightSafeDistance "IB1838";
BA_ "CI_SigId" SG_ 2561145162 WeightSafeDistance 14588;
BA_ "CI_SigName" SG_ 2561145162 WeightSafeDistance "WeightSafeDistance";
BA_ "GenSigTimeoutTime_SGW_" SG_ 2561145162 WeightSafeDistance 5000;
BA_ "CI_ParId" SG_ 2561145418 ScoreSafePosition "IB1839";
BA_ "CI_SigId" SG_ 2561145418 ScoreSafePosition 14590;
BA_ "CI_SigName" SG_ 2561145418 ScoreSafePosition "ScoreSafePosition";
BA_ "GenSigTimeoutTime_SGW_" SG_ 2561145418 ScoreSafePosition 5000;
BA_ "CI_ParId" SG_ 2561145418 ValidSafePosition "IB1840";
BA_ "CI_SigId" SG_ 2561145418 ValidSafePosition 14591;
BA_ "CI_SigName" SG_ 2561145418 ValidSafePosition "ValidSafePosition";
BA_ "GenSigTimeoutTime_SGW_" SG_ 2561145418 ValidSafePosition 5000;
BA_ "SigType" SG_ 2561145418 ValidSafePosition 4;
BA_ "CI_ParId" SG_ 2561145418 TrendSafePosition "IB1841";
BA_ "CI_SigId" SG_ 2561145418 TrendSafePosition 14592;
BA_ "CI_SigName" SG_ 2561145418 TrendSafePosition "TrendSafePosition";
BA_ "GenSigTimeoutTime_SGW_" SG_ 2561145418 TrendSafePosition 5000;
BA_ "CI_ParId" SG_ 2561145418 BenefitSafePosition "IB1842";
BA_ "CI_SigId" SG_ 2561145418 BenefitSafePosition 14593;
BA_ "CI_SigName" SG_ 2561145418 BenefitSafePosition "BenefitSafePosition";
BA_ "GenSigTimeoutTime_SGW_" SG_ 2561145418 BenefitSafePosition 5000;
BA_ "SigType" SG_ 2561145418 BenefitSafePosition 4;
BA_ "CI_ParId" SG_ 2561145418 WeightSafePosition "IB1843";
BA_ "CI_SigId" SG_ 2561145418 WeightSafePosition 14594;
BA_ "CI_SigName" SG_ 2561145418 WeightSafePosition "WeightSafePosition";
BA_ "GenSigTimeoutTime_SGW_" SG_ 2561145418 WeightSafePosition 5000;
BA_ "CI_ParId" SG_ 2561137226 ScoreSafety "IB1844";
BA_ "CI_SigId" SG_ 2561137226 ScoreSafety 14596;
BA_ "CI_SigName" SG_ 2561137226 ScoreSafety "ScoreSafety";
BA_ "GenSigTimeoutTime_SGW_" SG_ 2561137226 ScoreSafety 5000;
BA_ "CI_ParId" SG_ 2561137226 ValidSafety "IB1845";
BA_ "CI_SigId" SG_ 2561137226 ValidSafety 14597;
BA_ "CI_SigName" SG_ 2561137226 ValidSafety "ValidSafety";
BA_ "GenSigTimeoutTime_SGW_" SG_ 2561137226 ValidSafety 5000;
BA_ "SigType" SG_ 2561137226 ValidSafety 4;
BA_ "CI_ParId" SG_ 2561137226 TrendSafety "IB1846";
BA_ "CI_SigId" SG_ 2561137226 TrendSafety 14598;
BA_ "CI_SigName" SG_ 2561137226 TrendSafety "TrendSafety";
BA_ "GenSigTimeoutTime_SGW_" SG_ 2561137226 TrendSafety 5000;
BA_ "CI_ParId" SG_ 2561137226 BenefitSafety "IB1847";
BA_ "CI_SigId" SG_ 2561137226 BenefitSafety 14599;
BA_ "CI_SigName" SG_ 2561137226 BenefitSafety "BenefitSafety";
BA_ "GenSigTimeoutTime_SGW_" SG_ 2561137226 BenefitSafety 5000;
BA_ "SigType" SG_ 2561137226 BenefitSafety 4;
BA_ "CI_ParId" SG_ 2561137226 WeightSafety "IB1848";
BA_ "CI_SigId" SG_ 2561137226 WeightSafety 14600;
BA_ "CI_SigName" SG_ 2561137226 WeightSafety "WeightSafety";
BA_ "GenSigTimeoutTime_SGW_" SG_ 2561137226 WeightSafety 5000;
BA_ "CI_ParId" SG_ 2561137482 ScoreTireSafety "IB1849";
BA_ "CI_SigId" SG_ 2561137482 ScoreTireSafety 14602;
BA_ "CI_SigName" SG_ 2561137482 ScoreTireSafety "ScoreTireSafety";
BA_ "GenSigTimeoutTime_SGW_" SG_ 2561137482 ScoreTireSafety 5000;
BA_ "CI_ParId" SG_ 2561137482 ValidTireSafety "IB1850";
BA_ "CI_SigId" SG_ 2561137482 ValidTireSafety 14603;
BA_ "CI_SigName" SG_ 2561137482 ValidTireSafety "ValidTireSafety";
BA_ "GenSigTimeoutTime_SGW_" SG_ 2561137482 ValidTireSafety 5000;
BA_ "SigType" SG_ 2561137482 ValidTireSafety 4;
BA_ "CI_ParId" SG_ 2561137482 TrendTireSafety "IB1851";
BA_ "CI_SigId" SG_ 2561137482 TrendTireSafety 14604;
BA_ "CI_SigName" SG_ 2561137482 TrendTireSafety "TrendTireSafety";
BA_ "GenSigTimeoutTime_SGW_" SG_ 2561137482 TrendTireSafety 5000;
BA_ "CI_ParId" SG_ 2561137482 BenefitTireSafety "IB1852";
BA_ "CI_SigId" SG_ 2561137482 BenefitTireSafety 14605;
BA_ "CI_SigName" SG_ 2561137482 BenefitTireSafety "BenefitTireSafety";
BA_ "GenSigTimeoutTime_SGW_" SG_ 2561137482 BenefitTireSafety 5000;
BA_ "SigType" SG_ 2561137482 BenefitTireSafety 4;
BA_ "CI_ParId" SG_ 2561137482 WeightTireSafety "IB1853";
BA_ "CI_SigId" SG_ 2561137482 WeightTireSafety 14606;
BA_ "CI_SigName" SG_ 2561137482 WeightTireSafety "WeightTireSafety";
BA_ "GenSigTimeoutTime_SGW_" SG_ 2561137482 WeightTireSafety 5000;
BA_ "CI_ParId" SG_ 2561137738 EvalMetersTireSafety "IB1854";
BA_ "CI_SigId" SG_ 2561137738 EvalMetersTireSafety 14608;
BA_ "CI_SigName" SG_ 2561137738 EvalMetersTireSafety "EvaluatedMetersTireSafety";
BA_ "GenSigTimeoutTime_SGW_" SG_ 2561137738 EvalMetersTireSafety 5000;
BA_ "SigType" SG_ 2561137738 EvalMetersTireSafety 1;
BA_ "CI_ParId" SG_ 2561137738 EventTireSafety "IB1855";
BA_ "CI_SigId" SG_ 2561137738 EventTireSafety 14609;
BA_ "CI_SigName" SG_ 2561137738 EventTireSafety "EventTireSafety";
BA_ "GenSigTimeoutTime_SGW_" SG_ 2561137738 EventTireSafety 5000;
BA_ "SigType" SG_ 2561137738 EventTireSafety 4;
BA_ "CI_ParId" SG_ 2561144650 ScoreSlowManeuver "IB1856";
BA_ "CI_SigId" SG_ 2561144650 ScoreSlowManeuver 14611;
BA_ "CI_SigName" SG_ 2561144650 ScoreSlowManeuver "ScoreSlowManeuver";
BA_ "GenSigTimeoutTime_SGW_" SG_ 2561144650 ScoreSlowManeuver 5000;
BA_ "CI_ParId" SG_ 2561144650 ValidSlowManeuver "IB1857";
BA_ "CI_SigId" SG_ 2561144650 ValidSlowManeuver 14612;
BA_ "CI_SigName" SG_ 2561144650 ValidSlowManeuver "ValidSlowManeuver";
BA_ "GenSigTimeoutTime_SGW_" SG_ 2561144650 ValidSlowManeuver 5000;
BA_ "SigType" SG_ 2561144650 ValidSlowManeuver 4;
BA_ "CI_ParId" SG_ 2561144650 TrendSlowManeuver "IB1858";
BA_ "CI_SigId" SG_ 2561144650 TrendSlowManeuver 14613;
BA_ "CI_SigName" SG_ 2561144650 TrendSlowManeuver "TrendSlowManeuver";
BA_ "GenSigTimeoutTime_SGW_" SG_ 2561144650 TrendSlowManeuver 5000;
BA_ "CI_ParId" SG_ 2561144650 BenefitSlowManeuver "IB1859";
BA_ "CI_SigId" SG_ 2561144650 BenefitSlowManeuver 14614;
BA_ "CI_SigName" SG_ 2561144650 BenefitSlowManeuver "BenefitSlowManeuver";
BA_ "GenSigTimeoutTime_SGW_" SG_ 2561144650 BenefitSlowManeuver 5000;
BA_ "SigType" SG_ 2561144650 BenefitSlowManeuver 4;
BA_ "CI_ParId" SG_ 2561144650 WeightSlowManeuver "IB1860";
BA_ "CI_SigId" SG_ 2561144650 WeightSlowManeuver 14615;
BA_ "CI_SigName" SG_ 2561144650 WeightSlowManeuver "WeightSlowManeuver";
BA_ "GenSigTimeoutTime_SGW_" SG_ 2561144650 WeightSlowManeuver 5000;
BA_ "CI_ParId" SG_ 2561144394 ScoreSpeed "IB1861";
BA_ "CI_SigId" SG_ 2561144394 ScoreSpeed 14617;
BA_ "CI_SigName" SG_ 2561144394 ScoreSpeed "ScoreSpeed";
BA_ "GenSigTimeoutTime_SGW_" SG_ 2561144394 ScoreSpeed 5000;
BA_ "CI_ParId" SG_ 2561144394 ValidSpeed "IB1862";
BA_ "CI_SigId" SG_ 2561144394 ValidSpeed 14618;
BA_ "CI_SigName" SG_ 2561144394 ValidSpeed "ValidSpeed";
BA_ "GenSigTimeoutTime_SGW_" SG_ 2561144394 ValidSpeed 5000;
BA_ "SigType" SG_ 2561144394 ValidSpeed 4;
BA_ "CI_ParId" SG_ 2561144394 TrendSpeed "IB1863";
BA_ "CI_SigId" SG_ 2561144394 TrendSpeed 14619;
BA_ "CI_SigName" SG_ 2561144394 TrendSpeed "TrendSpeed";
BA_ "GenSigTimeoutTime_SGW_" SG_ 2561144394 TrendSpeed 5000;
BA_ "CI_ParId" SG_ 2561144394 BenefitSpeed "IB1864";
BA_ "CI_SigId" SG_ 2561144394 BenefitSpeed 14620;
BA_ "CI_SigName" SG_ 2561144394 BenefitSpeed "BenefitSpeed";
BA_ "GenSigTimeoutTime_SGW_" SG_ 2561144394 BenefitSpeed 5000;
BA_ "SigType" SG_ 2561144394 BenefitSpeed 4;
BA_ "CI_ParId" SG_ 2561144394 WeightSpeed "IB1865";
BA_ "CI_SigId" SG_ 2561144394 WeightSpeed 14621;
BA_ "CI_SigName" SG_ 2561144394 WeightSpeed "WeightSpeed";
BA_ "GenSigTimeoutTime_SGW_" SG_ 2561144394 WeightSpeed 5000;
BA_ "CI_ParId" SG_ 2561137994 OdometerTripStart "IB1866";
BA_ "CI_SigId" SG_ 2561137994 OdometerTripStart 14623;
BA_ "CI_SigName" SG_ 2561137994 OdometerTripStart "OdometerTripStart";
BA_ "GenSigTimeoutTime_SGW_" SG_ 2561137994 OdometerTripStart 5000;
BA_ "SigType" SG_ 2561137994 OdometerTripStart 1;
BA_ "CI_ParId" SG_ 2561137994 TimeStampTripStart "IB1867";
BA_ "CI_SigId" SG_ 2561137994 TimeStampTripStart 14624;
BA_ "CI_SigName" SG_ 2561137994 TimeStampTripStart "TimeStampTripStart";
BA_ "GenSigTimeoutTime_SGW_" SG_ 2561137994 TimeStampTripStart 5000;
BA_ "SigType" SG_ 2561137994 TimeStampTripStart 1;
BA_ "CI_ParId" SG_ 2566875466 HarshRightTurn "IB796";
BA_ "CI_SigId" SG_ 2566875466 HarshRightTurn 1913;
BA_ "CI_SigName" SG_ 2566875466 HarshRightTurn "Harsh right turn";
BA_ "GenSigTimeoutTime_MulticII" SG_ 2566875466 HarshRightTurn 2500;
BA_ "GenSigTimeoutTime_MulticS" SG_ 2566875466 HarshRightTurn 2500;
BA_ "GenSigTimeoutTime_MulticS_" SG_ 2566875466 HarshRightTurn 2500;
BA_ "GenSigTimeoutTime_MulticS__" SG_ 2566875466 HarshRightTurn 2500;
BA_ "GenSigTimeoutTime_SGW_" SG_ 2566875466 HarshRightTurn 2500;
BA_ "SigType" SG_ 2566875466 HarshRightTurn 4;
BA_ "CI_ParId" SG_ 2566875466 HarshLeftTurn "IB797";
BA_ "CI_SigId" SG_ 2566875466 HarshLeftTurn 1914;
BA_ "CI_SigName" SG_ 2566875466 HarshLeftTurn "Harsh left turn";
BA_ "GenSigTimeoutTime_MulticII" SG_ 2566875466 HarshLeftTurn 2500;
BA_ "GenSigTimeoutTime_MulticS" SG_ 2566875466 HarshLeftTurn 2500;
BA_ "GenSigTimeoutTime_MulticS_" SG_ 2566875466 HarshLeftTurn 2500;
BA_ "GenSigTimeoutTime_MulticS__" SG_ 2566875466 HarshLeftTurn 2500;
BA_ "GenSigTimeoutTime_SGW_" SG_ 2566875466 HarshLeftTurn 2500;
BA_ "SigType" SG_ 2566875466 HarshLeftTurn 4;
BA_ "CI_ParId" SG_ 2566875466 HarshBrk "IB798";
BA_ "CI_SigId" SG_ 2566875466 HarshBrk 1915;
BA_ "CI_SigName" SG_ 2566875466 HarshBrk "Harsh braking";
BA_ "GenSigTimeoutTime_MulticII" SG_ 2566875466 HarshBrk 2500;
BA_ "GenSigTimeoutTime_MulticS" SG_ 2566875466 HarshBrk 2500;
BA_ "GenSigTimeoutTime_MulticS_" SG_ 2566875466 HarshBrk 2500;
BA_ "GenSigTimeoutTime_MulticS__" SG_ 2566875466 HarshBrk 2500;
BA_ "GenSigTimeoutTime_SGW_" SG_ 2566875466 HarshBrk 2500;
BA_ "SigType" SG_ 2566875466 HarshBrk 4;
BA_ "CI_ParId" SG_ 2566875466 HarshAccel "IB799";
BA_ "CI_SigId" SG_ 2566875466 HarshAccel 1916;
BA_ "CI_SigName" SG_ 2566875466 HarshAccel "Harsh acceleration";
BA_ "GenSigTimeoutTime_MulticII" SG_ 2566875466 HarshAccel 2500;
BA_ "GenSigTimeoutTime_MulticS" SG_ 2566875466 HarshAccel 2500;
BA_ "GenSigTimeoutTime_MulticS_" SG_ 2566875466 HarshAccel 2500;
BA_ "GenSigTimeoutTime_MulticS__" SG_ 2566875466 HarshAccel 2500;
BA_ "GenSigTimeoutTime_SGW_" SG_ 2566875466 HarshAccel 2500;
BA_ "SigType" SG_ 2566875466 HarshAccel 4;
BA_ "CI_ParId" SG_ 2566875466 HarshVertAccel_UP "IB800";
BA_ "CI_SigId" SG_ 2566875466 HarshVertAccel_UP 1917;
BA_ "CI_SigName" SG_ 2566875466 HarshVertAccel_UP "Harsh vertical acceleration (upwards)";
BA_ "GenSigTimeoutTime_MulticII" SG_ 2566875466 HarshVertAccel_UP 2500;
BA_ "GenSigTimeoutTime_MulticS" SG_ 2566875466 HarshVertAccel_UP 2500;
BA_ "GenSigTimeoutTime_MulticS_" SG_ 2566875466 HarshVertAccel_UP 2500;
BA_ "GenSigTimeoutTime_MulticS__" SG_ 2566875466 HarshVertAccel_UP 2500;
BA_ "GenSigTimeoutTime_SGW_" SG_ 2566875466 HarshVertAccel_UP 2500;
BA_ "SigType" SG_ 2566875466 HarshVertAccel_UP 4;
BA_ "CI_ParId" SG_ 2566875466 HarshVertAccel_Down "IB801";
BA_ "CI_SigId" SG_ 2566875466 HarshVertAccel_Down 1918;
BA_ "CI_SigName" SG_ 2566875466 HarshVertAccel_Down "Harsh vertical acceleration (downwards)";
BA_ "GenSigTimeoutTime_MulticII" SG_ 2566875466 HarshVertAccel_Down 2500;
BA_ "GenSigTimeoutTime_MulticS" SG_ 2566875466 HarshVertAccel_Down 2500;
BA_ "GenSigTimeoutTime_MulticS_" SG_ 2566875466 HarshVertAccel_Down 2500;
BA_ "GenSigTimeoutTime_MulticS__" SG_ 2566875466 HarshVertAccel_Down 2500;
BA_ "GenSigTimeoutTime_SGW_" SG_ 2566875466 HarshVertAccel_Down 2500;
BA_ "SigType" SG_ 2566875466 HarshVertAccel_Down 4;
BA_ "CI_ParId" SG_ 2566875466 MaxSpeedExc "IB802";
BA_ "CI_SigId" SG_ 2566875466 MaxSpeedExc 1919;
BA_ "CI_SigName" SG_ 2566875466 MaxSpeedExc "Maximum speed exceeded";
BA_ "GenSigTimeoutTime_MulticII" SG_ 2566875466 MaxSpeedExc 2500;
BA_ "GenSigTimeoutTime_MulticS" SG_ 2566875466 MaxSpeedExc 2500;
BA_ "GenSigTimeoutTime_MulticS_" SG_ 2566875466 MaxSpeedExc 2500;
BA_ "GenSigTimeoutTime_MulticS__" SG_ 2566875466 MaxSpeedExc 2500;
BA_ "GenSigTimeoutTime_SGW_" SG_ 2566875466 MaxSpeedExc 2500;
BA_ "SigType" SG_ 2566875466 MaxSpeedExc 4;
BA_ "CI_ParId" SG_ 2566875466 AccPedPrsTooLong "IB803";
BA_ "CI_SigId" SG_ 2566875466 AccPedPrsTooLong 1920;
BA_ "CI_SigName" SG_ 2566875466 AccPedPrsTooLong "Accelerator pedal pressed too long";
BA_ "GenSigTimeoutTime_MulticII" SG_ 2566875466 AccPedPrsTooLong 2500;
BA_ "GenSigTimeoutTime_MulticS" SG_ 2566875466 AccPedPrsTooLong 2500;
BA_ "GenSigTimeoutTime_MulticS_" SG_ 2566875466 AccPedPrsTooLong 2500;
BA_ "GenSigTimeoutTime_MulticS__" SG_ 2566875466 AccPedPrsTooLong 2500;
BA_ "GenSigTimeoutTime_SGW_" SG_ 2566875466 AccPedPrsTooLong 2500;
BA_ "SigType" SG_ 2566875466 AccPedPrsTooLong 4;
BA_ "CI_ParId" SG_ 2566875466 SpeedLim "IB804";
BA_ "CI_SigId" SG_ 2566875466 SpeedLim 1921;
BA_ "CI_SigName" SG_ 2566875466 SpeedLim "Speed limit";
BA_ "GenSigTimeoutTime_MulticII" SG_ 2566875466 SpeedLim 2500;
BA_ "GenSigTimeoutTime_MulticS" SG_ 2566875466 SpeedLim 2500;
BA_ "GenSigTimeoutTime_MulticS_" SG_ 2566875466 SpeedLim 2500;
BA_ "GenSigTimeoutTime_MulticS__" SG_ 2566875466 SpeedLim 2500;
BA_ "GenSigTimeoutTime_SGW_" SG_ 2566875466 SpeedLim 2500;
BA_ "SigType" SG_ 2566875466 SpeedLim 1;
BA_ "CI_ParId" SG_ 2566875466 GaugeMultifonction "IB805";
BA_ "CI_SigId" SG_ 2566875466 GaugeMultifonction 1922;
BA_ "CI_SigName" SG_ 2566875466 GaugeMultifonction "Gauge multifonction (not used)";
BA_ "GenSigTimeoutTime_MulticII" SG_ 2566875466 GaugeMultifonction 2500;
BA_ "GenSigTimeoutTime_MulticS" SG_ 2566875466 GaugeMultifonction 2500;
BA_ "GenSigTimeoutTime_MulticS_" SG_ 2566875466 GaugeMultifonction 2500;
BA_ "GenSigTimeoutTime_MulticS__" SG_ 2566875466 GaugeMultifonction 2500;
BA_ "GenSigTimeoutTime_SGW_" SG_ 2566875466 GaugeMultifonction 2500;
BA_ "SigType" SG_ 2566875466 GaugeMultifonction 1;
BA_ "CI_ParId" SG_ 2561138250 TripStarted "IB1868";
BA_ "CI_SigId" SG_ 2561138250 TripStarted 14626;
BA_ "CI_SigName" SG_ 2561138250 TripStarted "TripStarted";
BA_ "GenSigTimeoutTime_MulticS" SG_ 2561138250 TripStarted 5000;
BA_ "GenSigTimeoutTime_MulticS_" SG_ 2561138250 TripStarted 5000;
BA_ "GenSigTimeoutTime_MulticS__" SG_ 2561138250 TripStarted 5000;
BA_ "GenSigTimeoutTime_SGW_" SG_ 2561138250 TripStarted 5000;
BA_ "SigType" SG_ 2561138250 TripStarted 4;
BA_ "CI_ParId" SG_ 2561138250 TripEnded "IB1869";
BA_ "CI_SigId" SG_ 2561138250 TripEnded 14627;
BA_ "CI_SigName" SG_ 2561138250 TripEnded "TripEnded";
BA_ "GenSigTimeoutTime_MulticS" SG_ 2561138250 TripEnded 5000;
BA_ "GenSigTimeoutTime_MulticS_" SG_ 2561138250 TripEnded 5000;
BA_ "GenSigTimeoutTime_MulticS__" SG_ 2561138250 TripEnded 5000;
BA_ "GenSigTimeoutTime_SGW_" SG_ 2561138250 TripEnded 5000;
BA_ "SigType" SG_ 2561138250 TripEnded 4;
BA_ "CI_ParId" SG_ 2561138250 TripActive "IB1870";
BA_ "CI_SigId" SG_ 2561138250 TripActive 14628;
BA_ "CI_SigName" SG_ 2561138250 TripActive "TripActive";
BA_ "GenSigTimeoutTime_MulticS" SG_ 2561138250 TripActive 5000;
BA_ "GenSigTimeoutTime_MulticS_" SG_ 2561138250 TripActive 5000;
BA_ "GenSigTimeoutTime_MulticS__" SG_ 2561138250 TripActive 5000;
BA_ "GenSigTimeoutTime_SGW_" SG_ 2561138250 TripActive 5000;
BA_ "SigType" SG_ 2561138250 TripActive 4;
BA_ "CI_ParId" SG_ 2561138250 TripEndReason "IB1871";
BA_ "CI_SigId" SG_ 2561138250 TripEndReason 14629;
BA_ "CI_SigName" SG_ 2561138250 TripEndReason "TripEndReason";
BA_ "GenSigTimeoutTime_MulticS" SG_ 2561138250 TripEndReason 5000;
BA_ "GenSigTimeoutTime_MulticS_" SG_ 2561138250 TripEndReason 5000;
BA_ "GenSigTimeoutTime_MulticS__" SG_ 2561138250 TripEndReason 5000;
BA_ "GenSigTimeoutTime_SGW_" SG_ 2561138250 TripEndReason 5000;
BA_ "CI_ParId" SG_ 2561138506 ScoreStabilityControl "IB1872";
BA_ "CI_SigId" SG_ 2561138506 ScoreStabilityControl 14631;
BA_ "CI_SigName" SG_ 2561138506 ScoreStabilityControl "ScoreStabilityControl";
BA_ "GenSigTimeoutTime_SGW_" SG_ 2561138506 ScoreStabilityControl 5000;
BA_ "CI_ParId" SG_ 2561138506 ValidStabilityControl "IB1873";
BA_ "CI_SigId" SG_ 2561138506 ValidStabilityControl 14632;
BA_ "CI_SigName" SG_ 2561138506 ValidStabilityControl "ValidStabilityControl";
BA_ "GenSigTimeoutTime_SGW_" SG_ 2561138506 ValidStabilityControl 5000;
BA_ "SigType" SG_ 2561138506 ValidStabilityControl 4;
BA_ "CI_ParId" SG_ 2561138506 TrendStabilityControl "IB1874";
BA_ "CI_SigId" SG_ 2561138506 TrendStabilityControl 14633;
BA_ "CI_SigName" SG_ 2561138506 TrendStabilityControl "TrendStabilityControl";
BA_ "GenSigTimeoutTime_SGW_" SG_ 2561138506 TrendStabilityControl 5000;
BA_ "CI_ParId" SG_ 2561138506 BenefitStabilityControl "IB1875";
BA_ "CI_SigId" SG_ 2561138506 BenefitStabilityControl 14634;
BA_ "CI_SigName" SG_ 2561138506 BenefitStabilityControl "BenefitStabilityControl";
BA_ "GenSigTimeoutTime_SGW_" SG_ 2561138506 BenefitStabilityControl 5000;
BA_ "SigType" SG_ 2561138506 BenefitStabilityControl 4;
BA_ "CI_ParId" SG_ 2561138506 WeightStabilityControl "IB1876";
BA_ "CI_SigId" SG_ 2561138506 WeightStabilityControl 14635;
BA_ "CI_SigName" SG_ 2561138506 WeightStabilityControl "WeightStabilityControl";
BA_ "GenSigTimeoutTime_SGW_" SG_ 2561138506 WeightStabilityControl 5000;
BA_ "CI_ParId" SG_ 2561138762 EvalMetersStabilityCtrl "IB1877";
BA_ "CI_SigId" SG_ 2561138762 EvalMetersStabilityCtrl 14637;
BA_ "CI_SigName" SG_ 2561138762 EvalMetersStabilityCtrl "EvaluatedMetersStabilityControl";
BA_ "GenSigTimeoutTime_SGW_" SG_ 2561138762 EvalMetersStabilityCtrl 5000;
BA_ "CI_ParId" SG_ 2561138762 EventStabilityControl "IB1878";
BA_ "CI_SigId" SG_ 2561138762 EventStabilityControl 14638;
BA_ "CI_SigName" SG_ 2561138762 EventStabilityControl "EventStabilityControl";
BA_ "GenSigTimeoutTime_SGW_" SG_ 2561138762 EventStabilityControl 5000;
BA_ "SigType" SG_ 2561138762 EventStabilityControl 4;
BA_ "CI_ParId" SG_ 2561139018 ScoreStop "IB1879";
BA_ "CI_SigId" SG_ 2561139018 ScoreStop 14640;
BA_ "CI_SigName" SG_ 2561139018 ScoreStop "ScoreStop";
BA_ "GenSigTimeoutTime_SGW_" SG_ 2561139018 ScoreStop 5000;
BA_ "CI_ParId" SG_ 2561139018 ValidStop "IB1880";
BA_ "CI_SigId" SG_ 2561139018 ValidStop 14641;
BA_ "CI_SigName" SG_ 2561139018 ValidStop "ValidStop";
BA_ "GenSigTimeoutTime_SGW_" SG_ 2561139018 ValidStop 5000;
BA_ "SigType" SG_ 2561139018 ValidStop 4;
BA_ "CI_ParId" SG_ 2561139018 TrendStop "IB1881";
BA_ "CI_SigId" SG_ 2561139018 TrendStop 14642;
BA_ "CI_SigName" SG_ 2561139018 TrendStop "TrendStop";
BA_ "GenSigTimeoutTime_SGW_" SG_ 2561139018 TrendStop 5000;
BA_ "CI_ParId" SG_ 2561139018 BenefitStop "IB1882";
BA_ "CI_SigId" SG_ 2561139018 BenefitStop 14643;
BA_ "CI_SigName" SG_ 2561139018 BenefitStop "BenefitStop";
BA_ "GenSigTimeoutTime_SGW_" SG_ 2561139018 BenefitStop 5000;
BA_ "SigType" SG_ 2561139018 BenefitStop 4;
BA_ "CI_ParId" SG_ 2561139018 WeightStop "IB1883";
BA_ "CI_SigId" SG_ 2561139018 WeightStop 14644;
BA_ "CI_SigName" SG_ 2561139018 WeightStop "WeightStop";
BA_ "GenSigTimeoutTime_SGW_" SG_ 2561139018 WeightStop 5000;
BA_ "CI_ParId" SG_ 2561139274 EventStop "IB1884";
BA_ "CI_SigId" SG_ 2561139274 EventStop 14646;
BA_ "CI_SigName" SG_ 2561139274 EventStop "EventStop";
BA_ "GenSigTimeoutTime_SGW_" SG_ 2561139274 EventStop 5000;
BA_ "SigType" SG_ 2561139274 EventStop 4;
BA_ "CI_ParId" SG_ 2561139274 PanicBrakeState "IB1885";
BA_ "CI_SigId" SG_ 2561139274 PanicBrakeState 14647;
BA_ "CI_SigName" SG_ 2561139274 PanicBrakeState "PanicBrakeState";
BA_ "GenSigTimeoutTime_SGW_" SG_ 2561139274 PanicBrakeState 5000;
BA_ "SigType" SG_ 2561139274 PanicBrakeState 4;
BA_ "CI_ParId" SG_ 2561139274 DurationStop "IB1886";
BA_ "CI_SigId" SG_ 2561139274 DurationStop 14648;
BA_ "CI_SigName" SG_ 2561139274 DurationStop "DurationStop";
BA_ "GenSigTimeoutTime_SGW_" SG_ 2561139274 DurationStop 5000;
BA_ "SigType" SG_ 2561139274 DurationStop 1;
BA_ "CI_ParId" SG_ 2561139274 StartingSpeedStop "IB1887";
BA_ "CI_SigId" SG_ 2561139274 StartingSpeedStop 14649;
BA_ "CI_SigName" SG_ 2561139274 StartingSpeedStop "StartingSpeedStop";
BA_ "GenSigTimeoutTime_SGW_" SG_ 2561139274 StartingSpeedStop 5000;
BA_ "SigType" SG_ 2561139274 StartingSpeedStop 1;
BA_ "CI_ParId" SG_ 2561139274 LastManeuverScoreStop "IB1888";
BA_ "CI_SigId" SG_ 2561139274 LastManeuverScoreStop 14650;
BA_ "CI_SigName" SG_ 2561139274 LastManeuverScoreStop "LastManeuverScoreStop";
BA_ "GenSigTimeoutTime_SGW_" SG_ 2561139274 LastManeuverScoreStop 5000;
BA_ "CI_ParId" SG_ 2561139274 ManeuverCountStop "IB1889";
BA_ "CI_SigId" SG_ 2561139274 ManeuverCountStop 14651;
BA_ "CI_SigName" SG_ 2561139274 ManeuverCountStop "ManeuverCountStop";
BA_ "GenSigTimeoutTime_SGW_" SG_ 2561139274 ManeuverCountStop 5000;
BA_ "CI_ParId" SG_ 2561139274 MaxDecelerationStop "IB1890";
BA_ "CI_SigId" SG_ 2561139274 MaxDecelerationStop 14652;
BA_ "CI_SigName" SG_ 2561139274 MaxDecelerationStop "MaxDecelerationStop";
BA_ "GenSigTimeoutTime_SGW_" SG_ 2561139274 MaxDecelerationStop 5000;
BA_ "CI_ParId" SG_ 2561141066 EventLatitude "IB1891";
BA_ "CI_SigId" SG_ 2561141066 EventLatitude 14654;
BA_ "CI_SigName" SG_ 2561141066 EventLatitude "EventLatitude";
BA_ "GenSigTimeoutTime_SGW_" SG_ 2561141066 EventLatitude 5000;
BA_ "CI_ParId" SG_ 2561141066 EventLongitude "IB1892";
BA_ "CI_SigId" SG_ 2561141066 EventLongitude 14655;
BA_ "CI_SigName" SG_ 2561141066 EventLongitude "EventLongitude";
BA_ "GenSigTimeoutTime_SGW_" SG_ 2561141066 EventLongitude 5000;
BA_ "CI_ParId" SG_ 2561141066 EventAltitude "IB1893";
BA_ "CI_SigId" SG_ 2561141066 EventAltitude 14656;
BA_ "CI_SigName" SG_ 2561141066 EventAltitude "EventAltitude";
BA_ "GenSigTimeoutTime_SGW_" SG_ 2561141066 EventAltitude 5000;
BA_ "CI_ParId" SG_ 2561141066 EventVdop "IB1894";
BA_ "CI_SigId" SG_ 2561141066 EventVdop 14657;
BA_ "CI_SigName" SG_ 2561141066 EventVdop "EventVdop";
BA_ "GenSigTimeoutTime_SGW_" SG_ 2561141066 EventVdop 5000;
BA_ "CI_ParId" SG_ 2561141066 EventHdop "IB1895";
BA_ "CI_SigId" SG_ 2561141066 EventHdop 14658;
BA_ "CI_SigName" SG_ 2561141066 EventHdop "EventHdop";
BA_ "GenSigTimeoutTime_SGW_" SG_ 2561141066 EventHdop 5000;
BA_ "CI_ParId" SG_ 2561141066 EventValid "IB1896";
BA_ "CI_SigId" SG_ 2561141066 EventValid 14659;
BA_ "CI_SigName" SG_ 2561141066 EventValid "EventValid";
BA_ "GenSigTimeoutTime_SGW_" SG_ 2561141066 EventValid 5000;
BA_ "SigType" SG_ 2561141066 EventValid 4;
BA_ "CI_ParId" SG_ 2561139530 ScoreTire "IB1897";
BA_ "CI_SigId" SG_ 2561139530 ScoreTire 14661;
BA_ "CI_SigName" SG_ 2561139530 ScoreTire "ScoreTire";
BA_ "GenSigTimeoutTime_SGW_" SG_ 2561139530 ScoreTire 5000;
BA_ "CI_ParId" SG_ 2561139530 ValidTire "IB1898";
BA_ "CI_SigId" SG_ 2561139530 ValidTire 14662;
BA_ "CI_SigName" SG_ 2561139530 ValidTire "ValidTire";
BA_ "GenSigTimeoutTime_SGW_" SG_ 2561139530 ValidTire 5000;
BA_ "SigType" SG_ 2561139530 ValidTire 4;
BA_ "CI_ParId" SG_ 2561139530 TrendTire "IB1899";
BA_ "CI_SigId" SG_ 2561139530 TrendTire 14663;
BA_ "CI_SigName" SG_ 2561139530 TrendTire "TrendTire";
BA_ "GenSigTimeoutTime_SGW_" SG_ 2561139530 TrendTire 5000;
BA_ "CI_ParId" SG_ 2561139530 BenefitTire "IB1900";
BA_ "CI_SigId" SG_ 2561139530 BenefitTire 14664;
BA_ "CI_SigName" SG_ 2561139530 BenefitTire "BenefitTire";
BA_ "GenSigTimeoutTime_SGW_" SG_ 2561139530 BenefitTire 5000;
BA_ "SigType" SG_ 2561139530 BenefitTire 4;
BA_ "CI_ParId" SG_ 2561139530 WeightTire "IB1901";
BA_ "CI_SigId" SG_ 2561139530 WeightTire 14665;
BA_ "CI_SigName" SG_ 2561139530 WeightTire "WeightTire";
BA_ "GenSigTimeoutTime_SGW_" SG_ 2561139530 WeightTire 5000;
BA_ "CI_ParId" SG_ 2561139786 EvaluatedSamplesTire "IB1902";
BA_ "CI_SigId" SG_ 2561139786 EvaluatedSamplesTire 14667;
BA_ "CI_SigName" SG_ 2561139786 EvaluatedSamplesTire "EvaluatedSamplesTire";
BA_ "GenSigTimeoutTime_SGW_" SG_ 2561139786 EvaluatedSamplesTire 5000;
BA_ "CI_ParId" SG_ 2561139786 EventTireSaving "IB1903";
BA_ "CI_SigId" SG_ 2561139786 EventTireSaving 14668;
BA_ "CI_SigName" SG_ 2561139786 EventTireSaving "EventTireSaving";
BA_ "GenSigTimeoutTime_SGW_" SG_ 2561139786 EventTireSaving 5000;
BA_ "SigType" SG_ 2561139786 EventTireSaving 4;
BA_ "CI_ParId" SG_ 2561145674 ScoreAcceleration_TripB "IB1904";
BA_ "CI_SigId" SG_ 2561145674 ScoreAcceleration_TripB 14670;
BA_ "CI_SigName" SG_ 2561145674 ScoreAcceleration_TripB "ScoreAcceleration_TripB";
BA_ "GenSigTimeoutTime_MulticS" SG_ 2561145674 ScoreAcceleration_TripB 5000;
BA_ "GenSigTimeoutTime_MulticS_" SG_ 2561145674 ScoreAcceleration_TripB 5000;
BA_ "GenSigTimeoutTime_MulticS__" SG_ 2561145674 ScoreAcceleration_TripB 5000;
BA_ "GenSigTimeoutTime_SGW_" SG_ 2561145674 ScoreAcceleration_TripB 5000;
BA_ "CI_ParId" SG_ 2561145674 ScoreInertia_TripB "IB1905";
BA_ "CI_SigId" SG_ 2561145674 ScoreInertia_TripB 14671;
BA_ "CI_SigName" SG_ 2561145674 ScoreInertia_TripB "ScoreInertia_TripB";
BA_ "GenSigTimeoutTime_MulticS" SG_ 2561145674 ScoreInertia_TripB 5000;
BA_ "GenSigTimeoutTime_MulticS_" SG_ 2561145674 ScoreInertia_TripB 5000;
BA_ "GenSigTimeoutTime_MulticS__" SG_ 2561145674 ScoreInertia_TripB 5000;
BA_ "GenSigTimeoutTime_SGW_" SG_ 2561145674 ScoreInertia_TripB 5000;
BA_ "CI_ParId" SG_ 2561145674 ScoreStop_TripB "IB1906";
BA_ "CI_SigId" SG_ 2561145674 ScoreStop_TripB 14672;
BA_ "CI_SigName" SG_ 2561145674 ScoreStop_TripB "ScoreStop_TripB";
BA_ "GenSigTimeoutTime_MulticS" SG_ 2561145674 ScoreStop_TripB 5000;
BA_ "GenSigTimeoutTime_MulticS_" SG_ 2561145674 ScoreStop_TripB 5000;
BA_ "GenSigTimeoutTime_MulticS__" SG_ 2561145674 ScoreStop_TripB 5000;
BA_ "GenSigTimeoutTime_SGW_" SG_ 2561145674 ScoreStop_TripB 5000;
BA_ "CI_ParId" SG_ 2561145674 ScoreFuel_TripB "IB1907";
BA_ "CI_SigId" SG_ 2561145674 ScoreFuel_TripB 14673;
BA_ "CI_SigName" SG_ 2561145674 ScoreFuel_TripB "ScoreFuel_TripB";
BA_ "GenSigTimeoutTime_MulticS" SG_ 2561145674 ScoreFuel_TripB 5000;
BA_ "GenSigTimeoutTime_MulticS_" SG_ 2561145674 ScoreFuel_TripB 5000;
BA_ "GenSigTimeoutTime_MulticS__" SG_ 2561145674 ScoreFuel_TripB 5000;
BA_ "GenSigTimeoutTime_SGW_" SG_ 2561145674 ScoreFuel_TripB 5000;
BA_ "CI_ParId" SG_ 2561145674 TractionEnergyConsTripB "IB1908";
BA_ "CI_SigId" SG_ 2561145674 TractionEnergyConsTripB 14674;
BA_ "CI_SigName" SG_ 2561145674 TractionEnergyConsTripB "TractionEnergyConsumption_TripB";
BA_ "GenSigTimeoutTime_MulticS" SG_ 2561145674 TractionEnergyConsTripB 5000;
BA_ "GenSigTimeoutTime_MulticS_" SG_ 2561145674 TractionEnergyConsTripB 5000;
BA_ "GenSigTimeoutTime_MulticS__" SG_ 2561145674 TractionEnergyConsTripB 5000;
BA_ "GenSigTimeoutTime_SGW_" SG_ 2561145674 TractionEnergyConsTripB 5000;
BA_ "CI_ParId" SG_ 2561144906 ScoreVehicleControl "IB1909";
BA_ "CI_SigId" SG_ 2561144906 ScoreVehicleControl 14676;
BA_ "CI_SigName" SG_ 2561144906 ScoreVehicleControl "ScoreVehicleControl";
BA_ "GenSigTimeoutTime_SGW_" SG_ 2561144906 ScoreVehicleControl 5000;
BA_ "CI_ParId" SG_ 2561144906 ValidVehicleControl "IB1910";
BA_ "CI_SigId" SG_ 2561144906 ValidVehicleControl 14677;
BA_ "CI_SigName" SG_ 2561144906 ValidVehicleControl "ValidVehicleControl";
BA_ "GenSigTimeoutTime_SGW_" SG_ 2561144906 ValidVehicleControl 5000;
BA_ "SigType" SG_ 2561144906 ValidVehicleControl 4;
BA_ "CI_ParId" SG_ 2561144906 TrendVehicleControl "IB1911";
BA_ "CI_SigId" SG_ 2561144906 TrendVehicleControl 14678;
BA_ "CI_SigName" SG_ 2561144906 TrendVehicleControl "TrendVehicleControl";
BA_ "GenSigTimeoutTime_SGW_" SG_ 2561144906 TrendVehicleControl 5000;
BA_ "CI_ParId" SG_ 2561144906 BenefitVehicleControl "IB1912";
BA_ "CI_SigId" SG_ 2561144906 BenefitVehicleControl 14679;
BA_ "CI_SigName" SG_ 2561144906 BenefitVehicleControl "BenefitVehicleControl";
BA_ "GenSigTimeoutTime_SGW_" SG_ 2561144906 BenefitVehicleControl 5000;
BA_ "SigType" SG_ 2561144906 BenefitVehicleControl 4;
BA_ "CI_ParId" SG_ 2561144906 WeightVehicleControl "IB1913";
BA_ "CI_SigId" SG_ 2561144906 WeightVehicleControl 14680;
BA_ "CI_SigName" SG_ 2561144906 WeightVehicleControl "WeightVehicleControl";
BA_ "GenSigTimeoutTime_SGW_" SG_ 2561144906 WeightVehicleControl 5000;
BA_ "CI_ParId" SG_ 2561140298 VersionMajor "IB1914";
BA_ "CI_SigId" SG_ 2561140298 VersionMajor 14682;
BA_ "CI_SigName" SG_ 2561140298 VersionMajor "VersionMajor";
BA_ "GenSigTimeoutTime_SGW_" SG_ 2561140298 VersionMajor 5000;
BA_ "CI_ParId" SG_ 2561140298 VersionMinor "IB1915";
BA_ "CI_SigId" SG_ 2561140298 VersionMinor 14683;
BA_ "CI_SigName" SG_ 2561140298 VersionMinor "VersionMinor";
BA_ "GenSigTimeoutTime_SGW_" SG_ 2561140298 VersionMinor 5000;
BA_ "CI_ParId" SG_ 2561140298 VersionModel "IB1916";
BA_ "CI_SigId" SG_ 2561140298 VersionModel 14684;
BA_ "CI_SigName" SG_ 2561140298 VersionModel "VersionModel";
BA_ "GenSigTimeoutTime_SGW_" SG_ 2561140298 VersionModel 5000;
BA_ "CI_ParId" SG_ 2561140298 VersionRevision "IB1917";
BA_ "CI_SigId" SG_ 2561140298 VersionRevision 14685;
BA_ "CI_SigName" SG_ 2561140298 VersionRevision "VersionRevision";
BA_ "GenSigTimeoutTime_SGW_" SG_ 2561140298 VersionRevision 5000;
BA_ "CI_ParId" SG_ 2561142602 ScoreVertical "IB1918";
BA_ "CI_SigId" SG_ 2561142602 ScoreVertical 14687;
BA_ "CI_SigName" SG_ 2561142602 ScoreVertical "ScoreVertical";
BA_ "GenSigTimeoutTime_SGW_" SG_ 2561142602 ScoreVertical 5000;
BA_ "CI_ParId" SG_ 2561142602 ValidVertical "IB1919";
BA_ "CI_SigId" SG_ 2561142602 ValidVertical 14688;
BA_ "CI_SigName" SG_ 2561142602 ValidVertical "ValidVertical";
BA_ "GenSigTimeoutTime_SGW_" SG_ 2561142602 ValidVertical 5000;
BA_ "SigType" SG_ 2561142602 ValidVertical 4;
BA_ "CI_ParId" SG_ 2561142602 TrendVertical "IB1920";
BA_ "CI_SigId" SG_ 2561142602 TrendVertical 14689;
BA_ "CI_SigName" SG_ 2561142602 TrendVertical "TrendVertical";
BA_ "GenSigTimeoutTime_SGW_" SG_ 2561142602 TrendVertical 5000;
BA_ "CI_ParId" SG_ 2561142602 BenefitVertical "IB1921";
BA_ "CI_SigId" SG_ 2561142602 BenefitVertical 14690;
BA_ "CI_SigName" SG_ 2561142602 BenefitVertical "BenefitVertical";
BA_ "GenSigTimeoutTime_SGW_" SG_ 2561142602 BenefitVertical 5000;
BA_ "SigType" SG_ 2561142602 BenefitVertical 4;
BA_ "CI_ParId" SG_ 2561142602 WeightVertical "IB1922";
BA_ "CI_SigId" SG_ 2561142602 WeightVertical 14691;
BA_ "CI_SigName" SG_ 2561142602 WeightVertical "WeightVertical";
BA_ "GenSigTimeoutTime_SGW_" SG_ 2561142602 WeightVertical 5000;
BA_ "CI_ParId" SG_ 2561143626 NumEventsVertical "IB1923";
BA_ "CI_SigId" SG_ 2561143626 NumEventsVertical 14693;
BA_ "CI_SigName" SG_ 2561143626 NumEventsVertical "NumEventsVertical";
BA_ "GenSigTimeoutTime_SGW_" SG_ 2561143626 NumEventsVertical 5000;
BA_ "SigType" SG_ 2561143626 NumEventsVertical 1;
BA_ "CI_ParId" SG_ 2561143626 EvalMetersVertical "IB1924";
BA_ "CI_SigId" SG_ 2561143626 EvalMetersVertical 14694;
BA_ "CI_SigName" SG_ 2561143626 EvalMetersVertical "EvaluatedMetersVertical";
BA_ "GenSigTimeoutTime_SGW_" SG_ 2561143626 EvalMetersVertical 5000;
BA_ "SigType" SG_ 2561143626 EvalMetersVertical 1;
BA_ "CI_ParId" SG_ 2565865739 AsrEngCtrlActv "561";
BA_ "CI_SigId" SG_ 2565865739 AsrEngCtrlActv 231;
BA_ "CI_SigName" SG_ 2565865739 AsrEngCtrlActv "ASR Engine Control Active";
BA_ "GenSigTimeoutTime_ADCU" SG_ 2565865739 AsrEngCtrlActv 500;
BA_ "GenSigTimeoutTime_DICO" SG_ 2565865739 AsrEngCtrlActv 500;
BA_ "GenSigTimeoutTime_DiwaNXT" SG_ 2565865739 AsrEngCtrlActv 500;
BA_ "GenSigTimeoutTime_DiwaNXT_MH" SG_ 2565865739 AsrEngCtrlActv 500;
BA_ "GenSigTimeoutTime_ELFA3" SG_ 2565865739 AsrEngCtrlActv 500;
BA_ "GenSigTimeoutTime_Ecolife2" SG_ 2565865739 AsrEngCtrlActv 500;
BA_ "GenSigTimeoutTime_MulticII" SG_ 2565865739 AsrEngCtrlActv 500;
BA_ "GenSigTimeoutTime_MulticS" SG_ 2565865739 AsrEngCtrlActv 500;
BA_ "GenSigTimeoutTime_MulticS_" SG_ 2565865739 AsrEngCtrlActv 500;
BA_ "GenSigTimeoutTime_MulticS__" SG_ 2565865739 AsrEngCtrlActv 500;
BA_ "GenSigTimeoutTime_PCM" SG_ 2565865739 AsrEngCtrlActv 500;
BA_ "GenSigTimeoutTime_SGW__" SG_ 2565865739 AsrEngCtrlActv 500;
BA_ "GenSigTimeoutTime_VCM" SG_ 2565865739 AsrEngCtrlActv 500;
BA_ "GenSigTimeoutTime_VCU_" SG_ 2565865739 AsrEngCtrlActv 500;
BA_ "GenSigTimeoutTime_VMU" SG_ 2565865739 AsrEngCtrlActv 500;
BA_ "SPN" SG_ 2565865739 AsrEngCtrlActv 561;
BA_ "SigType" SG_ 2565865739 AsrEngCtrlActv 4;
BA_ "CI_ParId" SG_ 2565865739 AsrBrkCtrlActv "562";
BA_ "CI_SigId" SG_ 2565865739 AsrBrkCtrlActv 232;
BA_ "CI_SigName" SG_ 2565865739 AsrBrkCtrlActv "ASR Brake Control Active";
BA_ "GenSigTimeoutTime_ADCU" SG_ 2565865739 AsrBrkCtrlActv 500;
BA_ "GenSigTimeoutTime_DICO" SG_ 2565865739 AsrBrkCtrlActv 500;
BA_ "GenSigTimeoutTime_DiwaNXT" SG_ 2565865739 AsrBrkCtrlActv 500;
BA_ "GenSigTimeoutTime_DiwaNXT_MH" SG_ 2565865739 AsrBrkCtrlActv 500;
BA_ "GenSigTimeoutTime_ELFA3" SG_ 2565865739 AsrBrkCtrlActv 500;
BA_ "GenSigTimeoutTime_Ecolife2" SG_ 2565865739 AsrBrkCtrlActv 500;
BA_ "GenSigTimeoutTime_MulticII" SG_ 2565865739 AsrBrkCtrlActv 500;
BA_ "GenSigTimeoutTime_MulticS" SG_ 2565865739 AsrBrkCtrlActv 500;
BA_ "GenSigTimeoutTime_MulticS_" SG_ 2565865739 AsrBrkCtrlActv 500;
BA_ "GenSigTimeoutTime_MulticS__" SG_ 2565865739 AsrBrkCtrlActv 500;
BA_ "GenSigTimeoutTime_PCM" SG_ 2565865739 AsrBrkCtrlActv 500;
BA_ "GenSigTimeoutTime_SGW__" SG_ 2565865739 AsrBrkCtrlActv 500;
BA_ "GenSigTimeoutTime_VCM" SG_ 2565865739 AsrBrkCtrlActv 500;
BA_ "GenSigTimeoutTime_VCU_" SG_ 2565865739 AsrBrkCtrlActv 500;
BA_ "GenSigTimeoutTime_VMU" SG_ 2565865739 AsrBrkCtrlActv 500;
BA_ "SPN" SG_ 2565865739 AsrBrkCtrlActv 562;
BA_ "SigType" SG_ 2565865739 AsrBrkCtrlActv 4;
BA_ "CI_ParId" SG_ 2565865739 AbsActv "563";
BA_ "CI_SigId" SG_ 2565865739 AbsActv 233;
BA_ "CI_SigName" SG_ 2565865739 AbsActv "Anti-Lock Braking (ABS) Active";
BA_ "GenSigTimeoutTime_ADCU" SG_ 2565865739 AbsActv 500;
BA_ "GenSigTimeoutTime_DICO" SG_ 2565865739 AbsActv 500;
BA_ "GenSigTimeoutTime_DiwaNXT" SG_ 2565865739 AbsActv 500;
BA_ "GenSigTimeoutTime_DiwaNXT_MH" SG_ 2565865739 AbsActv 500;
BA_ "GenSigTimeoutTime_ELFA3" SG_ 2565865739 AbsActv 500;
BA_ "GenSigTimeoutTime_Ecolife2" SG_ 2565865739 AbsActv 500;
BA_ "GenSigTimeoutTime_MulticII" SG_ 2565865739 AbsActv 500;
BA_ "GenSigTimeoutTime_NBM" SG_ 2565865739 AbsActv 500;
BA_ "GenSigTimeoutTime_NBM_" SG_ 2565865739 AbsActv 500;
BA_ "GenSigTimeoutTime_NBM__" SG_ 2565865739 AbsActv 500;
BA_ "GenSigTimeoutTime_NBM___" SG_ 2565865739 AbsActv 500;
BA_ "GenSigTimeoutTime_PCM" SG_ 2565865739 AbsActv 500;
BA_ "GenSigTimeoutTime_SGW__" SG_ 2565865739 AbsActv 500;
BA_ "GenSigTimeoutTime_VCM" SG_ 2565865739 AbsActv 500;
BA_ "GenSigTimeoutTime_VCU_" SG_ 2565865739 AbsActv 500;
BA_ "GenSigTimeoutTime_VMU" SG_ 2565865739 AbsActv 500;
BA_ "SPN" SG_ 2565865739 AbsActv 563;
BA_ "SigType" SG_ 2565865739 AbsActv 4;
BA_ "CI_ParId" SG_ 2565865739 BrkPedPos "521";
BA_ "CI_SigId" SG_ 2565865739 BrkPedPos 235;
BA_ "CI_SigName" SG_ 2565865739 BrkPedPos "Brake Pedal Position";
BA_ "GenSigTimeoutTime_ADCU" SG_ 2565865739 BrkPedPos 500;
BA_ "GenSigTimeoutTime_DICO" SG_ 2565865739 BrkPedPos 500;
BA_ "GenSigTimeoutTime_DiwaNXT" SG_ 2565865739 BrkPedPos 500;
BA_ "GenSigTimeoutTime_DiwaNXT_MH" SG_ 2565865739 BrkPedPos 500;
BA_ "GenSigTimeoutTime_ELFA3" SG_ 2565865739 BrkPedPos 500;
BA_ "GenSigTimeoutTime_Ecolife2" SG_ 2565865739 BrkPedPos 500;
BA_ "GenSigTimeoutTime_FMS4" SG_ 2565865739 BrkPedPos 500;
BA_ "GenSigTimeoutTime_MulticII" SG_ 2565865739 BrkPedPos 500;
BA_ "GenSigTimeoutTime_NBM" SG_ 2565865739 BrkPedPos 500;
BA_ "GenSigTimeoutTime_NBM_" SG_ 2565865739 BrkPedPos 500;
BA_ "GenSigTimeoutTime_NBM__" SG_ 2565865739 BrkPedPos 500;
BA_ "GenSigTimeoutTime_NBM___" SG_ 2565865739 BrkPedPos 500;
BA_ "GenSigTimeoutTime_PCM" SG_ 2565865739 BrkPedPos 500;
BA_ "GenSigTimeoutTime_SGW__" SG_ 2565865739 BrkPedPos 500;
BA_ "GenSigTimeoutTime_VCM" SG_ 2565865739 BrkPedPos 500;
BA_ "GenSigTimeoutTime_VCU_" SG_ 2565865739 BrkPedPos 500;
BA_ "GenSigTimeoutTime_VMU" SG_ 2565865739 BrkPedPos 500;
BA_ "SPN" SG_ 2565865739 BrkPedPos 521;
BA_ "SigType" SG_ 2565865739 BrkPedPos 1;
BA_ "CI_ParId" SG_ 2565865739 AbsFullyOp "1243";
BA_ "CI_SigId" SG_ 2565865739 AbsFullyOp 245;
BA_ "CI_SigName" SG_ 2565865739 AbsFullyOp "ABS Fully Operational";
BA_ "GenSigTimeoutTime_ADCU" SG_ 2565865739 AbsFullyOp 500;
BA_ "GenSigTimeoutTime_DiwaNXT" SG_ 2565865739 AbsFullyOp 500;
BA_ "GenSigTimeoutTime_DiwaNXT_MH" SG_ 2565865739 AbsFullyOp 500;
BA_ "GenSigTimeoutTime_Ecolife2" SG_ 2565865739 AbsFullyOp 500;
BA_ "GenSigTimeoutTime_IRCS" SG_ 2565865739 AbsFullyOp 500;
BA_ "GenSigTimeoutTime_MulticII" SG_ 2565865739 AbsFullyOp 500;
BA_ "GenSigTimeoutTime_MulticS__" SG_ 2565865739 AbsFullyOp 500;
BA_ "GenSigTimeoutTime_NBM__" SG_ 2565865739 AbsFullyOp 500;
BA_ "GenSigTimeoutTime_PCM" SG_ 2565865739 AbsFullyOp 500;
BA_ "GenSigTimeoutTime_SGW__" SG_ 2565865739 AbsFullyOp 500;
BA_ "GenSigTimeoutTime_VCM" SG_ 2565865739 AbsFullyOp 500;
BA_ "SPN" SG_ 2565865739 AbsFullyOp 1243;
BA_ "SigType" SG_ 2565865739 AbsFullyOp 4;
BA_ "CI_ParId" SG_ 2565865739 Atc_AsrInfoSig "1793";
BA_ "CI_SigId" SG_ 2565865739 Atc_AsrInfoSig 248;
BA_ "CI_SigName" SG_ 2565865739 Atc_AsrInfoSig "ATC/ASR Information Signal";
BA_ "GenSigTimeoutTime_MulticII" SG_ 2565865739 Atc_AsrInfoSig 500;
BA_ "GenSigTimeoutTime_MulticS__" SG_ 2565865739 Atc_AsrInfoSig 500;
BA_ "GenSigTimeoutTime_PCM" SG_ 2565865739 Atc_AsrInfoSig 500;
BA_ "GenSigTimeoutTime_SGW__" SG_ 2565865739 Atc_AsrInfoSig 500;
BA_ "GenSigTimeoutTime_VCM" SG_ 2565865739 Atc_AsrInfoSig 500;
BA_ "SPN" SG_ 2565865739 Atc_AsrInfoSig 1793;
BA_ "SigType" SG_ 2565865739 Atc_AsrInfoSig 4;
BA_ "CI_ParId" SG_ 2566831883 RelSpeedFaL "905";
BA_ "CI_SigId" SG_ 2566831883 RelSpeedFaL 268;
BA_ "CI_SigName" SG_ 2566831883 RelSpeedFaL "Relative Speed; Front Axle, Left Wheel";
BA_ "GenSigTimeoutTime_ADCU" SG_ 2566831883 RelSpeedFaL 500;
BA_ "GenSigTimeoutTime_ELFA3" SG_ 2566831883 RelSpeedFaL 500;
BA_ "GenSigTimeoutTime_FMS4" SG_ 2566831883 RelSpeedFaL 500;
BA_ "GenSigTimeoutTime_NBM__" SG_ 2566831883 RelSpeedFaL 500;
BA_ "GenSigTimeoutTime_NBM___" SG_ 2566831883 RelSpeedFaL 500;
BA_ "GenSigTimeoutTime_PCM" SG_ 2566831883 RelSpeedFaL 500;
BA_ "GenSigTimeoutTime_SGW__" SG_ 2566831883 RelSpeedFaL 500;
BA_ "GenSigTimeoutTime_VCM" SG_ 2566831883 RelSpeedFaL 500;
BA_ "SPN" SG_ 2566831883 RelSpeedFaL 905;
BA_ "SigType" SG_ 2566831883 RelSpeedFaL 1;
BA_ "CI_ParId" SG_ 2566831883 RelSpeedFaR "906";
BA_ "CI_SigId" SG_ 2566831883 RelSpeedFaR 269;
BA_ "CI_SigName" SG_ 2566831883 RelSpeedFaR "Relative Speed; Front Axle, Right Wheel";
BA_ "GenSigTimeoutTime_ADCU" SG_ 2566831883 RelSpeedFaR 500;
BA_ "GenSigTimeoutTime_ELFA3" SG_ 2566831883 RelSpeedFaR 500;
BA_ "GenSigTimeoutTime_FMS4" SG_ 2566831883 RelSpeedFaR 500;
BA_ "GenSigTimeoutTime_NBM__" SG_ 2566831883 RelSpeedFaR 500;
BA_ "GenSigTimeoutTime_NBM___" SG_ 2566831883 RelSpeedFaR 500;
BA_ "GenSigTimeoutTime_PCM" SG_ 2566831883 RelSpeedFaR 500;
BA_ "GenSigTimeoutTime_SGW__" SG_ 2566831883 RelSpeedFaR 500;
BA_ "GenSigTimeoutTime_VCM" SG_ 2566831883 RelSpeedFaR 500;
BA_ "SPN" SG_ 2566831883 RelSpeedFaR 906;
BA_ "SigType" SG_ 2566831883 RelSpeedFaR 1;
BA_ "CI_ParId" SG_ 2633935883 BrkLinRemFaL "1099";
BA_ "CI_SigId" SG_ 2633935883 BrkLinRemFaL 293;
BA_ "CI_SigName" SG_ 2633935883 BrkLinRemFaL "Brake Lining Remaining, Front Axle, Left Wheel";
BA_ "GenSigTimeoutTime_FMS4" SG_ 2633935883 BrkLinRemFaL 25000;
BA_ "GenSigTimeoutTime_MulticII" SG_ 2633935883 BrkLinRemFaL 25000;
BA_ "GenSigTimeoutTime_MulticS" SG_ 2633935883 BrkLinRemFaL 25000;
BA_ "GenSigTimeoutTime_MulticS_" SG_ 2633935883 BrkLinRemFaL 25000;
BA_ "GenSigTimeoutTime_MulticS__" SG_ 2633935883 BrkLinRemFaL 25000;
BA_ "GenSigTimeoutTime_PCM" SG_ 2633935883 BrkLinRemFaL 25000;
BA_ "GenSigTimeoutTime_SGW__" SG_ 2633935883 BrkLinRemFaL 25000;
BA_ "SPN" SG_ 2633935883 BrkLinRemFaL 1099;
BA_ "SigType" SG_ 2633935883 BrkLinRemFaL 1;
BA_ "CI_ParId" SG_ 2633935883 BrkLinRemFaR "1100";
BA_ "CI_SigId" SG_ 2633935883 BrkLinRemFaR 294;
BA_ "CI_SigName" SG_ 2633935883 BrkLinRemFaR "Brake Lining Remaining, Front Axle, Right Wheel";
BA_ "GenSigTimeoutTime_FMS4" SG_ 2633935883 BrkLinRemFaR 25000;
BA_ "GenSigTimeoutTime_MulticII" SG_ 2633935883 BrkLinRemFaR 25000;
BA_ "GenSigTimeoutTime_MulticS" SG_ 2633935883 BrkLinRemFaR 25000;
BA_ "GenSigTimeoutTime_MulticS_" SG_ 2633935883 BrkLinRemFaR 25000;
BA_ "GenSigTimeoutTime_MulticS__" SG_ 2633935883 BrkLinRemFaR 25000;
BA_ "GenSigTimeoutTime_PCM" SG_ 2633935883 BrkLinRemFaR 25000;
BA_ "GenSigTimeoutTime_SGW__" SG_ 2633935883 BrkLinRemFaR 25000;
BA_ "SPN" SG_ 2633935883 BrkLinRemFaR 1100;
BA_ "SigType" SG_ 2633935883 BrkLinRemFaR 1;
BA_ "CI_ParId" SG_ 2633935883 BrkLinRemRa1L "1101";
BA_ "CI_SigId" SG_ 2633935883 BrkLinRemRa1L 295;
BA_ "CI_SigName" SG_ 2633935883 BrkLinRemRa1L "Brake Lining Remaining, Rear Axle #1, Left Wheel";
BA_ "GenSigTimeoutTime_FMS4" SG_ 2633935883 BrkLinRemRa1L 25000;
BA_ "GenSigTimeoutTime_MulticII" SG_ 2633935883 BrkLinRemRa1L 25000;
BA_ "GenSigTimeoutTime_MulticS" SG_ 2633935883 BrkLinRemRa1L 25000;
BA_ "GenSigTimeoutTime_MulticS_" SG_ 2633935883 BrkLinRemRa1L 25000;
BA_ "GenSigTimeoutTime_MulticS__" SG_ 2633935883 BrkLinRemRa1L 25000;
BA_ "GenSigTimeoutTime_PCM" SG_ 2633935883 BrkLinRemRa1L 25000;
BA_ "GenSigTimeoutTime_SGW__" SG_ 2633935883 BrkLinRemRa1L 25000;
BA_ "SPN" SG_ 2633935883 BrkLinRemRa1L 1101;
BA_ "SigType" SG_ 2633935883 BrkLinRemRa1L 1;
BA_ "CI_ParId" SG_ 2633935883 BrkLinRemRa1R "1102";
BA_ "CI_SigId" SG_ 2633935883 BrkLinRemRa1R 296;
BA_ "CI_SigName" SG_ 2633935883 BrkLinRemRa1R "Brake Lining Remaining, Rear Axle #1, Right Wheel";
BA_ "GenSigTimeoutTime_FMS4" SG_ 2633935883 BrkLinRemRa1R 25000;
BA_ "GenSigTimeoutTime_MulticII" SG_ 2633935883 BrkLinRemRa1R 25000;
BA_ "GenSigTimeoutTime_MulticS" SG_ 2633935883 BrkLinRemRa1R 25000;
BA_ "GenSigTimeoutTime_MulticS_" SG_ 2633935883 BrkLinRemRa1R 25000;
BA_ "GenSigTimeoutTime_MulticS__" SG_ 2633935883 BrkLinRemRa1R 25000;
BA_ "GenSigTimeoutTime_PCM" SG_ 2633935883 BrkLinRemRa1R 25000;
BA_ "GenSigTimeoutTime_SGW__" SG_ 2633935883 BrkLinRemRa1R 25000;
BA_ "SPN" SG_ 2633935883 BrkLinRemRa1R 1102;
BA_ "SigType" SG_ 2633935883 BrkLinRemRa1R 1;
BA_ "CI_ParId" SG_ 2633935883 BrkLinRemRa2L "1103";
BA_ "CI_SigId" SG_ 2633935883 BrkLinRemRa2L 297;
BA_ "CI_SigName" SG_ 2633935883 BrkLinRemRa2L "Brake Lining Remaining, Rear Axle #2, Left Wheel";
BA_ "GenSigTimeoutTime_FMS4" SG_ 2633935883 BrkLinRemRa2L 25000;
BA_ "GenSigTimeoutTime_MulticII" SG_ 2633935883 BrkLinRemRa2L 25000;
BA_ "GenSigTimeoutTime_MulticS" SG_ 2633935883 BrkLinRemRa2L 25000;
BA_ "GenSigTimeoutTime_MulticS_" SG_ 2633935883 BrkLinRemRa2L 25000;
BA_ "GenSigTimeoutTime_MulticS__" SG_ 2633935883 BrkLinRemRa2L 25000;
BA_ "GenSigTimeoutTime_PCM" SG_ 2633935883 BrkLinRemRa2L 25000;
BA_ "GenSigTimeoutTime_SGW__" SG_ 2633935883 BrkLinRemRa2L 25000;
BA_ "SPN" SG_ 2633935883 BrkLinRemRa2L 1103;
BA_ "SigType" SG_ 2633935883 BrkLinRemRa2L 1;
BA_ "CI_ParId" SG_ 2633935883 BrkLinRemRa2R "1104";
BA_ "CI_SigId" SG_ 2633935883 BrkLinRemRa2R 298;
BA_ "CI_SigName" SG_ 2633935883 BrkLinRemRa2R "Brake Lining Remaining, Rear Axle #2, Right Wheel";
BA_ "GenSigTimeoutTime_FMS4" SG_ 2633935883 BrkLinRemRa2R 25000;
BA_ "GenSigTimeoutTime_MulticII" SG_ 2633935883 BrkLinRemRa2R 25000;
BA_ "GenSigTimeoutTime_MulticS" SG_ 2633935883 BrkLinRemRa2R 25000;
BA_ "GenSigTimeoutTime_MulticS_" SG_ 2633935883 BrkLinRemRa2R 25000;
BA_ "GenSigTimeoutTime_MulticS__" SG_ 2633935883 BrkLinRemRa2R 25000;
BA_ "GenSigTimeoutTime_PCM" SG_ 2633935883 BrkLinRemRa2R 25000;
BA_ "GenSigTimeoutTime_SGW__" SG_ 2633935883 BrkLinRemRa2R 25000;
BA_ "SPN" SG_ 2633935883 BrkLinRemRa2R 1104;
BA_ "SigType" SG_ 2633935883 BrkLinRemRa2R 1;
BA_ "CI_ParId" SG_ 2566767627 HaltBrkMode "2913";
BA_ "CI_SigId" SG_ 2566767627 HaltBrkMode 303;
BA_ "CI_SigName" SG_ 2566767627 HaltBrkMode "Halt brake mode";
BA_ "GenSigTimeoutTime_DICO" SG_ 2566767627 HaltBrkMode 500;
BA_ "GenSigTimeoutTime_Ecolife2" SG_ 2566767627 HaltBrkMode 500;
BA_ "GenSigTimeoutTime_MulticS" SG_ 2566767627 HaltBrkMode 500;
BA_ "GenSigTimeoutTime_MulticS_" SG_ 2566767627 HaltBrkMode 500;
BA_ "GenSigTimeoutTime_NBM" SG_ 2566767627 HaltBrkMode 500;
BA_ "GenSigTimeoutTime_NBM_" SG_ 2566767627 HaltBrkMode 500;
BA_ "GenSigTimeoutTime_NBM__" SG_ 2566767627 HaltBrkMode 500;
BA_ "GenSigTimeoutTime_NBM___" SG_ 2566767627 HaltBrkMode 500;
BA_ "GenSigTimeoutTime_PCM" SG_ 2566767627 HaltBrkMode 500;
BA_ "GenSigTimeoutTime_SGW__" SG_ 2566767627 HaltBrkMode 500;
BA_ "GenSigTimeoutTime_VCM" SG_ 2566767627 HaltBrkMode 500;
BA_ "GenSigTimeoutTime_VCU_" SG_ 2566767627 HaltBrkMode 500;
BA_ "GenSigTimeoutTime_VMU" SG_ 2566767627 HaltBrkMode 500;
BA_ "SPN" SG_ 2566767627 HaltBrkMode 2913;
BA_ "CI_ParId" SG_ 2566767627 HhMode "2912";
BA_ "CI_SigId" SG_ 2566767627 HhMode 304;
BA_ "CI_SigName" SG_ 2566767627 HhMode "Hill holder mode";
BA_ "GenSigTimeoutTime_DICO" SG_ 2566767627 HhMode 500;
BA_ "GenSigTimeoutTime_Ecolife2" SG_ 2566767627 HhMode 500;
BA_ "GenSigTimeoutTime_MulticS" SG_ 2566767627 HhMode 500;
BA_ "GenSigTimeoutTime_MulticS_" SG_ 2566767627 HhMode 500;
BA_ "GenSigTimeoutTime_NBM" SG_ 2566767627 HhMode 500;
BA_ "GenSigTimeoutTime_NBM__" SG_ 2566767627 HhMode 500;
BA_ "GenSigTimeoutTime_NBM___" SG_ 2566767627 HhMode 500;
BA_ "GenSigTimeoutTime_PCM" SG_ 2566767627 HhMode 500;
BA_ "GenSigTimeoutTime_SGW__" SG_ 2566767627 HhMode 500;
BA_ "GenSigTimeoutTime_VCM" SG_ 2566767627 HhMode 500;
BA_ "GenSigTimeoutTime_VCU_" SG_ 2566767627 HhMode 500;
BA_ "GenSigTimeoutTime_VMU" SG_ 2566767627 HhMode 500;
BA_ "SPN" SG_ 2566767627 HhMode 2912;
BA_ "CI_ParId" SG_ 2566841088 EngSpeedAtIdlePnt1 "188";
BA_ "CI_SigId" SG_ 2566841088 EngSpeedAtIdlePnt1 966;
BA_ "CI_SigName" SG_ 2566841088 EngSpeedAtIdlePnt1 "Engine Speed At Idle, Point 1";
BA_ "GenSigSendType" SG_ 2566841088 EngSpeedAtIdlePnt1 3;
BA_ "GenSigTimeoutTime_ADCU" SG_ 2566841088 EngSpeedAtIdlePnt1 25000;
BA_ "GenSigTimeoutTime_DiwaNXT" SG_ 2566841088 EngSpeedAtIdlePnt1 25000;
BA_ "GenSigTimeoutTime_DiwaNXT_MH" SG_ 2566841088 EngSpeedAtIdlePnt1 25000;
BA_ "GenSigTimeoutTime_PCM" SG_ 2566841088 EngSpeedAtIdlePnt1 25000;
BA_ "GenSigTimeoutTime_SGW__" SG_ 2566841088 EngSpeedAtIdlePnt1 25000;
BA_ "GenSigTimeoutTime_VCM_" SG_ 2566841088 EngSpeedAtIdlePnt1 25000;
BA_ "GenSigTimeoutTime_VCM__" SG_ 2566841088 EngSpeedAtIdlePnt1 25000;
BA_ "SPN" SG_ 2566841088 EngSpeedAtIdlePnt1 188;
BA_ "SigType" SG_ 2566841088 EngSpeedAtIdlePnt1 1;
BA_ "CI_ParId" SG_ 2566841088 EngSpeedAtHighIdlePnt6 "532";
BA_ "CI_SigId" SG_ 2566841088 EngSpeedAtHighIdlePnt6 976;
BA_ "CI_SigName" SG_ 2566841088 EngSpeedAtHighIdlePnt6 "Engine Speed At High Idle, Point 6";
BA_ "GenSigSendType" SG_ 2566841088 EngSpeedAtHighIdlePnt6 3;
BA_ "GenSigTimeoutTime_PCM" SG_ 2566841088 EngSpeedAtHighIdlePnt6 25000;
BA_ "GenSigTimeoutTime_SGW__" SG_ 2566841088 EngSpeedAtHighIdlePnt6 25000;
BA_ "GenSigTimeoutTime_VCM_" SG_ 2566841088 EngSpeedAtHighIdlePnt6 25000;
BA_ "GenSigTimeoutTime_VCM__" SG_ 2566841088 EngSpeedAtHighIdlePnt6 25000;
BA_ "SPN" SG_ 2566841088 EngSpeedAtHighIdlePnt6 532;
BA_ "SigType" SG_ 2566841088 EngSpeedAtHighIdlePnt6 1;
BA_ "CI_ParId" SG_ 2566841088 EngRefTrq "544";
BA_ "CI_SigId" SG_ 2566841088 EngRefTrq 978;
BA_ "CI_SigName" SG_ 2566841088 EngRefTrq "Engine Reference Torque";
BA_ "GenSigSendType" SG_ 2566841088 EngRefTrq 3;
BA_ "GenSigTimeoutTime_ADCU" SG_ 2566841088 EngRefTrq 25000;
BA_ "GenSigTimeoutTime_DiwaNXT" SG_ 2566841088 EngRefTrq 25000;
BA_ "GenSigTimeoutTime_DiwaNXT_MH" SG_ 2566841088 EngRefTrq 25000;
BA_ "GenSigTimeoutTime_EBS" SG_ 2566841088 EngRefTrq 25000;
BA_ "GenSigTimeoutTime_EBS___" SG_ 2566841088 EngRefTrq 25000;
BA_ "GenSigTimeoutTime_Ecolife2" SG_ 2566841088 EngRefTrq 25000;
BA_ "GenSigTimeoutTime_MulticS" SG_ 2566841088 EngRefTrq 25000;
BA_ "GenSigTimeoutTime_PCM" SG_ 2566841088 EngRefTrq 25000;
BA_ "GenSigTimeoutTime_SGW__" SG_ 2566841088 EngRefTrq 25000;
BA_ "GenSigTimeoutTime_VCM_" SG_ 2566841088 EngRefTrq 25000;
BA_ "GenSigTimeoutTime_VCM__" SG_ 2566841088 EngRefTrq 25000;
BA_ "SPN" SG_ 2566841088 EngRefTrq 544;
BA_ "SigType" SG_ 2566841088 EngRefTrq 1;
BA_ "CI_ParId" SG_ 2566841088 EngMaxMomOvrSpeedPnt7 "533";
BA_ "CI_SigId" SG_ 2566841088 EngMaxMomOvrSpeedPnt7 979;
BA_ "CI_SigName" SG_ 2566841088 EngMaxMomOvrSpeedPnt7 "Engine Maximum Momentary Override Speed, Point 7";
BA_ "GenSigSendType" SG_ 2566841088 EngMaxMomOvrSpeedPnt7 3;
BA_ "GenSigTimeoutTime_PCM" SG_ 2566841088 EngMaxMomOvrSpeedPnt7 25000;
BA_ "GenSigTimeoutTime_SGW__" SG_ 2566841088 EngMaxMomOvrSpeedPnt7 25000;
BA_ "GenSigTimeoutTime_VCM_" SG_ 2566841088 EngMaxMomOvrSpeedPnt7 25000;
BA_ "GenSigTimeoutTime_VCM__" SG_ 2566841088 EngMaxMomOvrSpeedPnt7 25000;
BA_ "SPN" SG_ 2566841088 EngMaxMomOvrSpeedPnt7 533;
BA_ "SigType" SG_ 2566841088 EngMaxMomOvrSpeedPnt7 1;
BA_ "CI_ParId" SG_ 2566841216 EngRefTrq_18FEE380 "544";
BA_ "CI_SigId" SG_ 2566841216 EngRefTrq_18FEE380 1008;
BA_ "CI_SigName" SG_ 2566841216 EngRefTrq_18FEE380 "Engine Reference Torque";
BA_ "GenSigTimeoutTime_ADCU" SG_ 2566841216 EngRefTrq_18FEE380 10000;
BA_ "GenSigTimeoutTime_MulticII" SG_ 2566841216 EngRefTrq_18FEE380 10000;
BA_ "GenSigTimeoutTime_MulticS_" SG_ 2566841216 EngRefTrq_18FEE380 10000;
BA_ "GenSigTimeoutTime_PCM" SG_ 2566841216 EngRefTrq_18FEE380 10000;
BA_ "GenSigTimeoutTime_SGW__" SG_ 2566841216 EngRefTrq_18FEE380 10000;
BA_ "GenSigTimeoutTime_VCU" SG_ 2566841216 EngRefTrq_18FEE380 10000;
BA_ "SPN" SG_ 2566841216 EngRefTrq_18FEE380 544;
BA_ "SigType" SG_ 2566841216 EngRefTrq_18FEE380 1;
BA_ "CI_ParId" SG_ 2566891081 FccuWifiantennasignalpower "IB833";
BA_ "CI_SigId" SG_ 2566891081 FccuWifiantennasignalpower 2905;
BA_ "CI_SigName" SG_ 2566891081 FccuWifiantennasignalpower "FCCU_WiFiAntennaSignalPower";
BA_ "GenSigTimeoutTime_PCM" SG_ 2566891081 FccuWifiantennasignalpower 5000;
BA_ "GenSigTimeoutTime_SGW__" SG_ 2566891081 FccuWifiantennasignalpower 5000;
BA_ "SigType" SG_ 2566891081 FccuWifiantennasignalpower 1;
BA_ "CI_ParId" SG_ 2566891081 FccuCombo2Temp "IB834";
BA_ "CI_SigId" SG_ 2566891081 FccuCombo2Temp 2906;
BA_ "CI_SigName" SG_ 2566891081 FccuCombo2Temp "FCCU_Combo2Temperature";
BA_ "GenSigTimeoutTime_PCM" SG_ 2566891081 FccuCombo2Temp 5000;
BA_ "GenSigTimeoutTime_SGW__" SG_ 2566891081 FccuCombo2Temp 5000;
BA_ "SigType" SG_ 2566891081 FccuCombo2Temp 1;
BA_ "CI_ParId" SG_ 2566891081 FccuCombo2Lckpositionvoltage "IB835";
BA_ "CI_SigId" SG_ 2566891081 FccuCombo2Lckpositionvoltage 2907;
BA_ "CI_SigName" SG_ 2566891081 FccuCombo2Lckpositionvoltage "FCCU_Combo2LockPositionVoltage";
BA_ "GenSigTimeoutTime_PCM" SG_ 2566891081 FccuCombo2Lckpositionvoltage 5000;
BA_ "GenSigTimeoutTime_SGW__" SG_ 2566891081 FccuCombo2Lckpositionvoltage 5000;
BA_ "SigType" SG_ 2566891081 FccuCombo2Lckpositionvoltage 1;
BA_ "CI_ParId" SG_ 2566889801 ChgIntrp "IB551";
BA_ "CI_SigId" SG_ 2566889801 ChgIntrp 4039;
BA_ "CI_SigName" SG_ 2566889801 ChgIntrp "Charge interrupt";
BA_ "GenSigTimeoutTime_PCM" SG_ 2566889801 ChgIntrp 25000;
BA_ "GenSigTimeoutTime_SGW__" SG_ 2566889801 ChgIntrp 25000;
BA_ "SigType" SG_ 2566889801 ChgIntrp 4;
BA_ "CI_ParId" SG_ 2566889801 EvsePresCur "IB556";
BA_ "CI_SigId" SG_ 2566889801 EvsePresCur 4044;
BA_ "CI_SigName" SG_ 2566889801 EvsePresCur "EVSE Present Current";
BA_ "GenSigTimeoutTime_PCM" SG_ 2566889801 EvsePresCur 25000;
BA_ "GenSigTimeoutTime_SGW__" SG_ 2566889801 EvsePresCur 25000;
BA_ "SigType" SG_ 2566889801 EvsePresCur 1;
BA_ "CI_ParId" SG_ 2566767966 EcuPn "2901";
BA_ "CI_SigId" SG_ 2566767966 EcuPn 10344;
BA_ "CI_SigName" SG_ 2566767966 EcuPn "ECU Part Number";
BA_ "GenSigTimeoutTime_PCM" SG_ 2566767966 EcuPn 5000;
BA_ "GenSigTimeoutTime_SGW__" SG_ 2566767966 EcuPn 5000;
BA_ "SPN" SG_ 2566767966 EcuPn 2901;
BA_ "SigType" SG_ 2566767966 EcuPn 8;
BA_ "CI_ParId" SG_ 2566767966 EcuSn "2902";
BA_ "CI_SigId" SG_ 2566767966 EcuSn 10345;
BA_ "CI_SigName" SG_ 2566767966 EcuSn "ECU Serial Number";
BA_ "GenSigTimeoutTime_PCM" SG_ 2566767966 EcuSn 5000;
BA_ "GenSigTimeoutTime_SGW__" SG_ 2566767966 EcuSn 5000;
BA_ "SPN" SG_ 2566767966 EcuSn 2902;
BA_ "SigType" SG_ 2566767966 EcuSn 8;
BA_ "CI_ParId" SG_ 2566767966 EcuLoc "2903";
BA_ "CI_SigId" SG_ 2566767966 EcuLoc 10346;
BA_ "CI_SigName" SG_ 2566767966 EcuLoc "ECU Location";
BA_ "GenSigTimeoutTime_PCM" SG_ 2566767966 EcuLoc 5000;
BA_ "GenSigTimeoutTime_SGW__" SG_ 2566767966 EcuLoc 5000;
BA_ "SPN" SG_ 2566767966 EcuLoc 2903;
BA_ "SigType" SG_ 2566767966 EcuLoc 8;
BA_ "CI_ParId" SG_ 2566767966 EcuManName "4304";
BA_ "CI_SigId" SG_ 2566767966 EcuManName 13534;
BA_ "CI_SigName" SG_ 2566767966 EcuManName "ECU Manufacturer Name";
BA_ "GenSigTimeoutTime_PCM" SG_ 2566767966 EcuManName 5000;
BA_ "GenSigTimeoutTime_SGW__" SG_ 2566767966 EcuManName 5000;
BA_ "SPN" SG_ 2566767966 EcuManName 4304;
BA_ "SigType" SG_ 2566767966 EcuManName 8;
BA_ "CI_ParId" SG_ 2566767900 EcuPn_18FDC51C "2901";
BA_ "CI_SigId" SG_ 2566767900 EcuPn_18FDC51C 10316;
BA_ "CI_SigName" SG_ 2566767900 EcuPn_18FDC51C "ECU Part Number";
BA_ "SPN" SG_ 2566767900 EcuPn_18FDC51C 2901;
BA_ "SigType" SG_ 2566767900 EcuPn_18FDC51C 8;
BA_ "CI_ParId" SG_ 2566767900 EcuSn_18FDC51C "2902";
BA_ "CI_SigId" SG_ 2566767900 EcuSn_18FDC51C 10317;
BA_ "CI_SigName" SG_ 2566767900 EcuSn_18FDC51C "ECU Serial Number";
BA_ "SPN" SG_ 2566767900 EcuSn_18FDC51C 2902;
BA_ "SigType" SG_ 2566767900 EcuSn_18FDC51C 8;
BA_ "CI_ParId" SG_ 2566767900 EcuLoc_18FDC51C "2903";
BA_ "CI_SigId" SG_ 2566767900 EcuLoc_18FDC51C 10318;
BA_ "CI_SigName" SG_ 2566767900 EcuLoc_18FDC51C "ECU Location";
BA_ "SPN" SG_ 2566767900 EcuLoc_18FDC51C 2903;
BA_ "SigType" SG_ 2566767900 EcuLoc_18FDC51C 8;
BA_ "CI_ParId" SG_ 2566767900 EcuType "2904";
BA_ "CI_SigId" SG_ 2566767900 EcuType 10319;
BA_ "CI_SigName" SG_ 2566767900 EcuType "ECU Type";
BA_ "SPN" SG_ 2566767900 EcuType 2904;
BA_ "SigType" SG_ 2566767900 EcuType 8;
BA_ "CI_ParId" SG_ 2566767900 EcuManName_18FDC51C "4304";
BA_ "CI_SigId" SG_ 2566767900 EcuManName_18FDC51C 10320;
BA_ "CI_SigName" SG_ 2566767900 EcuManName_18FDC51C "ECU Manufacturer Name";
BA_ "SPN" SG_ 2566767900 EcuManName_18FDC51C 4304;
BA_ "SigType" SG_ 2566767900 EcuManName_18FDC51C 8;
BA_ "CI_ParId" SG_ 2566767901 EcuPn_18FDC51D "2901";
BA_ "CI_SigId" SG_ 2566767901 EcuPn_18FDC51D 10323;
BA_ "CI_SigName" SG_ 2566767901 EcuPn_18FDC51D "ECU Part Number";
BA_ "SPN" SG_ 2566767901 EcuPn_18FDC51D 2901;
BA_ "SigType" SG_ 2566767901 EcuPn_18FDC51D 8;
BA_ "CI_ParId" SG_ 2566767901 EcuSn_18FDC51D "2902";
BA_ "CI_SigId" SG_ 2566767901 EcuSn_18FDC51D 10324;
BA_ "CI_SigName" SG_ 2566767901 EcuSn_18FDC51D "ECU Serial Number";
BA_ "SPN" SG_ 2566767901 EcuSn_18FDC51D 2902;
BA_ "SigType" SG_ 2566767901 EcuSn_18FDC51D 8;
BA_ "CI_ParId" SG_ 2566767901 EcuLoc_18FDC51D "2903";
BA_ "CI_SigId" SG_ 2566767901 EcuLoc_18FDC51D 10325;
BA_ "CI_SigName" SG_ 2566767901 EcuLoc_18FDC51D "ECU Location";
BA_ "SPN" SG_ 2566767901 EcuLoc_18FDC51D 2903;
BA_ "SigType" SG_ 2566767901 EcuLoc_18FDC51D 8;
BA_ "CI_ParId" SG_ 2566767901 EcuType_18FDC51D "2904";
BA_ "CI_SigId" SG_ 2566767901 EcuType_18FDC51D 10326;
BA_ "CI_SigName" SG_ 2566767901 EcuType_18FDC51D "ECU Type";
BA_ "SPN" SG_ 2566767901 EcuType_18FDC51D 2904;
BA_ "SigType" SG_ 2566767901 EcuType_18FDC51D 8;
BA_ "CI_ParId" SG_ 2566767901 EcuManName_18FDC51D "4304";
BA_ "CI_SigId" SG_ 2566767901 EcuManName_18FDC51D 10327;
BA_ "CI_SigName" SG_ 2566767901 EcuManName_18FDC51D "ECU Manufacturer Name";
BA_ "SPN" SG_ 2566767901 EcuManName_18FDC51D 4304;
BA_ "SigType" SG_ 2566767901 EcuManName_18FDC51D 8;
BA_ "CI_ParId" SG_ 2566849280 EngOverTemp "I254";
BA_ "CI_SigId" SG_ 2566849280 EngOverTemp 4055;
BA_ "CI_SigName" SG_ 2566849280 EngOverTemp "Engine Over Temperature";
BA_ "GenSigTimeoutTime_FMS4" SG_ 2566849280 EngOverTemp 500;
BA_ "GenSigTimeoutTime_MulticS" SG_ 2566849280 EngOverTemp 500;
BA_ "GenSigTimeoutTime_MulticS__" SG_ 2566849280 EngOverTemp 500;
BA_ "GenSigTimeoutTime_PCM" SG_ 2566849280 EngOverTemp 500;
BA_ "GenSigTimeoutTime_SGW__" SG_ 2566849280 EngOverTemp 500;
BA_ "CI_ParId" SG_ 2566849280 MaxVslSetp "I025";
BA_ "CI_SigId" SG_ 2566849280 MaxVslSetp 4056;
BA_ "CI_SigName" SG_ 2566849280 MaxVslSetp "Maximum Vehicle Speed Limit Setpoint";
BA_ "GenSigTimeoutTime_FMS4" SG_ 2566849280 MaxVslSetp 500;
BA_ "GenSigTimeoutTime_MulticS" SG_ 2566849280 MaxVslSetp 500;
BA_ "GenSigTimeoutTime_MulticS__" SG_ 2566849280 MaxVslSetp 500;
BA_ "GenSigTimeoutTime_PCM" SG_ 2566849280 MaxVslSetp 500;
BA_ "GenSigTimeoutTime_SGW__" SG_ 2566849280 MaxVslSetp 500;
BA_ "SigType" SG_ 2566849280 MaxVslSetp 1;
BA_ "CI_ParId" SG_ 2566849280 CabTilted "I028";
BA_ "CI_SigId" SG_ 2566849280 CabTilted 4061;
BA_ "CI_SigName" SG_ 2566849280 CabTilted "Cabin Tilted";
BA_ "GenSigTimeoutTime_FMS4" SG_ 2566849280 CabTilted 500;
BA_ "GenSigTimeoutTime_MulticS" SG_ 2566849280 CabTilted 500;
BA_ "GenSigTimeoutTime_NBM" SG_ 2566849280 CabTilted 500;
BA_ "GenSigTimeoutTime_PCM" SG_ 2566849280 CabTilted 500;
BA_ "GenSigTimeoutTime_SGW__" SG_ 2566849280 CabTilted 500;
BA_ "SigType" SG_ 2566849280 CabTilted 4;
BA_ "CI_ParId" SG_ 2566849280 EngOilPrsLow "I022";
BA_ "CI_SigId" SG_ 2566849280 EngOilPrsLow 4065;
BA_ "CI_SigName" SG_ 2566849280 EngOilPrsLow "Engine Oil Pressure Low";
BA_ "GenSigTimeoutTime_FMS4" SG_ 2566849280 EngOilPrsLow 500;
BA_ "GenSigTimeoutTime_MulticS" SG_ 2566849280 EngOilPrsLow 500;
BA_ "GenSigTimeoutTime_MulticS__" SG_ 2566849280 EngOilPrsLow 500;
BA_ "GenSigTimeoutTime_NBM" SG_ 2566849280 EngOilPrsLow 500;
BA_ "GenSigTimeoutTime_NBM___" SG_ 2566849280 EngOilPrsLow 500;
BA_ "GenSigTimeoutTime_PCM" SG_ 2566849280 EngOilPrsLow 500;
BA_ "GenSigTimeoutTime_SGW__" SG_ 2566849280 EngOilPrsLow 500;
BA_ "SigType" SG_ 2566849280 EngOilPrsLow 4;
BA_ "CI_ParId" SG_ 2566849280 EconMode "IS656";
BA_ "CI_SigId" SG_ 2566849280 EconMode 4066;
BA_ "CI_SigName" SG_ 2566849280 EconMode "Economy Mode";
BA_ "GenSigTimeoutTime_FMS4" SG_ 2566849280 EconMode 500;
BA_ "GenSigTimeoutTime_MulticS" SG_ 2566849280 EconMode 500;
BA_ "GenSigTimeoutTime_PCM" SG_ 2566849280 EconMode 500;
BA_ "GenSigTimeoutTime_SGW__" SG_ 2566849280 EconMode 500;
BA_ "SigType" SG_ 2566849280 EconMode 4;
BA_ "CI_ParId" SG_ 2566849280 EngOilTempHigh "I081";
BA_ "CI_SigId" SG_ 2566849280 EngOilTempHigh 4068;
BA_ "CI_SigName" SG_ 2566849280 EngOilTempHigh "Engine Oil Temperature High";
BA_ "GenSigTimeoutTime_FMS4" SG_ 2566849280 EngOilTempHigh 500;
BA_ "GenSigTimeoutTime_MulticS" SG_ 2566849280 EngOilTempHigh 500;
BA_ "GenSigTimeoutTime_MulticS__" SG_ 2566849280 EngOilTempHigh 500;
BA_ "GenSigTimeoutTime_PCM" SG_ 2566849280 EngOilTempHigh 500;
BA_ "GenSigTimeoutTime_SGW__" SG_ 2566849280 EngOilTempHigh 500;
BA_ "SigType" SG_ 2566849280 EngOilTempHigh 4;
BA_ "CI_ParId" SG_ 2364539904 EngTrqMode "899";
BA_ "CI_SigId" SG_ 2364539904 EngTrqMode 837;
BA_ "CI_SigName" SG_ 2364539904 EngTrqMode "Engine Torque Mode";
BA_ "GenSigTimeoutTime_ADCU" SG_ 2364539904 EngTrqMode 500;
BA_ "GenSigTimeoutTime_Ecolife2" SG_ 2364539904 EngTrqMode 500;
BA_ "GenSigTimeoutTime_PCM" SG_ 2364539904 EngTrqMode 500;
BA_ "GenSigTimeoutTime_SGW2" SG_ 2364539904 EngTrqMode 500;
BA_ "GenSigTimeoutTime_SGW__" SG_ 2364539904 EngTrqMode 500;
BA_ "GenSigTimeoutTime_VCM_" SG_ 2364539904 EngTrqMode 500;
BA_ "GenSigTimeoutTime_VCM__" SG_ 2364539904 EngTrqMode 500;
BA_ "SPN" SG_ 2364539904 EngTrqMode 899;
BA_ "CI_ParId" SG_ 2364539904 ActEngPcTrq "513";
BA_ "CI_SigId" SG_ 2364539904 ActEngPcTrq 840;
BA_ "CI_SigName" SG_ 2364539904 ActEngPcTrq "Actual Engine - Percent Torque";
BA_ "GenSigTimeoutTime_ADCU" SG_ 2364539904 ActEngPcTrq 500;
BA_ "GenSigTimeoutTime_EBS" SG_ 2364539904 ActEngPcTrq 500;
BA_ "GenSigTimeoutTime_EBS___" SG_ 2364539904 ActEngPcTrq 500;
BA_ "GenSigTimeoutTime_Ecolife2" SG_ 2364539904 ActEngPcTrq 500;
BA_ "GenSigTimeoutTime_FMS4" SG_ 2364539904 ActEngPcTrq 500;
BA_ "GenSigTimeoutTime_MulticS" SG_ 2364539904 ActEngPcTrq 500;
BA_ "GenSigTimeoutTime_NBM" SG_ 2364539904 ActEngPcTrq 500;
BA_ "GenSigTimeoutTime_PCM" SG_ 2364539904 ActEngPcTrq 500;
BA_ "GenSigTimeoutTime_SGW2" SG_ 2364539904 ActEngPcTrq 500;
BA_ "GenSigTimeoutTime_SGW__" SG_ 2364539904 ActEngPcTrq 500;
BA_ "GenSigTimeoutTime_VCM_" SG_ 2364539904 ActEngPcTrq 500;
BA_ "GenSigTimeoutTime_VCM__" SG_ 2364539904 ActEngPcTrq 500;
BA_ "SPN" SG_ 2364539904 ActEngPcTrq 513;
BA_ "SigType" SG_ 2364539904 ActEngPcTrq 1;
BA_ "CI_ParId" SG_ 2364539904 EngSpeed "190";
BA_ "CI_SigId" SG_ 2364539904 EngSpeed 841;
BA_ "CI_SigName" SG_ 2364539904 EngSpeed "Engine Speed";
BA_ "GenSigTimeoutTime_ADCU" SG_ 2364539904 EngSpeed 500;
BA_ "GenSigTimeoutTime_DTCO" SG_ 2364539904 EngSpeed 500;
BA_ "GenSigTimeoutTime_DiwaNXT_MH" SG_ 2364539904 EngSpeed 500;
BA_ "GenSigTimeoutTime_EBS" SG_ 2364539904 EngSpeed 500;
BA_ "GenSigTimeoutTime_EBS___" SG_ 2364539904 EngSpeed 500;
BA_ "GenSigTimeoutTime_ETS" SG_ 2364539904 EngSpeed 500;
BA_ "GenSigTimeoutTime_Ecolife2" SG_ 2364539904 EngSpeed 500;
BA_ "GenSigTimeoutTime_FMS4" SG_ 2364539904 EngSpeed 500;
BA_ "GenSigTimeoutTime_INTD" SG_ 2364539904 EngSpeed 500;
BA_ "GenSigTimeoutTime_IRCS" SG_ 2364539904 EngSpeed 500;
BA_ "GenSigTimeoutTime_MTCO" SG_ 2364539904 EngSpeed 500;
BA_ "GenSigTimeoutTime_MulticS" SG_ 2364539904 EngSpeed 500;
BA_ "GenSigTimeoutTime_MulticS__" SG_ 2364539904 EngSpeed 500;
BA_ "GenSigTimeoutTime_NBM" SG_ 2364539904 EngSpeed 500;
BA_ "GenSigTimeoutTime_NBM___" SG_ 2364539904 EngSpeed 500;
BA_ "GenSigTimeoutTime_PCM" SG_ 2364539904 EngSpeed 500;
BA_ "GenSigTimeoutTime_SGW2" SG_ 2364539904 EngSpeed 500;
BA_ "GenSigTimeoutTime_SGW__" SG_ 2364539904 EngSpeed 500;
BA_ "GenSigTimeoutTime_SIU" SG_ 2364539904 EngSpeed 500;
BA_ "GenSigTimeoutTime_TPMS" SG_ 2364539904 EngSpeed 500;
BA_ "GenSigTimeoutTime_VCM_" SG_ 2364539904 EngSpeed 500;
BA_ "GenSigTimeoutTime_VCM__" SG_ 2364539904 EngSpeed 500;
BA_ "SPN" SG_ 2364539904 EngSpeed 190;
BA_ "SigType" SG_ 2364539904 EngSpeed 1;
BA_ "CI_ParId" SG_ 2364539904 EngDemPcTrq "2432";
BA_ "CI_SigId" SG_ 2364539904 EngDemPcTrq 844;
BA_ "CI_SigName" SG_ 2364539904 EngDemPcTrq "Engine Demand - Percent Torque";
BA_ "GenSigTimeoutTime_PCM" SG_ 2364539904 EngDemPcTrq 500;
BA_ "GenSigTimeoutTime_SGW2" SG_ 2364539904 EngDemPcTrq 500;
BA_ "GenSigTimeoutTime_SGW__" SG_ 2364539904 EngDemPcTrq 500;
BA_ "GenSigTimeoutTime_VCM_" SG_ 2364539904 EngDemPcTrq 500;
BA_ "GenSigTimeoutTime_VCM__" SG_ 2364539904 EngDemPcTrq 500;
BA_ "SPN" SG_ 2364539904 EngDemPcTrq 2432;
BA_ "SigType" SG_ 2364539904 EngDemPcTrq 1;
VAL_ 2561132106 ValidHandBrake 0 "False" 1 "True" 2 "Reserved" 3 "Not available" ;
VAL_ 2561132106 BenefitHandBrake 0 "False" 1 "True" 2 "Reserved" 3 "Not available" ;
VAL_ 2561132362 EventHandBrake 0 "NoEvent" 1 "BadHandBrake" ;
VAL_ 2561132618 ValidHarshBraking 0 "False" 1 "True" 2 "Reserved" 3 "Not available" ;
VAL_ 2561132618 BenefitHarshBraking 0 "False" 1 "True" 2 "Reserved" 3 "Not available" ;
VAL_ 2561132874 EventHarshBraking 0 "NoEvent" 1 "HarshBrakingDetected" ;
VAL_ 2561133130 ValidHarshSteering 0 "False" 1 "True" 2 "Reserved" 3 "Not available" ;
VAL_ 2561133130 BenefitHarshSteering 0 "False" 1 "True" 2 "Reserved" 3 "Not available" ;
VAL_ 2561133386 EventHarshSteering 0 "NoEvent" 1 "HarshSteeringDetected" ;
VAL_ 2561133898 ValidInertia 0 "False" 1 "True" 2 "Reserved" 3 "Not available" ;
VAL_ 2561133898 BenefitInertia 0 "False" 1 "True" 2 "Reserved" 3 "Not available" ;
VAL_ 2561134154 EventInertia 0 "NoEvent" 1 "GoodInertia" 2 "BadInertia" 3 "GoodGasGas" 4 "DangerOfCollision" 5 "PunishingManeuver" ;
VAL_ 2561134154 StartReasonInertia 0 "NoReason" 1 "GasPedalReleased" 2 "CruiseControlDisabled" ;
VAL_ 2561134154 EndReasonInertia 0 "NoReason" 1 "BrakeAction" 2 "GasPedalPressed" 3 "CruiseControlEnabled" ;
VAL_ 2561134154 DangerOfCollisInertia 0 "False" 1 "True" 2 "Reserved" 3 "Not available" ;
VAL_ 2561134154 PunishingManeuvInertia 0 "False" 1 "True" 2 "Reserved" 3 "Not available" ;
VAL_ 2561134410 ValidInertiaPecc 0 "False" 1 "True" 2 "Reserved" 3 "Not available" ;
VAL_ 2561134410 BenefitInertiaPecc 0 "False" 1 "True" 2 "Reserved" 3 "Not available" ;
VAL_ 2561142090 ValidLateral 0 "False" 1 "True" 2 "Reserved" 3 "Not available" ;
VAL_ 2561142090 BenefitLateral 0 "False" 1 "True" 2 "Reserved" 3 "Not available" ;
VAL_ 2561134666 ValidLaneDpt 0 "False" 1 "True" 2 "Reserved" 3 "Not available" ;
VAL_ 2561134666 BenefitLaneDpt 0 "False" 1 "True" 2 "Reserved" 3 "Not available" ;
VAL_ 2561134922 EventLaneDpt 0 "NoEvent" 1 "LaneDepartEnabled" 2 "LaneDepartDisabled" 3 "LaneDepartTriggered" ;
VAL_ 2561142346 ValidLongitudinal 0 "False" 1 "True" 2 "Reserved" 3 "Not available" ;
VAL_ 2561142346 BenefitLongitudinal 0 "False" 1 "True" 2 "Reserved" 3 "Not available" ;
VAL_ 2561146186 ValidMois 0 "False" 1 "True" 2 "Reserved" 3 "Not available" ;
VAL_ 2561146186 BenefitMois 0 "False" 1 "True" 2 "Reserved" 3 "Not available" ;
VAL_ 2561135178 NotificationTextId 0 "NoText" 1 "AccelerationGood" 2 "AccelerationBad" 3 "INERTIA_GOODGASBRAKE" 4 "INERTIA_BADGASBRAKE" 5 "INERTIA_GOODGASGAS" 6 "PECC_ENABLED" 7 "PECC_DISABLED" 8 "STOP_GOOD" 9 "STOP_BAD" 10 "STOP_PANIC" 11 "RPM_GOOD" 12 "RPM_BADHIGH" 13 "RPM_BADLOW" 14 "RPM_GSIFAULT" 15 "AUXILIARYBRAKE_GOOD" 16 "AUXILIARYBRAKE_BAD" 17 "AUXILIARYBRAKE_DISABLEDTEMP" 18 "AUXILIARYBRAKE_DISABLEDMASS" 19 "TIRESAVING_BAG" 20 "ECOSWITCH_ENABLED" 21 "ECOSWITCH_DISABLED" 22 "LANEDEPARTURE_ENABLED" 23 "LANEDEPARTURE_DISABLED" 24 "LANEDEPARTURE_TRIGGERED" 25 "AEBS_ENABLED" 26 "AEBS_DISABLED" 27 "AEBS_TRIGGERED" 28 "ADAPTIVECRUISE_ENABLED" 29 "ADAPTIVECRUISE_DISABLED" 30 "HANDBRAKE_BAD" 31 "HARSHBRAKING_BAD" 32 "HARSHSTEERING_BAD" 33 "SAFEDISTANCE_BAD" 34 "STABILITY_BAD" 35 "TIRESAFETY_BAD" 36 "DAS_WARNING" 37 "AS_STOP" 38 "Reserved1" 39 "Reserved2" 40 "TRIP_INFO" 41 "TRIP_START" 42 "TRIP_END" ;
VAL_ 2561135434 OldDasStop 0 "False" 1 "True" 2 "Reserved" 3 "Not available" ;
VAL_ 2561135434 OldDasWarning 0 "False" 1 "True" 2 "Reserved" 3 "Not available" ;
VAL_ 2561135434 OldDasEnabled 0 "False" 1 "True" 2 "Reserved" 3 "Not available" ;
VAL_ 2561135690 ValidPecc 0 "False" 1 "True" 2 "Reserved" 3 "Not available" ;
VAL_ 2561135690 BenefitPecc 0 "False" 1 "True" 2 "Reserved" 3 "Not available" ;
VAL_ 2561135946 EventPecc 0 "NoEvent" 1 "PeccEnabled" 2 "PeccDisabled" ;
VAL_ 2561136202 ValidRadar 0 "False" 1 "True" 2 "Reserved" 3 "Not available" ;
VAL_ 2561136202 BenefitRadar 0 "False" 1 "True" 2 "Reserved" 3 "Not available" ;
VAL_ 2561136458 EventRadar 0 "NoEvent" 1 "UnsafeDistanceDetected" ;
VAL_ 2561136714 ValidRpm 0 "False" 1 "True" 2 "Reserved" 3 "Not available" ;
VAL_ 2561136714 BenefitRpm 0 "False" 1 "True" 2 "Reserved" 3 "Not available" ;
VAL_ 2561136970 EventRPM 0 "NoEvent" 1 "GoodRPM_Style" 2 "BadRPM_StyleHigh" 3 "BadRPM_StyleLow" 4 "BadRPM_GsiFault" ;
VAL_ 2561136970 RPMLevel 0 "Low" 1 "Middle" 2 "High" ;
VAL_ 2561136970 RPMZone 0 "Low" 1 "Middle" 2 "High" ;
VAL_ 2561136970 TorqueLevel 0 "Low" 1 "High" ;
VAL_ 2561145162 ValidSafeDistance 0 "False" 1 "True" 2 "Reserved" 3 "Not available" ;
VAL_ 2561145162 BenefitSafeDistance 0 "False" 1 "True" 2 "Reserved" 3 "Not available" ;
VAL_ 2561145418 ValidSafePosition 0 "False" 1 "True" 2 "Reserved" 3 "Not available" ;
VAL_ 2561145418 BenefitSafePosition 0 "False" 1 "True" 2 "Reserved" 3 "Not available" ;
VAL_ 2561137226 ValidSafety 0 "False" 1 "True" 2 "Reserved" 3 "Not available" ;
VAL_ 2561137226 BenefitSafety 0 "False" 1 "True" 2 "Reserved" 3 "Not available" ;
VAL_ 2561137482 ValidTireSafety 0 "False" 1 "True" 2 "Reserved" 3 "Not available" ;
VAL_ 2561137482 BenefitTireSafety 0 "False" 1 "True" 2 "Reserved" 3 "Not available" ;
VAL_ 2561137738 EventTireSafety 0 "NoEvent" 1 "UnsafeTirePressure" ;
VAL_ 2561144650 ValidSlowManeuver 0 "False" 1 "True" 2 "Reserved" 3 "Not available" ;
VAL_ 2561144650 BenefitSlowManeuver 0 "False" 1 "True" 2 "Reserved" 3 "Not available" ;
VAL_ 2561144394 ValidSpeed 0 "False" 1 "True" 2 "Reserved" 3 "Not available" ;
VAL_ 2561144394 BenefitSpeed 0 "False" 1 "True" 2 "Reserved" 3 "Not available" ;
VAL_ 2566875466 HarshRightTurn 0 "Inactive" 1 "Active" 2 "Error" 3 "NA" ;
VAL_ 2566875466 HarshLeftTurn 0 "Inactive" 1 "Active" 2 "Error" 3 "NA" ;
VAL_ 2566875466 HarshBrk 0 "Inactive" 1 "Active" 2 "Error" 3 "NA" ;
VAL_ 2566875466 HarshAccel 0 "Inactive" 1 "Active" 2 "Error" 3 "NA" ;
VAL_ 2566875466 HarshVertAccel_UP 0 "Inactive" 1 "Active" 2 "Error" 3 "NA" ;
VAL_ 2566875466 HarshVertAccel_Down 0 "Inactive" 1 "Active" 2 "Error" 3 "NA" ;
VAL_ 2566875466 MaxSpeedExc 0 "Inactive" 1 "Active" 2 "Error" 3 "NA" ;
VAL_ 2566875466 AccPedPrsTooLong 0 "Inactive" 1 "Active" 2 "Error" 3 "NA" ;
VAL_ 2561138250 TripStarted 0 "False" 1 "True" 2 "Reserved" 3 "Not available" ;
VAL_ 2561138250 TripEnded 0 "False" 1 "True" 2 "Reserved" 3 "Not available" ;
VAL_ 2561138250 TripActive 0 "False" 1 "True" 2 "Reserved" 3 "Not available" ;
VAL_ 2561138250 TripEndReason 0 "NotEnded" 1 "KeyOff" 2 "DriverIDChanged" 3 "UserReset" 4 "TelemAppReset" ;
VAL_ 2561138506 ValidStabilityControl 0 "False" 1 "True" 2 "Reserved" 3 "Not available" ;
VAL_ 2561138506 BenefitStabilityControl 0 "False" 1 "True" 2 "Reserved" 3 "Not available" ;
VAL_ 2561138762 EventStabilityControl 0 "NoEvent" 1 "DrivingDetected" ;
VAL_ 2561139018 ValidStop 0 "False" 1 "True" 2 "Reserved" 3 "Not available" ;
VAL_ 2561139018 BenefitStop 0 "False" 1 "True" 2 "Reserved" 3 "Not available" ;
VAL_ 2561139274 EventStop 0 "NoEvent" 1 "GoodStop" 2 "BadStop" 3 "PanicStop" ;
VAL_ 2561139274 PanicBrakeState 0 "PanicBrakeAllowed" 1 "PanicBrakeNotAllowed" 2 "PanicBrakeDetected" ;
VAL_ 2561141066 EventValid 0 "False" 1 "True" 2 "Reserved" 3 "Not available" ;
VAL_ 2561139530 ValidTire 0 "False" 1 "True" 2 "Reserved" 3 "Not available" ;
VAL_ 2561139530 BenefitTire 0 "False" 1 "True" 2 "Reserved" 3 "Not available" ;
VAL_ 2561139786 EventTireSaving 0 "NoEvent" 1 "WastefulTirePressure" ;
VAL_ 2561144906 ValidVehicleControl 0 "False" 1 "True" 2 "Reserved" 3 "Not available" ;
VAL_ 2561144906 BenefitVehicleControl 0 "False" 1 "True" 2 "Reserved" 3 "Not available" ;
VAL_ 2561142602 ValidVertical 0 "False" 1 "True" 2 "Reserved" 3 "Not available" ;
VAL_ 2561142602 BenefitVertical 0 "False" 1 "True" 2 "Reserved" 3 "Not available" ;
VAL_ 2565865739 AsrEngCtrlActv 0 "Passive but installed" 1 "Active" 2 "Reserved" 3 "Not Available" ;
VAL_ 2565865739 AsrBrkCtrlActv 0 "Passive but installed" 1 "Active" 2 "Reserved" 3 "Not Available" ;
VAL_ 2565865739 AbsActv 0 "Passive but installed" 1 "Active" 2 "Reserved" 3 "Not Available" ;
VAL_ 2565865739 AbsFullyOp 0 "Not Fully Operational" 1 "Fully Operational" 2 "Reserved" 3 "Not Available" ;
VAL_ 2565865739 Atc_AsrInfoSig 0 "Off" 1 "On" 2 "Reserved" 3 "Take no action" ;
VAL_ 2633935883 BrkLinRemFaL 0 "Totally worn linings" 250 "New brake linings" 254 "Error" 255 "Not Available" ;
VAL_ 2633935883 BrkLinRemFaR 0 "Totally worn linings" 250 "New brake linings" 254 "Error" 255 "Not Available" ;
VAL_ 2633935883 BrkLinRemRa1L 0 "Totally worn linings" 250 "New brake linings" 254 "Error" 255 "Not Available" ;
VAL_ 2633935883 BrkLinRemRa1R 0 "Totally worn linings" 250 "New brake linings" 254 "Error" 255 "Not Available" ;
VAL_ 2633935883 BrkLinRemRa2L 0 "Totally worn linings" 250 "New brake linings" 254 "Error" 255 "Not Available" ;
VAL_ 2633935883 BrkLinRemRa2R 0 "Totally worn linings" 250 "New brake linings" 254 "Error" 255 "Not Available" ;
VAL_ 2566767627 HaltBrkMode 0 "Inactive" 1 "Active" 2 "Active, but not functioning" 3 "Not defined" 4 "Not defined" 5 "Not defined" 6 "Not functional" 7 "Not Available" ;
VAL_ 2566767627 HhMode 0 "Inactive" 1 "Active" 2 "Active, will change to inactive" 3 "Active, may activate park brake" 4 "Reserved" 5 "Reserved" 6 "Hill holder not functional" 7 "Not Available" ;
VAL_ 2566889801 ChgIntrp 0 "Not Interrupt" 1 "Charge Interrupt" 2 "Error" 3 "Unavailable" ;
VAL_ 2566849280 EngOverTemp 0 "No warning" 1 "Prewarning" 2 "Warning" ;
VAL_ 2566849280 CabTilted 0 "Upright" 1 "Tilted" 3 "Not Available" ;
VAL_ 2566849280 EngOilPrsLow 0 "Normal" 1 "Below operating range" 2 "Error" 3 "Not Available" ;
VAL_ 2566849280 EconMode 0 "Off" 1 "On" ;
VAL_ 2566849280 EngOilTempHigh 0 "Normal" 1 "Above operating range" 3 "Not Available" ;
VAL_ 2364539904 EngTrqMode 0 "Low idle / No request" 1 "APP/operator selection" 2 "Cruise control" 3 "PTO governor" 4 "Road speed governor" 5 "ASR control" 6 "Transmission control" 7 "ABS control" 8 "Torque limiting" 9 "High speed governor" 10 "Braking system" 11 "Remote accelerator" 12 "Service procedure" 13 "not defined" 14 "Other" 15 "Not Available" ;
VAL_ 2364539904 ActEngPcTrq 254 "Error" 255 "Not_available" ;
VAL_ 2364539904 EngSpeed 65024 "Error" 65535 "Not_Available" ;
VAL_ 2364539904 EngDemPcTrq 254 "Error" 255 "Not_available" ;
